AUTOSAR XML (schema 4-2-1)
package /MICROSAR/Dcm_swc
  mode declaration group DcmControlDtcSetting: category=EXPLICIT_ORDER, initial-mode=ENABLEDTCSETTING, on-transition-value=2
    mode ENABLEDTCSETTING: value=0
    mode DISABLEDTCSETTING: value=1
  mode declaration group DcmDiagnosticSessionControl: category=EXPLICIT_ORDER, initial-mode=DefaultSession, on-transition-value=255
    4 x mode:
      DefaultSession: value=1
      ProgrammingSession: value=2
      ExtendedSession: value=3
      NexteerSession: value=126
  mode declaration group BswMEcuResetMod: initial-mode=EcuResetDisabled
    mode EcuResetDisabled
    mode EcuResetEnabled
    mode EcuResetStarted
  data type mapping set DcmMappingSet  # Contains mapping for ModeDeclarationGroups which are provided by Dcm.
    mode-request-type-maps:
      implementation-data-type=Dcm_ControlDtcSettingType, mode-group=DcmControlDtcSetting
      implementation-data-type=Dcm_DiagnosticSessionControlType, mode-group=DcmDiagnosticSessionControl
      implementation-data-type=BswM_BswMEcuResetMod, mode-group=BswMEcuResetMod
package /MICROSAR/Dcm_swc/DataTypes
  32 x impl type:
    Dcm_ConfirmationStatusType: compu {0=DCM_RES_POS_OK, 1=DCM_RES_POS_NOT_OK, 2=DCM_RES_NEG_OK, 3=DCM_RES_NEG_NOT_OK}, implementation-data-type=uint8
    Dcm_OpStatusType: compu {0=DCM_INITIAL, 1=DCM_PENDING, 2=DCM_CANCEL, 3=DCM_FORCE_RCRRP_OK, 64=DCM_FORCE_RCRRP_NOT_OK}, implementation-data-type=uint8
    Dcm_NegativeResponseCodeType: compu {0=DCM_E_POSITIVERESPONSE, 16=DCM_E_GENERALREJECT, 17=DCM_E_SERVICENOTSUPPORTED, 18=DCM_E_SUBFUNCTIONNOTSUPPORTED, 19=DCM_E_INCORRECTMESSAGELENGTHORINVALIDFORMAT, 20=DCM_E_RESPONSETOOLONG, 33=DCM_E_BUSYREPEATREQUEST, 34=DCM_E_CONDITIONSNOTCORRECT, 36=DCM_E_REQUESTSEQUENCEERROR, 37=DCM_E_NORESPONSEFROMSUBNETCOMPONENT, 38=DCM_E_FAILUREPREVENTSEXECUTIONOFREQUESTEDACTION, 49=DCM_E_REQUESTOUTOFRANGE, 51=DCM_E_SECURITYACCESSDENIED, 53=DCM_E_INVALIDKEY, 54=DCM_E_EXCEEDNUMBEROFATTEMPTS, 55=DCM_E_REQUIREDTIMEDELAYNOTEXPIRED, 112=DCM_E_UPLOADDOWNLOADNOTACCEPTED, 113=DCM_E_TRANSFERDATASUSPENDED, 114=DCM_E_GENERALPROGRAMMINGFAILURE, 115=DCM_E_WRONGBLOCKSEQUENCECOUNTER, 120=DCM_E_REQUESTCORRECTLYRECEIVEDRESPONSEPENDING, 126=DCM_E_SUBFUNCTIONNOTSUPPORTEDINACTIVESESSION, 127=DCM_E_SERVICENOTSUPPORTEDINACTIVESESSION, 129=DCM_E_RPMTOOHIGH, 130=DCM_E_RPMTOOLOW, 131=DCM_E_ENGINEISRUNNING, 132=DCM_E_ENGINEISNOTRUNNING, 133=DCM_E_ENGINERUNTIMETOOLOW, 134=DCM_E_TEMPERATURETOOHIGH, 135=DCM_E_TEMPERATURETOOLOW, 136=DCM_E_VEHICLESPEEDTOOHIGH, 137=DCM_E_VEHICLESPEEDTOOLOW, 138=DCM_E_THROTTLE_PEDALTOOHIGH, 139=DCM_E_THROTTLE_PEDALTOOLOW, 140=DCM_E_TRANSMISSIONRANGENOTINNEUTRAL, 141=DCM_E_TRANSMISSIONRANGENOTINGEAR, 143=DCM_E_BRAKESWITCH_NOTCLOSED, 144=DCM_E_SHIFTERLEVERNOTINPARK, 145=DCM_E_TORQUECONVERTERCLUTCHLOCKED, 146=DCM_E_VOLTAGETOOHIGH, 147=DCM_E_VOLTAGETOOLOW, 240..249=DCM_E_VMSCNC_0..DCM_E_VMSCNC_9, 250=DCM_E_VMSCNC_A, 251=DCM_E_VMSCNC_B, 252=DCM_E_VMSCNC_C, 253=DCM_E_VMSCNC_D, 254=DCM_E_VMSCNC_E}, implementation-data-type=uint8
    Dcm_ProtocolType: compu {0=DCM_OBD_ON_CAN, 1=DCM_OBD_ON_FLEXRAY, 2=DCM_OBD_ON_IP, 3=DCM_UDS_ON_CAN, 4=DCM_UDS_ON_FLEXRAY, 5=DCM_UDS_ON_IP, 12=DCM_NO_ACTIVE_PROTOCOL, 240..254=DCM_SUPPLIER_1..DCM_SUPPLIER_15}, implementation-data-type=uint8
    Dcm_RequestKindType: compu {0=DCM_REQ_KIND_NONE, 1=DCM_REQ_KIND_EXTERNAL, 2=DCM_REQ_KIND_ROE}, implementation-data-type=uint8
    Dem_DTCKindType: compu {1=DEM_DTC_KIND_ALL_DTCS, 2=DEM_DTC_KIND_EMISSION_REL_DTCS}, implementation-data-type=uint8
    Dem_DTCGroupType: range raw 0..16777215, implementation-data-type=uint32
    Dem_DTCOriginType: compu {1=DEM_DTC_ORIGIN_PRIMARY_MEMORY, 2=DEM_DTC_ORIGIN_MIRROR_MEMORY, 3=DEM_DTC_ORIGIN_PERMANENT_MEMORY, 4=DEM_DTC_ORIGIN_SECONDARY_MEMORY}, implementation-data-type=uint8
    Dcm_ControlDtcSettingType: compu {0=DCM_ENUM_ENABLEDTCSETTING, 1=DCM_ENUM_DISABLEDTCSETTING}, implementation-data-type=uint8
    Dcm_CommunicationModeType: compu {0=DCM_ENABLE_RX_TX_NORM, 1=DCM_ENABLE_RX_DISABLE_TX_NORM, 2=DCM_DISABLE_RX_ENABLE_TX_NORM, 3=DCM_DISABLE_RX_TX_NORMAL, 4=DCM_ENABLE_RX_TX_NM, 5=DCM_ENABLE_RX_DISABLE_TX_NM, 6=DCM_DISABLE_RX_ENABLE_TX_NM, 7=DCM_DISABLE_RX_TX_NM, 8=DCM_ENABLE_RX_TX_NORM_NM, 9=DCM_ENABLE_RX_DISABLE_TX_NORM_NM, 10=DCM_DISABLE_RX_ENABLE_TX_NORM_NM, 11=DCM_DISABLE_RX_TX_NORM_NM}, implementation-data-type=uint8
    Dcm_Data24ByteType: category=ARRAY, sw-calibration-access=READ-ONLY
      element Dcm_Data24ByteTypeElement: array-size=24, array-size-semantics=FIXED-SIZE, implementation-data-type=uint8
    Dcm_Data4ByteType: category=ARRAY, sw-calibration-access=READ-ONLY
      element Dcm_Data4ByteTypeElement: array-size=4, array-size-semantics=FIXED-SIZE, implementation-data-type=uint8
    Dcm_Data1ByteType: category=ARRAY, sw-calibration-access=READ-ONLY
      element Dcm_Data1ByteTypeElement: array-size=1, array-size-semantics=FIXED-SIZE, implementation-data-type=uint8
    Dcm_Data16ByteType: category=ARRAY, sw-calibration-access=READ-ONLY
      element Dcm_Data16ByteTypeElement: array-size=16, array-size-semantics=FIXED-SIZE, implementation-data-type=uint8
    Dcm_Data1024ByteType: category=ARRAY, sw-calibration-access=READ-ONLY
      element Dcm_Data1024ByteTypeElement: array-size=1024, array-size-semantics=FIXED-SIZE, implementation-data-type=uint8
    Dcm_Data1028ByteType: category=ARRAY, sw-calibration-access=READ-ONLY
      element Dcm_Data1028ByteTypeElement: array-size=1028, array-size-semantics=FIXED-SIZE, implementation-data-type=uint8
    Dcm_Data12ByteType: category=ARRAY, sw-calibration-access=READ-ONLY
      element Dcm_Data12ByteTypeElement: array-size=12, array-size-semantics=FIXED-SIZE, implementation-data-type=uint8
    Dcm_Data18ByteType: category=ARRAY, sw-calibration-access=READ-ONLY
      element Dcm_Data18ByteTypeElement: array-size=18, array-size-semantics=FIXED-SIZE, implementation-data-type=uint8
    Dcm_Data64ByteType: category=ARRAY, sw-calibration-access=READ-ONLY
      element Dcm_Data64ByteTypeElement: array-size=64, array-size-semantics=FIXED-SIZE, implementation-data-type=uint8
    Dcm_Data2ByteType: category=ARRAY, sw-calibration-access=READ-ONLY
      element Dcm_Data2ByteTypeElement: array-size=2, array-size-semantics=FIXED-SIZE, implementation-data-type=uint8
    Dcm_SesCtrlType: compu {1=DCM_DEFAULT_SESSION, 2=DCM_PROGRAMMING_SESSION, 3=DCM_EXTENDED_DIAGNOSTIC_SESSION, 126=DCM_NexteerSession}, implementation-data-type=uint8
    Dcm_DiagnosticSessionControlType: compu {1=DCM_ENUM_DefaultSession, 2=DCM_ENUM_ProgrammingSession, 3=DCM_ENUM_ExtendedSession, 126=DCM_ENUM_NexteerSession}, implementation-data-type=uint8
    Dcm_Data3ByteType: category=ARRAY, sw-calibration-access=READ-ONLY
      element Dcm_Data3ByteTypeElement: array-size=3, array-size-semantics=FIXED-SIZE, implementation-data-type=uint8
    Dcm_Data7ByteType: category=ARRAY, sw-calibration-access=READ-ONLY
      element Dcm_Data7ByteTypeElement: array-size=7, array-size-semantics=FIXED-SIZE, implementation-data-type=uint8
    Dcm_Data25ByteType: category=ARRAY, sw-calibration-access=READ-ONLY
      element Dcm_Data25ByteTypeElement: array-size=25, array-size-semantics=FIXED-SIZE, implementation-data-type=uint8
    Dcm_Data40ByteType: category=ARRAY, sw-calibration-access=READ-ONLY
      element Dcm_Data40ByteTypeElement: array-size=40, array-size-semantics=FIXED-SIZE, implementation-data-type=uint8
    Dcm_Data20ByteType: category=ARRAY, sw-calibration-access=READ-ONLY
      element Dcm_Data20ByteTypeElement: array-size=20, array-size-semantics=FIXED-SIZE, implementation-data-type=uint8
    Dcm_Data10ByteType: category=ARRAY, sw-calibration-access=READ-ONLY
      element Dcm_Data10ByteTypeElement: array-size=10, array-size-semantics=FIXED-SIZE, implementation-data-type=uint8
    Dcm_Data11ByteType: category=ARRAY, sw-calibration-access=READ-ONLY
      element Dcm_Data11ByteTypeElement: array-size=11, array-size-semantics=FIXED-SIZE, implementation-data-type=uint8
    Dcm_Data8ByteType: category=ARRAY, sw-calibration-access=READ-ONLY
      element Dcm_Data8ByteTypeElement: array-size=8, array-size-semantics=FIXED-SIZE, implementation-data-type=uint8
    Dcm_SecLevelType: compu {0=DCM_SEC_LEV_LOCKED, 1=DCM_SEC_LEV_L1, 2=DCM_SEC_LEV_L2}, implementation-data-type=uint8
    Dcm_Data159ByteType: category=ARRAY, sw-calibration-access=READ-ONLY
      element Dcm_Data159ByteTypeElement: array-size=159, array-size-semantics=FIXED-SIZE, implementation-data-type=uint8
package /MICROSAR/Dcm_swc/Interfaces
  mode switch interface DcmControlDtcSetting: is-service=true, service-kind=DIAGNOSTIC-COMMUNICATION-MANAGER
    mode group DcmControlDtcSetting: type=DcmControlDtcSetting
  mode switch interface DcmDiagnosticSessionControl: is-service=true, service-kind=DIAGNOSTIC-COMMUNICATION-MANAGER
    mode group DcmDiagnosticSessionControl: type=DcmDiagnosticSessionControl
  100 x client server interface, all with is-service=true, service-kind=DIAGNOSTIC-COMMUNICATION-MANAGER:
    DCMServices
      7 x operation:
        GetActiveProtocol: possible-error=E_OK
          arg ActiveProtocol: type=Dcm_ProtocolType, direction=OUT
        GetSesCtrlType: possible-error=E_OK
          arg SesCtrlType: type=Dcm_SesCtrlType, direction=OUT
        ResetToDefaultSession: possible-error=E_OK
        SetActiveDiagnostic: possible-error=E_OK
          arg active: type=boolean, direction=IN
        GetRequestKind: possible-error=DCMServices/E_NOT_OK
          arg TesterSourceAddress: type=uint16, direction=IN
          arg RequestKind: type=Dcm_RequestKindType, direction=OUT
        GetSecurityLevel: possible-error=E_OK
          arg SecLevel: type=Dcm_SecLevelType, direction=OUT
        GetSecurityLevelFixedBytes: possible-error=[DCMServices/E_NOT_OK, DCM_E_BUFFERTOOLOW]
          arg SecLevel: type=Dcm_SecLevelType, direction=IN
          arg FixedBytes: type=Dcm_Data12ByteType, direction=OUT
          arg BufferSize: type=uint8, direction=INOUT
      error E_OK: error-code=0
      error E_NOT_OK: error-code=1
      error DCM_E_BUFFERTOOLOW: error-code=42
    CallbackDCMRequestServices
      operation StartProtocol: possible-error=[CallbackDCMRequestServices/E_NOT_OK, E_PROTOCOL_NOT_ALLOWED]
        arg ProtocolID: type=Dcm_ProtocolType, direction=IN
      error E_NOT_OK: error-code=1
      error E_PROTOCOL_NOT_ALLOWED: error-code=5
    DataServices_Data_Dummy
      5 x operation, all with possible-error=[DataServices_Data_Dummy/E_NOT_OK, DataServices_Data_Dummy/DCM_E_PENDING]:
        ReadData
          arg OpStatus: type=Dcm_OpStatusType, direction=IN
          arg Data: type=Dcm_Data1ByteType, direction=OUT
        ReadDataLength
          arg OpStatus: type=Dcm_OpStatusType, direction=IN
          arg DataLength: type=uint16, direction=OUT
        WriteData
          4 x arg:
            Data: type=Dcm_Data1ByteType, direction=IN
            DataLength: type=uint16, direction=IN
            OpStatus: type=Dcm_OpStatusType, direction=IN
            ErrorCode: type=Dcm_NegativeResponseCodeType, direction=OUT
        ReturnControlToECU
          arg OpStatus: type=Dcm_OpStatusType, direction=IN
          arg ErrorCode: type=Dcm_NegativeResponseCodeType, direction=OUT
        ShortTermAdjustment
          4 x arg:
            Data: type=Dcm_Data1ByteType, direction=IN
            DataLength: type=uint16, direction=IN
            OpStatus: type=Dcm_OpStatusType, direction=IN
            ErrorCode: type=Dcm_NegativeResponseCodeType, direction=OUT
      error E_NOT_OK: error-code=1
      error DCM_E_PENDING: error-code=10
    DataServices_DIDRange_NexteerDidRangeFD00toFD39
      operation ReadDidData: possible-error=[DataServices_DIDRange_NexteerDidRangeFD00toFD39/E_NOT_OK, DataServices_DIDRange_NexteerDidRangeFD00toFD39/DCM_E_PENDING]
        5 x arg:
          DID: type=uint16, direction=IN
          Data: type=Dcm_Data1024ByteType, direction=OUT
          OpStatus: type=Dcm_OpStatusType, direction=IN
          DataLength: type=uint16, direction=OUT
          ErrorCode: type=Dcm_NegativeResponseCodeType, direction=OUT
      operation WriteDidData: possible-error=[DataServices_DIDRange_NexteerDidRangeFD00toFD39/E_NOT_OK, DataServices_DIDRange_NexteerDidRangeFD00toFD39/DCM_E_PENDING]
        5 x arg:
          DID: type=uint16, direction=IN
          Data: type=Dcm_Data1024ByteType, direction=IN
          OpStatus: type=Dcm_OpStatusType, direction=IN
          DataLength: type=uint16, direction=IN
          ErrorCode: type=Dcm_NegativeResponseCodeType, direction=OUT
      error E_NOT_OK: error-code=1
      error DCM_E_PENDING: error-code=10
    DataServices_DIDRange_NexteerDidRangeFD43toFEFF
      operation ReadDidData: possible-error=[DataServices_DIDRange_NexteerDidRangeFD43toFEFF/E_NOT_OK, DataServices_DIDRange_NexteerDidRangeFD43toFEFF/DCM_E_PENDING]
        5 x arg:
          DID: type=uint16, direction=IN
          Data: type=Dcm_Data1024ByteType, direction=OUT
          OpStatus: type=Dcm_OpStatusType, direction=IN
          DataLength: type=uint16, direction=OUT
          ErrorCode: type=Dcm_NegativeResponseCodeType, direction=OUT
      operation WriteDidData: possible-error=[DataServices_DIDRange_NexteerDidRangeFD43toFEFF/E_NOT_OK, DataServices_DIDRange_NexteerDidRangeFD43toFEFF/DCM_E_PENDING]
        5 x arg:
          DID: type=uint16, direction=IN
          Data: type=Dcm_Data1024ByteType, direction=IN
          OpStatus: type=Dcm_OpStatusType, direction=IN
          DataLength: type=uint16, direction=IN
          ErrorCode: type=Dcm_NegativeResponseCodeType, direction=OUT
      error E_NOT_OK: error-code=1
      error DCM_E_PENDING: error-code=10
    DcmIf
      operation DcmEnableDTCSetting: possible-error=[DEM_CONTROL_DTC_SETTING_N_OK, DEM_CONTROL_DTC_WRONG_DTCGROUP]
        arg DTCGroup: type=Dem_DTCGroupType, direction=IN
        arg DTCKind: type=Dem_DTCKindType, direction=IN
      operation DcmGetExtendedDataRecordByDTC: possible-error=[DEM_RECORD_WRONG_DTC, DEM_RECORD_WRONG_DTCORIGIN, DEM_RECORD_WRONG_NUMBER, DEM_RECORD_WRONG_BUFFERSIZE, DEM_RECORD_PENDING]
        5 x arg:
          DTC: type=uint32, direction=IN
          DTCOrigin: type=Dem_DTCOriginType, direction=IN
          ExtendedDataNumber: type=uint8, direction=IN
          DestBuffer: type=uint8, direction=OUT
          BufSize: type=uint16, direction=INOUT
      7 x error:
        DEM_CONTROL_DTC_SETTING_N_OK: error-code=1
        DEM_CONTROL_DTC_WRONG_DTCGROUP: error-code=2
        DEM_RECORD_WRONG_DTC: error-code=1
        DEM_RECORD_WRONG_DTCORIGIN: error-code=2
        DEM_RECORD_WRONG_NUMBER: error-code=3
        DEM_RECORD_WRONG_BUFFERSIZE: error-code=4
        DEM_RECORD_PENDING: error-code=5
    RoutineServices_RTN_Nexteer_FD70_Clear_Nexteer_Trouble_Codes
      operation Start: possible-error=[RoutineServices_RTN_Nexteer_FD70_Clear_Nexteer_Trouble_Codes/E_NOT_OK, RoutineServices_RTN_Nexteer_FD70_Clear_Nexteer_Trouble_Codes/DCM_E_PENDING, RoutineServices_RTN_Nexteer_FD70_Clear_Nexteer_Trouble_Codes/DCM_E_FORCE_RCRRP]
        arg OpStatus: type=Dcm_OpStatusType, direction=IN
        arg ErrorCode: type=Dcm_NegativeResponseCodeType, direction=OUT
      error E_NOT_OK: error-code=1
      error DCM_E_PENDING: error-code=10
      error DCM_E_FORCE_RCRRP: error-code=12
    RoutineServices_RTN_Nexteer_FDF0_Current_Gain_Auto_Trim
      operation Start: possible-error=[RoutineServices_RTN_Nexteer_FDF0_Current_Gain_Auto_Trim/E_NOT_OK, RoutineServices_RTN_Nexteer_FDF0_Current_Gain_Auto_Trim/DCM_E_PENDING, RoutineServices_RTN_Nexteer_FDF0_Current_Gain_Auto_Trim/DCM_E_FORCE_RCRRP]
        arg OpStatus: type=Dcm_OpStatusType, direction=IN
        arg ErrorCode: type=Dcm_NegativeResponseCodeType, direction=OUT
      operation RequestResults: possible-error=[RoutineServices_RTN_Nexteer_FDF0_Current_Gain_Auto_Trim/E_NOT_OK, RoutineServices_RTN_Nexteer_FDF0_Current_Gain_Auto_Trim/DCM_E_PENDING, RoutineServices_RTN_Nexteer_FDF0_Current_Gain_Auto_Trim/DCM_E_FORCE_RCRRP]
        arg OpStatus: type=Dcm_OpStatusType, direction=IN
        arg Data: type=uint8, direction=OUT
        arg ErrorCode: type=Dcm_NegativeResponseCodeType, direction=OUT
      error E_NOT_OK: error-code=1
      error DCM_E_PENDING: error-code=10
      error DCM_E_FORCE_RCRRP: error-code=12
    RoutineServices_RTN_Nexteer_FDF1_Current_Offset_Auto_Trim
      operation Start: possible-error=[RoutineServices_RTN_Nexteer_FDF1_Current_Offset_Auto_Trim/E_NOT_OK, RoutineServices_RTN_Nexteer_FDF1_Current_Offset_Auto_Trim/DCM_E_PENDING, RoutineServices_RTN_Nexteer_FDF1_Current_Offset_Auto_Trim/DCM_E_FORCE_RCRRP]
        arg OpStatus: type=Dcm_OpStatusType, direction=IN
        arg ErrorCode: type=Dcm_NegativeResponseCodeType, direction=OUT
      operation RequestResults: possible-error=[RoutineServices_RTN_Nexteer_FDF1_Current_Offset_Auto_Trim/E_NOT_OK, RoutineServices_RTN_Nexteer_FDF1_Current_Offset_Auto_Trim/DCM_E_PENDING, RoutineServices_RTN_Nexteer_FDF1_Current_Offset_Auto_Trim/DCM_E_FORCE_RCRRP]
        arg OpStatus: type=Dcm_OpStatusType, direction=IN
        arg Data: type=uint8, direction=OUT
        arg ErrorCode: type=Dcm_NegativeResponseCodeType, direction=OUT
      error E_NOT_OK: error-code=1
      error DCM_E_PENDING: error-code=10
      error DCM_E_FORCE_RCRRP: error-code=12
    RoutineServices_RTN_Nexteer_F100_Request_System_State_Enable
      operation Start: possible-error=[RoutineServices_RTN_Nexteer_F100_Request_System_State_Enable/E_NOT_OK, RoutineServices_RTN_Nexteer_F100_Request_System_State_Enable/DCM_E_PENDING, RoutineServices_RTN_Nexteer_F100_Request_System_State_Enable/DCM_E_FORCE_RCRRP]
        arg OpStatus: type=Dcm_OpStatusType, direction=IN
        arg ErrorCode: type=Dcm_NegativeResponseCodeType, direction=OUT
      operation RequestResults: possible-error=[RoutineServices_RTN_Nexteer_F100_Request_System_State_Enable/E_NOT_OK, RoutineServices_RTN_Nexteer_F100_Request_System_State_Enable/DCM_E_PENDING, RoutineServices_RTN_Nexteer_F100_Request_System_State_Enable/DCM_E_FORCE_RCRRP]
        arg OpStatus: type=Dcm_OpStatusType, direction=IN
        arg Data: type=uint8, direction=OUT
        arg ErrorCode: type=Dcm_NegativeResponseCodeType, direction=OUT
      operation Stop: possible-error=[RoutineServices_RTN_Nexteer_F100_Request_System_State_Enable/E_NOT_OK, RoutineServices_RTN_Nexteer_F100_Request_System_State_Enable/DCM_E_PENDING, RoutineServices_RTN_Nexteer_F100_Request_System_State_Enable/DCM_E_FORCE_RCRRP]
        arg OpStatus: type=Dcm_OpStatusType, direction=IN
        arg ErrorCode: type=Dcm_NegativeResponseCodeType, direction=OUT
      error E_NOT_OK: error-code=1
      error DCM_E_PENDING: error-code=10
      error DCM_E_FORCE_RCRRP: error-code=12
    RoutineServices_RTN_Nexteer_F151_Defeat_Loss_of_Assist_Scale
      operation Start: possible-error=[RoutineServices_RTN_Nexteer_F151_Defeat_Loss_of_Assist_Scale/E_NOT_OK, RoutineServices_RTN_Nexteer_F151_Defeat_Loss_of_Assist_Scale/DCM_E_PENDING, RoutineServices_RTN_Nexteer_F151_Defeat_Loss_of_Assist_Scale/DCM_E_FORCE_RCRRP]
        arg OpStatus: type=Dcm_OpStatusType, direction=IN
        arg ErrorCode: type=Dcm_NegativeResponseCodeType, direction=OUT
      operation Stop: possible-error=[RoutineServices_RTN_Nexteer_F151_Defeat_Loss_of_Assist_Scale/E_NOT_OK, RoutineServices_RTN_Nexteer_F151_Defeat_Loss_of_Assist_Scale/DCM_E_PENDING, RoutineServices_RTN_Nexteer_F151_Defeat_Loss_of_Assist_Scale/DCM_E_FORCE_RCRRP]
        arg OpStatus: type=Dcm_OpStatusType, direction=IN
        arg ErrorCode: type=Dcm_NegativeResponseCodeType, direction=OUT
      operation RequestResults: possible-error=[RoutineServices_RTN_Nexteer_F151_Defeat_Loss_of_Assist_Scale/E_NOT_OK, RoutineServices_RTN_Nexteer_F151_Defeat_Loss_of_Assist_Scale/DCM_E_PENDING, RoutineServices_RTN_Nexteer_F151_Defeat_Loss_of_Assist_Scale/DCM_E_FORCE_RCRRP]
        arg OpStatus: type=Dcm_OpStatusType, direction=IN
        arg Data: type=uint8, direction=OUT
        arg ErrorCode: type=Dcm_NegativeResponseCodeType, direction=OUT
      error E_NOT_OK: error-code=1
      error DCM_E_PENDING: error-code=10
      error DCM_E_FORCE_RCRRP: error-code=12
    RoutineServices_RTN_Nexteer_FDC2_Software_Based_Motor_Calibration
      operation Start: possible-error=[RoutineServices_RTN_Nexteer_FDC2_Software_Based_Motor_Calibration/E_NOT_OK, RoutineServices_RTN_Nexteer_FDC2_Software_Based_Motor_Calibration/DCM_E_PENDING, RoutineServices_RTN_Nexteer_FDC2_Software_Based_Motor_Calibration/DCM_E_FORCE_RCRRP]
        arg OpStatus: type=Dcm_OpStatusType, direction=IN
        arg ErrorCode: type=Dcm_NegativeResponseCodeType, direction=OUT
      operation Stop: possible-error=[RoutineServices_RTN_Nexteer_FDC2_Software_Based_Motor_Calibration/E_NOT_OK, RoutineServices_RTN_Nexteer_FDC2_Software_Based_Motor_Calibration/DCM_E_PENDING, RoutineServices_RTN_Nexteer_FDC2_Software_Based_Motor_Calibration/DCM_E_FORCE_RCRRP]
        arg OpStatus: type=Dcm_OpStatusType, direction=IN
        arg ErrorCode: type=Dcm_NegativeResponseCodeType, direction=OUT
      operation RequestResults: possible-error=[RoutineServices_RTN_Nexteer_FDC2_Software_Based_Motor_Calibration/E_NOT_OK, RoutineServices_RTN_Nexteer_FDC2_Software_Based_Motor_Calibration/DCM_E_PENDING, RoutineServices_RTN_Nexteer_FDC2_Software_Based_Motor_Calibration/DCM_E_FORCE_RCRRP]
        arg OpStatus: type=Dcm_OpStatusType, direction=IN
        arg Data: type=uint8, direction=OUT
        arg ErrorCode: type=Dcm_NegativeResponseCodeType, direction=OUT
      error E_NOT_OK: error-code=1
      error DCM_E_PENDING: error-code=10
      error DCM_E_FORCE_RCRRP: error-code=12
    RoutineServices_RTN_Nexteer_FD81_Handwheel_Angle_1_Auto_Trim
      operation Start: possible-error=[RoutineServices_RTN_Nexteer_FD81_Handwheel_Angle_1_Auto_Trim/E_NOT_OK, RoutineServices_RTN_Nexteer_FD81_Handwheel_Angle_1_Auto_Trim/DCM_E_PENDING, RoutineServices_RTN_Nexteer_FD81_Handwheel_Angle_1_Auto_Trim/DCM_E_FORCE_RCRRP]
        arg OpStatus: type=Dcm_OpStatusType, direction=IN
        arg ErrorCode: type=Dcm_NegativeResponseCodeType, direction=OUT
      error E_NOT_OK: error-code=1
      error DCM_E_PENDING: error-code=10
      error DCM_E_FORCE_RCRRP: error-code=12
    RoutineServices_RTN_Nexteer_FD85_Handwheel_Angle_1_Clear_Trim
      operation Start: possible-error=[RoutineServices_RTN_Nexteer_FD85_Handwheel_Angle_1_Clear_Trim/E_NOT_OK, RoutineServices_RTN_Nexteer_FD85_Handwheel_Angle_1_Clear_Trim/DCM_E_PENDING, RoutineServices_RTN_Nexteer_FD85_Handwheel_Angle_1_Clear_Trim/DCM_E_FORCE_RCRRP]
        arg OpStatus: type=Dcm_OpStatusType, direction=IN
        arg ErrorCode: type=Dcm_NegativeResponseCodeType, direction=OUT
      error E_NOT_OK: error-code=1
      error DCM_E_PENDING: error-code=10
      error DCM_E_FORCE_RCRRP: error-code=12
    RoutineServices_RTN_Nexteer_FDA0_Handwheel_Torque_Sensor_0_Auto_Trim
      operation Start: possible-error=[RoutineServices_RTN_Nexteer_FDA0_Handwheel_Torque_Sensor_0_Auto_Trim/E_NOT_OK, RoutineServices_RTN_Nexteer_FDA0_Handwheel_Torque_Sensor_0_Auto_Trim/DCM_E_PENDING, RoutineServices_RTN_Nexteer_FDA0_Handwheel_Torque_Sensor_0_Auto_Trim/DCM_E_FORCE_RCRRP]
        arg OpStatus: type=Dcm_OpStatusType, direction=IN
        arg ErrorCode: type=Dcm_NegativeResponseCodeType, direction=OUT
      error E_NOT_OK: error-code=1
      error DCM_E_PENDING: error-code=10
      error DCM_E_FORCE_RCRRP: error-code=12
    RoutineServices_RTN_Nexteer_FDA1_Handwheel_Torque_Sensor_1_Auto_Trim
      operation Start: possible-error=[RoutineServices_RTN_Nexteer_FDA1_Handwheel_Torque_Sensor_1_Auto_Trim/E_NOT_OK, RoutineServices_RTN_Nexteer_FDA1_Handwheel_Torque_Sensor_1_Auto_Trim/DCM_E_PENDING, RoutineServices_RTN_Nexteer_FDA1_Handwheel_Torque_Sensor_1_Auto_Trim/DCM_E_FORCE_RCRRP]
        arg OpStatus: type=Dcm_OpStatusType, direction=IN
        arg ErrorCode: type=Dcm_NegativeResponseCodeType, direction=OUT
      error E_NOT_OK: error-code=1
      error DCM_E_PENDING: error-code=10
      error DCM_E_FORCE_RCRRP: error-code=12
    RoutineServices_RTN_Nexteer_FDA8_Handwheel_Torque_Sensor_0_Clear_Trim
      operation Start: possible-error=[RoutineServices_RTN_Nexteer_FDA8_Handwheel_Torque_Sensor_0_Clear_Trim/E_NOT_OK, RoutineServices_RTN_Nexteer_FDA8_Handwheel_Torque_Sensor_0_Clear_Trim/DCM_E_PENDING, RoutineServices_RTN_Nexteer_FDA8_Handwheel_Torque_Sensor_0_Clear_Trim/DCM_E_FORCE_RCRRP]
        arg OpStatus: type=Dcm_OpStatusType, direction=IN
        arg ErrorCode: type=Dcm_NegativeResponseCodeType, direction=OUT
      error E_NOT_OK: error-code=1
      error DCM_E_PENDING: error-code=10
      error DCM_E_FORCE_RCRRP: error-code=12
    RoutineServices_RTN_Nexteer_FDA9_Handwheel_Torque_Sensor_1_Clear_Trim
      operation Start: possible-error=[RoutineServices_RTN_Nexteer_FDA9_Handwheel_Torque_Sensor_1_Clear_Trim/E_NOT_OK, RoutineServices_RTN_Nexteer_FDA9_Handwheel_Torque_Sensor_1_Clear_Trim/DCM_E_PENDING, RoutineServices_RTN_Nexteer_FDA9_Handwheel_Torque_Sensor_1_Clear_Trim/DCM_E_FORCE_RCRRP]
        arg OpStatus: type=Dcm_OpStatusType, direction=IN
        arg ErrorCode: type=Dcm_NegativeResponseCodeType, direction=OUT
      error E_NOT_OK: error-code=1
      error DCM_E_PENDING: error-code=10
      error DCM_E_FORCE_RCRRP: error-code=12
    RoutineServices_RTN_Nexteer_FE20_Motor_Velocity_Control
      operation Start: possible-error=[RoutineServices_RTN_Nexteer_FE20_Motor_Velocity_Control/E_NOT_OK, RoutineServices_RTN_Nexteer_FE20_Motor_Velocity_Control/DCM_E_PENDING, RoutineServices_RTN_Nexteer_FE20_Motor_Velocity_Control/DCM_E_FORCE_RCRRP]
        arg Data: type=Dcm_Data8ByteType, direction=IN
        arg OpStatus: type=Dcm_OpStatusType, direction=IN
        arg ErrorCode: type=Dcm_NegativeResponseCodeType, direction=OUT
      operation Stop: possible-error=[RoutineServices_RTN_Nexteer_FE20_Motor_Velocity_Control/E_NOT_OK, RoutineServices_RTN_Nexteer_FE20_Motor_Velocity_Control/DCM_E_PENDING, RoutineServices_RTN_Nexteer_FE20_Motor_Velocity_Control/DCM_E_FORCE_RCRRP]
        arg Data: type=Dcm_Data4ByteType, direction=IN
        arg OpStatus: type=Dcm_OpStatusType, direction=IN
        arg ErrorCode: type=Dcm_NegativeResponseCodeType, direction=OUT
      error E_NOT_OK: error-code=1
      error DCM_E_PENDING: error-code=10
      error DCM_E_FORCE_RCRRP: error-code=12
    DataServices_Data_Nexteer_IoControl_FD40_Manual_Torque_Command
      4 x operation, all with possible-error=[DataServices_Data_Nexteer_IoControl_FD40_Manual_Torque_Command/E_NOT_OK, DataServices_Data_Nexteer_IoControl_FD40_Manual_Torque_Command/DCM_E_PENDING]:
        ReadData
          arg OpStatus: type=Dcm_OpStatusType, direction=IN
          arg Data: type=Dcm_Data4ByteType, direction=OUT
        ReadDataLength
          arg OpStatus: type=Dcm_OpStatusType, direction=IN
          arg DataLength: type=uint16, direction=OUT
        ReturnControlToECU
          arg OpStatus: type=Dcm_OpStatusType, direction=IN
          arg ErrorCode: type=Dcm_NegativeResponseCodeType, direction=OUT
        ShortTermAdjustment
          4 x arg:
            Data: type=Dcm_Data4ByteType, direction=IN
            DataLength: type=uint16, direction=IN
            OpStatus: type=Dcm_OpStatusType, direction=IN
            ErrorCode: type=Dcm_NegativeResponseCodeType, direction=OUT
      error E_NOT_OK: error-code=1
      error DCM_E_PENDING: error-code=10
    DataServices_Data_Nexteer_IoControl_FD41_Assist_Linear_Gain
      4 x operation, all with possible-error=[DataServices_Data_Nexteer_IoControl_FD41_Assist_Linear_Gain/E_NOT_OK, DataServices_Data_Nexteer_IoControl_FD41_Assist_Linear_Gain/DCM_E_PENDING]:
        ReadData
          arg OpStatus: type=Dcm_OpStatusType, direction=IN
          arg Data: type=Dcm_Data4ByteType, direction=OUT
        ReadDataLength
          arg OpStatus: type=Dcm_OpStatusType, direction=IN
          arg DataLength: type=uint16, direction=OUT
        ReturnControlToECU
          arg OpStatus: type=Dcm_OpStatusType, direction=IN
          arg ErrorCode: type=Dcm_NegativeResponseCodeType, direction=OUT
        ShortTermAdjustment
          4 x arg:
            Data: type=Dcm_Data4ByteType, direction=IN
            DataLength: type=uint16, direction=IN
            OpStatus: type=Dcm_OpStatusType, direction=IN
            ErrorCode: type=Dcm_NegativeResponseCodeType, direction=OUT
      error E_NOT_OK: error-code=1
      error DCM_E_PENDING: error-code=10
    RoutineServices_RTN_Nexteer_F119_Defeat_Duty_Cycle_Thermal_Protection
      operation Start: possible-error=[RoutineServices_RTN_Nexteer_F119_Defeat_Duty_Cycle_Thermal_Protection/E_NOT_OK, RoutineServices_RTN_Nexteer_F119_Defeat_Duty_Cycle_Thermal_Protection/DCM_E_PENDING, RoutineServices_RTN_Nexteer_F119_Defeat_Duty_Cycle_Thermal_Protection/DCM_E_FORCE_RCRRP]
        arg OpStatus: type=Dcm_OpStatusType, direction=IN
        arg ErrorCode: type=Dcm_NegativeResponseCodeType, direction=OUT
      operation Stop: possible-error=[RoutineServices_RTN_Nexteer_F119_Defeat_Duty_Cycle_Thermal_Protection/E_NOT_OK, RoutineServices_RTN_Nexteer_F119_Defeat_Duty_Cycle_Thermal_Protection/DCM_E_PENDING, RoutineServices_RTN_Nexteer_F119_Defeat_Duty_Cycle_Thermal_Protection/DCM_E_FORCE_RCRRP]
        arg OpStatus: type=Dcm_OpStatusType, direction=IN
        arg ErrorCode: type=Dcm_NegativeResponseCodeType, direction=OUT
      operation RequestResults: possible-error=[RoutineServices_RTN_Nexteer_F119_Defeat_Duty_Cycle_Thermal_Protection/E_NOT_OK, RoutineServices_RTN_Nexteer_F119_Defeat_Duty_Cycle_Thermal_Protection/DCM_E_PENDING, RoutineServices_RTN_Nexteer_F119_Defeat_Duty_Cycle_Thermal_Protection/DCM_E_FORCE_RCRRP]
        arg OpStatus: type=Dcm_OpStatusType, direction=IN
        arg Data: type=uint8, direction=OUT
        arg ErrorCode: type=Dcm_NegativeResponseCodeType, direction=OUT
      error E_NOT_OK: error-code=1
      error DCM_E_PENDING: error-code=10
      error DCM_E_FORCE_RCRRP: error-code=12
    ServiceRequestNotification
      operation Indication: possible-error=[ServiceRequestNotification/E_NOT_OK, E_REQUEST_NOT_ACCEPTED]
        6 x arg:
          SID: type=uint8, direction=IN
          RequestData: type=Dcm_Data1028ByteType, direction=IN
          DataSize: type=uint16, direction=IN
          ReqType: type=uint8, direction=IN
          SourceAddress: type=uint16, direction=IN
          ErrorCode: type=Dcm_NegativeResponseCodeType, direction=OUT
      operation Confirmation: possible-error=ServiceRequestNotification/E_NOT_OK
        4 x arg, all with direction=IN:
          SID: type=uint8
          ReqType: type=uint8
          SourceAddress: type=uint16
          ConfirmationStatus: type=Dcm_ConfirmationStatusType
      error E_NOT_OK: error-code=1
      error E_REQUEST_NOT_ACCEPTED: error-code=8
    SecurityAccess_Un_locked_L1
      operation GetSeed: possible-error=[SecurityAccess_Un_locked_L1/E_NOT_OK, SecurityAccess_Un_locked_L1/DCM_E_PENDING]
        arg OpStatus: type=Dcm_OpStatusType, direction=IN
        arg Seed: type=Dcm_Data16ByteType, direction=OUT
        arg ErrorCode: type=Dcm_NegativeResponseCodeType, direction=OUT
      operation CompareKey: possible-error=[SecurityAccess_Un_locked_L1/E_NOT_OK, SecurityAccess_Un_locked_L1/DCM_E_PENDING, SecurityAccess_Un_locked_L1/DCM_E_COMPARE_KEY_FAILED]
        arg Key: type=Dcm_Data18ByteType, direction=IN
        arg OpStatus: type=Dcm_OpStatusType, direction=IN
        arg ErrorCode: type=Dcm_NegativeResponseCodeType, direction=OUT
      error E_NOT_OK: error-code=1
      error DCM_E_PENDING: error-code=10
      error DCM_E_COMPARE_KEY_FAILED: error-code=11
    DataServices_DID_F113_ECU_Delivery_Assembly_Number
      operation ReadData: possible-error=[DataServices_DID_F113_ECU_Delivery_Assembly_Number/E_NOT_OK, DataServices_DID_F113_ECU_Delivery_Assembly_Number/DCM_E_PENDING]
        arg OpStatus: type=Dcm_OpStatusType, direction=IN
        arg Data: type=Dcm_Data24ByteType, direction=OUT
      operation ConditionCheckRead: possible-error=[DataServices_DID_F113_ECU_Delivery_Assembly_Number/E_NOT_OK, DataServices_DID_F113_ECU_Delivery_Assembly_Number/DCM_E_PENDING]
        arg OpStatus: type=Dcm_OpStatusType, direction=IN
        arg ErrorCode: type=Dcm_NegativeResponseCodeType, direction=OUT
      operation WriteData: possible-error=[DataServices_DID_F113_ECU_Delivery_Assembly_Number/E_NOT_OK, DataServices_DID_F113_ECU_Delivery_Assembly_Number/DCM_E_PENDING]
        arg Data: type=Dcm_Data24ByteType, direction=IN
        arg OpStatus: type=Dcm_OpStatusType, direction=IN
        arg ErrorCode: type=Dcm_NegativeResponseCodeType, direction=OUT
      error E_NOT_OK: error-code=1
      error DCM_E_PENDING: error-code=10
    DataServices_DID_F111_ECU_Core_Assembly_Number
      operation ReadData: possible-error=[DataServices_DID_F111_ECU_Core_Assembly_Number/E_NOT_OK, DataServices_DID_F111_ECU_Core_Assembly_Number/DCM_E_PENDING]
        arg OpStatus: type=Dcm_OpStatusType, direction=IN
        arg Data: type=Dcm_Data24ByteType, direction=OUT
      operation ConditionCheckRead: possible-error=[DataServices_DID_F111_ECU_Core_Assembly_Number/E_NOT_OK, DataServices_DID_F111_ECU_Core_Assembly_Number/DCM_E_PENDING]
        arg OpStatus: type=Dcm_OpStatusType, direction=IN
        arg ErrorCode: type=Dcm_NegativeResponseCodeType, direction=OUT
      operation WriteData: possible-error=[DataServices_DID_F111_ECU_Core_Assembly_Number/E_NOT_OK, DataServices_DID_F111_ECU_Core_Assembly_Number/DCM_E_PENDING]
        arg Data: type=Dcm_Data24ByteType, direction=IN
        arg OpStatus: type=Dcm_OpStatusType, direction=IN
        arg ErrorCode: type=Dcm_NegativeResponseCodeType, direction=OUT
      error E_NOT_OK: error-code=1
      error DCM_E_PENDING: error-code=10
    DataServices_DID_DE00_VehicleData
      operation ReadData: possible-error=[DataServices_DID_DE00_VehicleData/E_NOT_OK, DataServices_DID_DE00_VehicleData/DCM_E_PENDING]
        arg OpStatus: type=Dcm_OpStatusType, direction=IN
        arg Data: type=Dcm_Data24ByteType, direction=OUT
      operation ConditionCheckRead: possible-error=[DataServices_DID_DE00_VehicleData/E_NOT_OK, DataServices_DID_DE00_VehicleData/DCM_E_PENDING]
        arg OpStatus: type=Dcm_OpStatusType, direction=IN
        arg ErrorCode: type=Dcm_NegativeResponseCodeType, direction=OUT
      operation WriteData: possible-error=[DataServices_DID_DE00_VehicleData/E_NOT_OK, DataServices_DID_DE00_VehicleData/DCM_E_PENDING]
        arg Data: type=Dcm_Data24ByteType, direction=IN
        arg OpStatus: type=Dcm_OpStatusType, direction=IN
        arg ErrorCode: type=Dcm_NegativeResponseCodeType, direction=OUT
      error E_NOT_OK: error-code=1
      error DCM_E_PENDING: error-code=10
    DataServices_DID_F124_ECU_Calibration_Data_1_Number
      operation ReadData: possible-error=[DataServices_DID_F124_ECU_Calibration_Data_1_Number/E_NOT_OK, DataServices_DID_F124_ECU_Calibration_Data_1_Number/DCM_E_PENDING]
        arg OpStatus: type=Dcm_OpStatusType, direction=IN
        arg Data: type=Dcm_Data24ByteType, direction=OUT
      operation ConditionCheckRead: possible-error=[DataServices_DID_F124_ECU_Calibration_Data_1_Number/E_NOT_OK, DataServices_DID_F124_ECU_Calibration_Data_1_Number/DCM_E_PENDING]
        arg OpStatus: type=Dcm_OpStatusType, direction=IN
        arg ErrorCode: type=Dcm_NegativeResponseCodeType, direction=OUT
      error E_NOT_OK: error-code=1
      error DCM_E_PENDING: error-code=10
    DataServices_DID_DE02_FeatureConfig
      operation ReadData: possible-error=[DataServices_DID_DE02_FeatureConfig/E_NOT_OK, DataServices_DID_DE02_FeatureConfig/DCM_E_PENDING]
        arg OpStatus: type=Dcm_OpStatusType, direction=IN
        arg Data: type=Dcm_Data24ByteType, direction=OUT
      operation ConditionCheckRead: possible-error=[DataServices_DID_DE02_FeatureConfig/E_NOT_OK, DataServices_DID_DE02_FeatureConfig/DCM_E_PENDING]
        arg OpStatus: type=Dcm_OpStatusType, direction=IN
        arg ErrorCode: type=Dcm_NegativeResponseCodeType, direction=OUT
      operation WriteData: possible-error=[DataServices_DID_DE02_FeatureConfig/E_NOT_OK, DataServices_DID_DE02_FeatureConfig/DCM_E_PENDING]
        arg Data: type=Dcm_Data24ByteType, direction=IN
        arg OpStatus: type=Dcm_OpStatusType, direction=IN
        arg ErrorCode: type=Dcm_NegativeResponseCodeType, direction=OUT
      error E_NOT_OK: error-code=1
      error DCM_E_PENDING: error-code=10
    DataServices_DID_DE01_FIHSwFeatureConfig
      operation ReadData: possible-error=[DataServices_DID_DE01_FIHSwFeatureConfig/E_NOT_OK, DataServices_DID_DE01_FIHSwFeatureConfig/DCM_E_PENDING]
        arg OpStatus: type=Dcm_OpStatusType, direction=IN
        arg Data: type=Dcm_Data24ByteType, direction=OUT
      operation ConditionCheckRead: possible-error=[DataServices_DID_DE01_FIHSwFeatureConfig/E_NOT_OK, DataServices_DID_DE01_FIHSwFeatureConfig/DCM_E_PENDING]
        arg OpStatus: type=Dcm_OpStatusType, direction=IN
        arg ErrorCode: type=Dcm_NegativeResponseCodeType, direction=OUT
      operation WriteData: possible-error=[DataServices_DID_DE01_FIHSwFeatureConfig/E_NOT_OK, DataServices_DID_DE01_FIHSwFeatureConfig/DCM_E_PENDING]
        arg Data: type=Dcm_Data24ByteType, direction=IN
        arg OpStatus: type=Dcm_OpStatusType, direction=IN
        arg ErrorCode: type=Dcm_NegativeResponseCodeType, direction=OUT
      error E_NOT_OK: error-code=1
      error DCM_E_PENDING: error-code=10
    DataServices_DID_DE03_Enable_DisableDTCs
      operation ReadData: possible-error=[DataServices_DID_DE03_Enable_DisableDTCs/E_NOT_OK, DataServices_DID_DE03_Enable_DisableDTCs/DCM_E_PENDING]
        arg OpStatus: type=Dcm_OpStatusType, direction=IN
        arg Data: type=Dcm_Data64ByteType, direction=OUT
      operation ConditionCheckRead: possible-error=[DataServices_DID_DE03_Enable_DisableDTCs/E_NOT_OK, DataServices_DID_DE03_Enable_DisableDTCs/DCM_E_PENDING]
        arg OpStatus: type=Dcm_OpStatusType, direction=IN
        arg ErrorCode: type=Dcm_NegativeResponseCodeType, direction=OUT
      operation WriteData: possible-error=[DataServices_DID_DE03_Enable_DisableDTCs/E_NOT_OK, DataServices_DID_DE03_Enable_DisableDTCs/DCM_E_PENDING]
        arg Data: type=Dcm_Data64ByteType, direction=IN
        arg OpStatus: type=Dcm_OpStatusType, direction=IN
        arg ErrorCode: type=Dcm_NegativeResponseCodeType, direction=OUT
      error E_NOT_OK: error-code=1
      error DCM_E_PENDING: error-code=10
    DataServices_DID_EE01_XCP_Enable_Disable
      operation ReadData: possible-error=[DataServices_DID_EE01_XCP_Enable_Disable/E_NOT_OK, DataServices_DID_EE01_XCP_Enable_Disable/DCM_E_PENDING]
        arg OpStatus: type=Dcm_OpStatusType, direction=IN
        arg Data: type=Dcm_Data1ByteType, direction=OUT
      operation ConditionCheckRead: possible-error=[DataServices_DID_EE01_XCP_Enable_Disable/E_NOT_OK, DataServices_DID_EE01_XCP_Enable_Disable/DCM_E_PENDING]
        arg OpStatus: type=Dcm_OpStatusType, direction=IN
        arg ErrorCode: type=Dcm_NegativeResponseCodeType, direction=OUT
      operation WriteData: possible-error=[DataServices_DID_EE01_XCP_Enable_Disable/E_NOT_OK, DataServices_DID_EE01_XCP_Enable_Disable/DCM_E_PENDING]
        arg Data: type=Dcm_Data1ByteType, direction=IN
        arg OpStatus: type=Dcm_OpStatusType, direction=IN
        arg ErrorCode: type=Dcm_NegativeResponseCodeType, direction=OUT
      error E_NOT_OK: error-code=1
      error DCM_E_PENDING: error-code=10
    DataServices_DID_F10A_ECU_Cal_Config_Part_Number
      operation ReadData: possible-error=[DataServices_DID_F10A_ECU_Cal_Config_Part_Number/E_NOT_OK, DataServices_DID_F10A_ECU_Cal_Config_Part_Number/DCM_E_PENDING]
        arg OpStatus: type=Dcm_OpStatusType, direction=IN
        arg Data: type=Dcm_Data24ByteType, direction=OUT
      operation ConditionCheckRead: possible-error=[DataServices_DID_F10A_ECU_Cal_Config_Part_Number/E_NOT_OK, DataServices_DID_F10A_ECU_Cal_Config_Part_Number/DCM_E_PENDING]
        arg OpStatus: type=Dcm_OpStatusType, direction=IN
        arg ErrorCode: type=Dcm_NegativeResponseCodeType, direction=OUT
      error E_NOT_OK: error-code=1
      error DCM_E_PENDING: error-code=10
    DataServices_DID_EE02_Assist_On_Off
      operation ReadData: possible-error=[DataServices_DID_EE02_Assist_On_Off/E_NOT_OK, DataServices_DID_EE02_Assist_On_Off/DCM_E_PENDING]
        arg OpStatus: type=Dcm_OpStatusType, direction=IN
        arg Data: type=Dcm_Data1ByteType, direction=OUT
      operation ConditionCheckRead: possible-error=[DataServices_DID_EE02_Assist_On_Off/E_NOT_OK, DataServices_DID_EE02_Assist_On_Off/DCM_E_PENDING]
        arg OpStatus: type=Dcm_OpStatusType, direction=IN
        arg ErrorCode: type=Dcm_NegativeResponseCodeType, direction=OUT
      operation WriteData: possible-error=[DataServices_DID_EE02_Assist_On_Off/E_NOT_OK, DataServices_DID_EE02_Assist_On_Off/DCM_E_PENDING]
        arg Data: type=Dcm_Data1ByteType, direction=IN
        arg OpStatus: type=Dcm_OpStatusType, direction=IN
        arg ErrorCode: type=Dcm_NegativeResponseCodeType, direction=OUT
      error E_NOT_OK: error-code=1
      error DCM_E_PENDING: error-code=10
    DataServices_DID_F188_Vehicle_Manufacturer_ECU_Software_Number
      operation ReadData: possible-error=[DataServices_DID_F188_Vehicle_Manufacturer_ECU_Software_Number/E_NOT_OK, DataServices_DID_F188_Vehicle_Manufacturer_ECU_Software_Number/DCM_E_PENDING]
        arg OpStatus: type=Dcm_OpStatusType, direction=IN
        arg Data: type=Dcm_Data24ByteType, direction=OUT
      operation ConditionCheckRead: possible-error=[DataServices_DID_F188_Vehicle_Manufacturer_ECU_Software_Number/E_NOT_OK, DataServices_DID_F188_Vehicle_Manufacturer_ECU_Software_Number/DCM_E_PENDING]
        arg OpStatus: type=Dcm_OpStatusType, direction=IN
        arg ErrorCode: type=Dcm_NegativeResponseCodeType, direction=OUT
      error E_NOT_OK: error-code=1
      error DCM_E_PENDING: error-code=10
    DataServices_DID_3003_Gear_Hardware_Part_Number
      operation ReadData: possible-error=[DataServices_DID_3003_Gear_Hardware_Part_Number/E_NOT_OK, DataServices_DID_3003_Gear_Hardware_Part_Number/DCM_E_PENDING]
        arg OpStatus: type=Dcm_OpStatusType, direction=IN
        arg Data: type=Dcm_Data24ByteType, direction=OUT
      operation ConditionCheckRead: possible-error=[DataServices_DID_3003_Gear_Hardware_Part_Number/E_NOT_OK, DataServices_DID_3003_Gear_Hardware_Part_Number/DCM_E_PENDING]
        arg OpStatus: type=Dcm_OpStatusType, direction=IN
        arg ErrorCode: type=Dcm_NegativeResponseCodeType, direction=OUT
      operation WriteData: possible-error=[DataServices_DID_3003_Gear_Hardware_Part_Number/E_NOT_OK, DataServices_DID_3003_Gear_Hardware_Part_Number/DCM_E_PENDING]
        arg Data: type=Dcm_Data24ByteType, direction=IN
        arg OpStatus: type=Dcm_OpStatusType, direction=IN
        arg ErrorCode: type=Dcm_NegativeResponseCodeType, direction=OUT
      error E_NOT_OK: error-code=1
      error DCM_E_PENDING: error-code=10
    DataServices_DID_DE04_PDCResetValue
      operation ReadData: possible-error=[DataServices_DID_DE04_PDCResetValue/E_NOT_OK, DataServices_DID_DE04_PDCResetValue/DCM_E_PENDING]
        arg OpStatus: type=Dcm_OpStatusType, direction=IN
        arg Data: type=Dcm_Data2ByteType, direction=OUT
      operation ConditionCheckRead: possible-error=[DataServices_DID_DE04_PDCResetValue/E_NOT_OK, DataServices_DID_DE04_PDCResetValue/DCM_E_PENDING]
        arg OpStatus: type=Dcm_OpStatusType, direction=IN
        arg ErrorCode: type=Dcm_NegativeResponseCodeType, direction=OUT
      operation WriteData: possible-error=[DataServices_DID_DE04_PDCResetValue/E_NOT_OK, DataServices_DID_DE04_PDCResetValue/DCM_E_PENDING]
        arg Data: type=Dcm_Data2ByteType, direction=IN
        arg OpStatus: type=Dcm_OpStatusType, direction=IN
        arg ErrorCode: type=Dcm_NegativeResponseCodeType, direction=OUT
      error E_NOT_OK: error-code=1
      error DCM_E_PENDING: error-code=10
    RoutineServices_RTN_Nexteer_FDA2_Handwheel_Torque_Sensor_2_Auto_Trim
      operation Start: possible-error=[RoutineServices_RTN_Nexteer_FDA2_Handwheel_Torque_Sensor_2_Auto_Trim/E_NOT_OK, RoutineServices_RTN_Nexteer_FDA2_Handwheel_Torque_Sensor_2_Auto_Trim/DCM_E_PENDING, RoutineServices_RTN_Nexteer_FDA2_Handwheel_Torque_Sensor_2_Auto_Trim/DCM_E_FORCE_RCRRP]
        arg OpStatus: type=Dcm_OpStatusType, direction=IN
        arg ErrorCode: type=Dcm_NegativeResponseCodeType, direction=OUT
      error E_NOT_OK: error-code=1
      error DCM_E_PENDING: error-code=10
      error DCM_E_FORCE_RCRRP: error-code=12
    RoutineServices_RTN_Nexteer_FDA3_Handwheel_Torque_Sensor_3_Auto_Trim
      operation Start: possible-error=[RoutineServices_RTN_Nexteer_FDA3_Handwheel_Torque_Sensor_3_Auto_Trim/E_NOT_OK, RoutineServices_RTN_Nexteer_FDA3_Handwheel_Torque_Sensor_3_Auto_Trim/DCM_E_PENDING, RoutineServices_RTN_Nexteer_FDA3_Handwheel_Torque_Sensor_3_Auto_Trim/DCM_E_FORCE_RCRRP]
        arg OpStatus: type=Dcm_OpStatusType, direction=IN
        arg ErrorCode: type=Dcm_NegativeResponseCodeType, direction=OUT
      error E_NOT_OK: error-code=1
      error DCM_E_PENDING: error-code=10
      error DCM_E_FORCE_RCRRP: error-code=12
    RoutineServices_RTN_Nexteer_FDAA_Handwheel_Torque_Sensor_2_Clear_Trim
      operation Start: possible-error=[RoutineServices_RTN_Nexteer_FDAA_Handwheel_Torque_Sensor_2_Clear_Trim/E_NOT_OK, RoutineServices_RTN_Nexteer_FDAA_Handwheel_Torque_Sensor_2_Clear_Trim/DCM_E_PENDING, RoutineServices_RTN_Nexteer_FDAA_Handwheel_Torque_Sensor_2_Clear_Trim/DCM_E_FORCE_RCRRP]
        arg OpStatus: type=Dcm_OpStatusType, direction=IN
        arg ErrorCode: type=Dcm_NegativeResponseCodeType, direction=OUT
      error E_NOT_OK: error-code=1
      error DCM_E_PENDING: error-code=10
      error DCM_E_FORCE_RCRRP: error-code=12
    RoutineServices_RTN_Nexteer_FDAB_Handwheel_Torque_Sensor_3_Clear_Trim
      operation Start: possible-error=[RoutineServices_RTN_Nexteer_FDAB_Handwheel_Torque_Sensor_3_Clear_Trim/E_NOT_OK, RoutineServices_RTN_Nexteer_FDAB_Handwheel_Torque_Sensor_3_Clear_Trim/DCM_E_PENDING, RoutineServices_RTN_Nexteer_FDAB_Handwheel_Torque_Sensor_3_Clear_Trim/DCM_E_FORCE_RCRRP]
        arg OpStatus: type=Dcm_OpStatusType, direction=IN
        arg ErrorCode: type=Dcm_NegativeResponseCodeType, direction=OUT
      error E_NOT_OK: error-code=1
      error DCM_E_PENDING: error-code=10
      error DCM_E_FORCE_RCRRP: error-code=12
    DataServices_DID_D100_Active_Diagnostic_Session
      operation ReadData: possible-error=[DataServices_DID_D100_Active_Diagnostic_Session/E_NOT_OK, DataServices_DID_D100_Active_Diagnostic_Session/DCM_E_PENDING]
        arg OpStatus: type=Dcm_OpStatusType, direction=IN
        arg Data: type=Dcm_Data1ByteType, direction=OUT
      operation ConditionCheckRead: possible-error=[DataServices_DID_D100_Active_Diagnostic_Session/E_NOT_OK, DataServices_DID_D100_Active_Diagnostic_Session/DCM_E_PENDING]
        arg OpStatus: type=Dcm_OpStatusType, direction=IN
        arg ErrorCode: type=Dcm_NegativeResponseCodeType, direction=OUT
      error E_NOT_OK: error-code=1
      error DCM_E_PENDING: error-code=10
    DataServices_DID_EE40_ResearchMessConfig
      operation ReadData: possible-error=[DataServices_DID_EE40_ResearchMessConfig/E_NOT_OK, DataServices_DID_EE40_ResearchMessConfig/DCM_E_PENDING]
        arg OpStatus: type=Dcm_OpStatusType, direction=IN
        arg Data: type=Dcm_Data3ByteType, direction=OUT
      operation ConditionCheckRead: possible-error=[DataServices_DID_EE40_ResearchMessConfig/E_NOT_OK, DataServices_DID_EE40_ResearchMessConfig/DCM_E_PENDING]
        arg OpStatus: type=Dcm_OpStatusType, direction=IN
        arg ErrorCode: type=Dcm_NegativeResponseCodeType, direction=OUT
      operation WriteData: possible-error=[DataServices_DID_EE40_ResearchMessConfig/E_NOT_OK, DataServices_DID_EE40_ResearchMessConfig/DCM_E_PENDING]
        arg Data: type=Dcm_Data3ByteType, direction=IN
        arg OpStatus: type=Dcm_OpStatusType, direction=IN
        arg ErrorCode: type=Dcm_NegativeResponseCodeType, direction=OUT
      error E_NOT_OK: error-code=1
      error DCM_E_PENDING: error-code=10
    DataServices_DID_F163_Diagnostic_Specification_Version
      operation ReadData: possible-error=[DataServices_DID_F163_Diagnostic_Specification_Version/E_NOT_OK, DataServices_DID_F163_Diagnostic_Specification_Version/DCM_E_PENDING]
        arg OpStatus: type=Dcm_OpStatusType, direction=IN
        arg Data: type=Dcm_Data1ByteType, direction=OUT
      operation ConditionCheckRead: possible-error=[DataServices_DID_F163_Diagnostic_Specification_Version/E_NOT_OK, DataServices_DID_F163_Diagnostic_Specification_Version/DCM_E_PENDING]
        arg OpStatus: type=Dcm_OpStatusType, direction=IN
        arg ErrorCode: type=Dcm_NegativeResponseCodeType, direction=OUT
      operation WriteData: possible-error=[DataServices_DID_F163_Diagnostic_Specification_Version/E_NOT_OK, DataServices_DID_F163_Diagnostic_Specification_Version/DCM_E_PENDING]
        arg Data: type=Dcm_Data1ByteType, direction=IN
        arg OpStatus: type=Dcm_OpStatusType, direction=IN
        arg ErrorCode: type=Dcm_NegativeResponseCodeType, direction=OUT
      error E_NOT_OK: error-code=1
      error DCM_E_PENDING: error-code=10
    DataServices_DID_EED1_SupplierInternalFaultCode
      operation ReadData: possible-error=[DataServices_DID_EED1_SupplierInternalFaultCode/E_NOT_OK, DataServices_DID_EED1_SupplierInternalFaultCode/DCM_E_PENDING]
        arg OpStatus: type=Dcm_OpStatusType, direction=IN
        arg Data: type=Dcm_Data7ByteType, direction=OUT
      operation ConditionCheckRead: possible-error=[DataServices_DID_EED1_SupplierInternalFaultCode/E_NOT_OK, DataServices_DID_EED1_SupplierInternalFaultCode/DCM_E_PENDING]
        arg OpStatus: type=Dcm_OpStatusType, direction=IN
        arg ErrorCode: type=Dcm_NegativeResponseCodeType, direction=OUT
      error E_NOT_OK: error-code=1
      error DCM_E_PENDING: error-code=10
    DataServices_DID_EE86_FIHSwReserved5
      operation ReadData: possible-error=[DataServices_DID_EE86_FIHSwReserved5/E_NOT_OK, DataServices_DID_EE86_FIHSwReserved5/DCM_E_PENDING]
        arg OpStatus: type=Dcm_OpStatusType, direction=IN
        arg Data: type=Dcm_Data4ByteType, direction=OUT
      operation ConditionCheckRead: possible-error=[DataServices_DID_EE86_FIHSwReserved5/E_NOT_OK, DataServices_DID_EE86_FIHSwReserved5/DCM_E_PENDING]
        arg OpStatus: type=Dcm_OpStatusType, direction=IN
        arg ErrorCode: type=Dcm_NegativeResponseCodeType, direction=OUT
      operation WriteData: possible-error=[DataServices_DID_EE86_FIHSwReserved5/E_NOT_OK, DataServices_DID_EE86_FIHSwReserved5/DCM_E_PENDING]
        arg Data: type=Dcm_Data4ByteType, direction=IN
        arg OpStatus: type=Dcm_OpStatusType, direction=IN
        arg ErrorCode: type=Dcm_NegativeResponseCodeType, direction=OUT
      error E_NOT_OK: error-code=1
      error DCM_E_PENDING: error-code=10
    DataServices_DID_F166_NOS_Message_Database_1_Version_Number
      operation ReadData: possible-error=[DataServices_DID_F166_NOS_Message_Database_1_Version_Number/E_NOT_OK, DataServices_DID_F166_NOS_Message_Database_1_Version_Number/DCM_E_PENDING]
        arg OpStatus: type=Dcm_OpStatusType, direction=IN
        arg Data: type=Dcm_Data4ByteType, direction=OUT
      operation ConditionCheckRead: possible-error=[DataServices_DID_F166_NOS_Message_Database_1_Version_Number/E_NOT_OK, DataServices_DID_F166_NOS_Message_Database_1_Version_Number/DCM_E_PENDING]
        arg OpStatus: type=Dcm_OpStatusType, direction=IN
        arg ErrorCode: type=Dcm_NegativeResponseCodeType, direction=OUT
      operation WriteData: possible-error=[DataServices_DID_F166_NOS_Message_Database_1_Version_Number/E_NOT_OK, DataServices_DID_F166_NOS_Message_Database_1_Version_Number/DCM_E_PENDING]
        arg Data: type=Dcm_Data4ByteType, direction=IN
        arg OpStatus: type=Dcm_OpStatusType, direction=IN
        arg ErrorCode: type=Dcm_NegativeResponseCodeType, direction=OUT
      error E_NOT_OK: error-code=1
      error DCM_E_PENDING: error-code=10
    DataServices_DID_3B4B_Steering_wheel_angle_alignment_offset
      operation ReadData: possible-error=[DataServices_DID_3B4B_Steering_wheel_angle_alignment_offset/E_NOT_OK, DataServices_DID_3B4B_Steering_wheel_angle_alignment_offset/DCM_E_PENDING]
        arg OpStatus: type=Dcm_OpStatusType, direction=IN
        arg Data: type=Dcm_Data2ByteType, direction=OUT
      operation ConditionCheckRead: possible-error=[DataServices_DID_3B4B_Steering_wheel_angle_alignment_offset/E_NOT_OK, DataServices_DID_3B4B_Steering_wheel_angle_alignment_offset/DCM_E_PENDING]
        arg OpStatus: type=Dcm_OpStatusType, direction=IN
        arg ErrorCode: type=Dcm_NegativeResponseCodeType, direction=OUT
      error E_NOT_OK: error-code=1
      error DCM_E_PENDING: error-code=10
    DataServices_DID_EE05_FinalMotTq
      operation ReadData: possible-error=[DataServices_DID_EE05_FinalMotTq/E_NOT_OK, DataServices_DID_EE05_FinalMotTq/DCM_E_PENDING]
        arg OpStatus: type=Dcm_OpStatusType, direction=IN
        arg Data: type=Dcm_Data2ByteType, direction=OUT
      operation ConditionCheckRead: possible-error=[DataServices_DID_EE05_FinalMotTq/E_NOT_OK, DataServices_DID_EE05_FinalMotTq/DCM_E_PENDING]
        arg OpStatus: type=Dcm_OpStatusType, direction=IN
        arg ErrorCode: type=Dcm_NegativeResponseCodeType, direction=OUT
      error E_NOT_OK: error-code=1
      error DCM_E_PENDING: error-code=10
    DataServices_DID_D111_ECU_Power_Supply_Voltage
      operation ReadData: possible-error=[DataServices_DID_D111_ECU_Power_Supply_Voltage/E_NOT_OK, DataServices_DID_D111_ECU_Power_Supply_Voltage/DCM_E_PENDING]
        arg OpStatus: type=Dcm_OpStatusType, direction=IN
        arg Data: type=Dcm_Data1ByteType, direction=OUT
      operation ConditionCheckRead: possible-error=[DataServices_DID_D111_ECU_Power_Supply_Voltage/E_NOT_OK, DataServices_DID_D111_ECU_Power_Supply_Voltage/DCM_E_PENDING]
        arg OpStatus: type=Dcm_OpStatusType, direction=IN
        arg ErrorCode: type=Dcm_NegativeResponseCodeType, direction=OUT
      error E_NOT_OK: error-code=1
      error DCM_E_PENDING: error-code=10
    DataServices_DID_DD01_Total_Distance
      operation ReadData: possible-error=[DataServices_DID_DD01_Total_Distance/E_NOT_OK, DataServices_DID_DD01_Total_Distance/DCM_E_PENDING]
        arg OpStatus: type=Dcm_OpStatusType, direction=IN
        arg Data: type=Dcm_Data3ByteType, direction=OUT
      operation ConditionCheckRead: possible-error=[DataServices_DID_DD01_Total_Distance/E_NOT_OK, DataServices_DID_DD01_Total_Distance/DCM_E_PENDING]
        arg OpStatus: type=Dcm_OpStatusType, direction=IN
        arg ErrorCode: type=Dcm_NegativeResponseCodeType, direction=OUT
      error E_NOT_OK: error-code=1
      error DCM_E_PENDING: error-code=10
    DataServices_DID_330C_Steering_Shaft_Torque_Sensor_2
      operation ReadData: possible-error=[DataServices_DID_330C_Steering_Shaft_Torque_Sensor_2/E_NOT_OK, DataServices_DID_330C_Steering_Shaft_Torque_Sensor_2/DCM_E_PENDING]
        arg OpStatus: type=Dcm_OpStatusType, direction=IN
        arg Data: type=Dcm_Data1ByteType, direction=OUT
      operation ConditionCheckRead: possible-error=[DataServices_DID_330C_Steering_Shaft_Torque_Sensor_2/E_NOT_OK, DataServices_DID_330C_Steering_Shaft_Torque_Sensor_2/DCM_E_PENDING]
        arg OpStatus: type=Dcm_OpStatusType, direction=IN
        arg ErrorCode: type=Dcm_NegativeResponseCodeType, direction=OUT
      error E_NOT_OK: error-code=1
      error DCM_E_PENDING: error-code=10
    DataServices_DID_205B_Brake_Pull_Reduction_Activation_Counter
      operation ReadData: possible-error=[DataServices_DID_205B_Brake_Pull_Reduction_Activation_Counter/E_NOT_OK, DataServices_DID_205B_Brake_Pull_Reduction_Activation_Counter/DCM_E_PENDING]
        arg OpStatus: type=Dcm_OpStatusType, direction=IN
        arg Data: type=Dcm_Data2ByteType, direction=OUT
      operation ConditionCheckRead: possible-error=[DataServices_DID_205B_Brake_Pull_Reduction_Activation_Counter/E_NOT_OK, DataServices_DID_205B_Brake_Pull_Reduction_Activation_Counter/DCM_E_PENDING]
        arg OpStatus: type=Dcm_OpStatusType, direction=IN
        arg ErrorCode: type=Dcm_NegativeResponseCodeType, direction=OUT
      operation WriteData: possible-error=[DataServices_DID_205B_Brake_Pull_Reduction_Activation_Counter/E_NOT_OK, DataServices_DID_205B_Brake_Pull_Reduction_Activation_Counter/DCM_E_PENDING]
        arg Data: type=Dcm_Data2ByteType, direction=IN
        arg OpStatus: type=Dcm_OpStatusType, direction=IN
        arg ErrorCode: type=Dcm_NegativeResponseCodeType, direction=OUT
      error E_NOT_OK: error-code=1
      error DCM_E_PENDING: error-code=10
    DataServices_DID_EE80_FIHSwVer
      operation ReadData: possible-error=[DataServices_DID_EE80_FIHSwVer/E_NOT_OK, DataServices_DID_EE80_FIHSwVer/DCM_E_PENDING]
        arg OpStatus: type=Dcm_OpStatusType, direction=IN
        arg Data: type=Dcm_Data1ByteType, direction=OUT
      operation ConditionCheckRead: possible-error=[DataServices_DID_EE80_FIHSwVer/E_NOT_OK, DataServices_DID_EE80_FIHSwVer/DCM_E_PENDING]
        arg OpStatus: type=Dcm_OpStatusType, direction=IN
        arg ErrorCode: type=Dcm_NegativeResponseCodeType, direction=OUT
      error E_NOT_OK: error-code=1
      error DCM_E_PENDING: error-code=10
    DataServices_DID_F162_Software_Download_Specification_Version
      operation ReadData: possible-error=[DataServices_DID_F162_Software_Download_Specification_Version/E_NOT_OK, DataServices_DID_F162_Software_Download_Specification_Version/DCM_E_PENDING]
        arg OpStatus: type=Dcm_OpStatusType, direction=IN
        arg Data: type=Dcm_Data1ByteType, direction=OUT
      operation ConditionCheckRead: possible-error=[DataServices_DID_F162_Software_Download_Specification_Version/E_NOT_OK, DataServices_DID_F162_Software_Download_Specification_Version/DCM_E_PENDING]
        arg OpStatus: type=Dcm_OpStatusType, direction=IN
        arg ErrorCode: type=Dcm_NegativeResponseCodeType, direction=OUT
      operation WriteData: possible-error=[DataServices_DID_F162_Software_Download_Specification_Version/E_NOT_OK, DataServices_DID_F162_Software_Download_Specification_Version/DCM_E_PENDING]
        arg Data: type=Dcm_Data1ByteType, direction=IN
        arg OpStatus: type=Dcm_OpStatusType, direction=IN
        arg ErrorCode: type=Dcm_NegativeResponseCodeType, direction=OUT
      error E_NOT_OK: error-code=1
      error DCM_E_PENDING: error-code=10
    DataServices_DID_F180_Boot_Software_Identification
      operation ReadData: possible-error=[DataServices_DID_F180_Boot_Software_Identification/E_NOT_OK, DataServices_DID_F180_Boot_Software_Identification/DCM_E_PENDING]
        arg OpStatus: type=Dcm_OpStatusType, direction=IN
        arg Data: type=Dcm_Data25ByteType, direction=OUT
      operation ConditionCheckRead: possible-error=[DataServices_DID_F180_Boot_Software_Identification/E_NOT_OK, DataServices_DID_F180_Boot_Software_Identification/DCM_E_PENDING]
        arg OpStatus: type=Dcm_OpStatusType, direction=IN
        arg ErrorCode: type=Dcm_NegativeResponseCodeType, direction=OUT
      error E_NOT_OK: error-code=1
      error DCM_E_PENDING: error-code=10
    DataServices_DID_D117_ECU_Internal_Temperature
      operation ReadData: possible-error=[DataServices_DID_D117_ECU_Internal_Temperature/E_NOT_OK, DataServices_DID_D117_ECU_Internal_Temperature/DCM_E_PENDING]
        arg OpStatus: type=Dcm_OpStatusType, direction=IN
        arg Data: type=Dcm_Data1ByteType, direction=OUT
      operation ConditionCheckRead: possible-error=[DataServices_DID_D117_ECU_Internal_Temperature/E_NOT_OK, DataServices_DID_D117_ECU_Internal_Temperature/DCM_E_PENDING]
        arg OpStatus: type=Dcm_OpStatusType, direction=IN
        arg ErrorCode: type=Dcm_NegativeResponseCodeType, direction=OUT
      error E_NOT_OK: error-code=1
      error DCM_E_PENDING: error-code=10
    DataServices_DID_205A_Torque_Steer_Compensation_Activation_Counter
      operation ReadData: possible-error=[DataServices_DID_205A_Torque_Steer_Compensation_Activation_Counter/E_NOT_OK, DataServices_DID_205A_Torque_Steer_Compensation_Activation_Counter/DCM_E_PENDING]
        arg OpStatus: type=Dcm_OpStatusType, direction=IN
        arg Data: type=Dcm_Data2ByteType, direction=OUT
      operation ConditionCheckRead: possible-error=[DataServices_DID_205A_Torque_Steer_Compensation_Activation_Counter/E_NOT_OK, DataServices_DID_205A_Torque_Steer_Compensation_Activation_Counter/DCM_E_PENDING]
        arg OpStatus: type=Dcm_OpStatusType, direction=IN
        arg ErrorCode: type=Dcm_NegativeResponseCodeType, direction=OUT
      operation WriteData: possible-error=[DataServices_DID_205A_Torque_Steer_Compensation_Activation_Counter/E_NOT_OK, DataServices_DID_205A_Torque_Steer_Compensation_Activation_Counter/DCM_E_PENDING]
        arg Data: type=Dcm_Data2ByteType, direction=IN
        arg OpStatus: type=Dcm_OpStatusType, direction=IN
        arg ErrorCode: type=Dcm_NegativeResponseCodeType, direction=OUT
      error E_NOT_OK: error-code=1
      error DCM_E_PENDING: error-code=10
    DataServices_DID_EE87_FIHSwReserved6
      operation ReadData: possible-error=[DataServices_DID_EE87_FIHSwReserved6/E_NOT_OK, DataServices_DID_EE87_FIHSwReserved6/DCM_E_PENDING]
        arg OpStatus: type=Dcm_OpStatusType, direction=IN
        arg Data: type=Dcm_Data4ByteType, direction=OUT
      operation ConditionCheckRead: possible-error=[DataServices_DID_EE87_FIHSwReserved6/E_NOT_OK, DataServices_DID_EE87_FIHSwReserved6/DCM_E_PENDING]
        arg OpStatus: type=Dcm_OpStatusType, direction=IN
        arg ErrorCode: type=Dcm_NegativeResponseCodeType, direction=OUT
      operation WriteData: possible-error=[DataServices_DID_EE87_FIHSwReserved6/E_NOT_OK, DataServices_DID_EE87_FIHSwReserved6/DCM_E_PENDING]
        arg Data: type=Dcm_Data4ByteType, direction=IN
        arg OpStatus: type=Dcm_OpStatusType, direction=IN
        arg ErrorCode: type=Dcm_NegativeResponseCodeType, direction=OUT
      error E_NOT_OK: error-code=1
      error DCM_E_PENDING: error-code=10
    DataServices_DID_630F_Multiple_VIN_Storage_Original_VIN
      operation ReadData: possible-error=[DataServices_DID_630F_Multiple_VIN_Storage_Original_VIN/E_NOT_OK, DataServices_DID_630F_Multiple_VIN_Storage_Original_VIN/DCM_E_PENDING]
        arg OpStatus: type=Dcm_OpStatusType, direction=IN
        arg Data: type=Dcm_Data24ByteType, direction=OUT
      operation ConditionCheckRead: possible-error=[DataServices_DID_630F_Multiple_VIN_Storage_Original_VIN/E_NOT_OK, DataServices_DID_630F_Multiple_VIN_Storage_Original_VIN/DCM_E_PENDING]
        arg OpStatus: type=Dcm_OpStatusType, direction=IN
        arg ErrorCode: type=Dcm_NegativeResponseCodeType, direction=OUT
      error E_NOT_OK: error-code=1
      error DCM_E_PENDING: error-code=10
    DataServices_DID_F110_Subsystem_Specific_Diagnostic_Specification_Part_Number
      operation ReadData: possible-error=[DataServices_DID_F110_Subsystem_Specific_Diagnostic_Specification_Part_Number/E_NOT_OK, DataServices_DID_F110_Subsystem_Specific_Diagnostic_Specification_Part_Number/DCM_E_PENDING]
        arg OpStatus: type=Dcm_OpStatusType, direction=IN
        arg Data: type=Dcm_Data24ByteType, direction=OUT
      operation ConditionCheckRead: possible-error=[DataServices_DID_F110_Subsystem_Specific_Diagnostic_Specification_Part_Number/E_NOT_OK, DataServices_DID_F110_Subsystem_Specific_Diagnostic_Specification_Part_Number/DCM_E_PENDING]
        arg OpStatus: type=Dcm_OpStatusType, direction=IN
        arg ErrorCode: type=Dcm_NegativeResponseCodeType, direction=OUT
      operation WriteData: possible-error=[DataServices_DID_F110_Subsystem_Specific_Diagnostic_Specification_Part_Number/E_NOT_OK, DataServices_DID_F110_Subsystem_Specific_Diagnostic_Specification_Part_Number/DCM_E_PENDING]
        arg Data: type=Dcm_Data24ByteType, direction=IN
        arg OpStatus: type=Dcm_OpStatusType, direction=IN
        arg ErrorCode: type=Dcm_NegativeResponseCodeType, direction=OUT
      error E_NOT_OK: error-code=1
      error DCM_E_PENDING: error-code=10
    DataServices_DID_EE42_ActiveFeatures
      operation ReadData: possible-error=[DataServices_DID_EE42_ActiveFeatures/E_NOT_OK, DataServices_DID_EE42_ActiveFeatures/DCM_E_PENDING]
        arg OpStatus: type=Dcm_OpStatusType, direction=IN
        arg Data: type=Dcm_Data1ByteType, direction=OUT
      operation ConditionCheckRead: possible-error=[DataServices_DID_EE42_ActiveFeatures/E_NOT_OK, DataServices_DID_EE42_ActiveFeatures/DCM_E_PENDING]
        arg OpStatus: type=Dcm_OpStatusType, direction=IN
        arg ErrorCode: type=Dcm_NegativeResponseCodeType, direction=OUT
      error E_NOT_OK: error-code=1
      error DCM_E_PENDING: error-code=10
    DataServices_DID_EE22_VoltageLvlCounters
      operation ReadData: possible-error=[DataServices_DID_EE22_VoltageLvlCounters/E_NOT_OK, DataServices_DID_EE22_VoltageLvlCounters/DCM_E_PENDING]
        arg OpStatus: type=Dcm_OpStatusType, direction=IN
        arg Data: type=Dcm_Data40ByteType, direction=OUT
      operation ConditionCheckRead: possible-error=[DataServices_DID_EE22_VoltageLvlCounters/E_NOT_OK, DataServices_DID_EE22_VoltageLvlCounters/DCM_E_PENDING]
        arg OpStatus: type=Dcm_OpStatusType, direction=IN
        arg ErrorCode: type=Dcm_NegativeResponseCodeType, direction=OUT
      error E_NOT_OK: error-code=1
      error DCM_E_PENDING: error-code=10
    DataServices_DID_EE03_IgnCycleCounter
      operation ReadData: possible-error=[DataServices_DID_EE03_IgnCycleCounter/E_NOT_OK, DataServices_DID_EE03_IgnCycleCounter/DCM_E_PENDING]
        arg OpStatus: type=Dcm_OpStatusType, direction=IN
        arg Data: type=Dcm_Data2ByteType, direction=OUT
      operation ConditionCheckRead: possible-error=[DataServices_DID_EE03_IgnCycleCounter/E_NOT_OK, DataServices_DID_EE03_IgnCycleCounter/DCM_E_PENDING]
        arg OpStatus: type=Dcm_OpStatusType, direction=IN
        arg ErrorCode: type=Dcm_NegativeResponseCodeType, direction=OUT
      error E_NOT_OK: error-code=1
      error DCM_E_PENDING: error-code=10
    DataServices_DID_301A_Pull_Drift_Compensation_Value
      operation ReadData: possible-error=[DataServices_DID_301A_Pull_Drift_Compensation_Value/E_NOT_OK, DataServices_DID_301A_Pull_Drift_Compensation_Value/DCM_E_PENDING]
        arg OpStatus: type=Dcm_OpStatusType, direction=IN
        arg Data: type=Dcm_Data2ByteType, direction=OUT
      operation ConditionCheckRead: possible-error=[DataServices_DID_301A_Pull_Drift_Compensation_Value/E_NOT_OK, DataServices_DID_301A_Pull_Drift_Compensation_Value/DCM_E_PENDING]
        arg OpStatus: type=Dcm_OpStatusType, direction=IN
        arg ErrorCode: type=Dcm_NegativeResponseCodeType, direction=OUT
      operation WriteData: possible-error=[DataServices_DID_301A_Pull_Drift_Compensation_Value/E_NOT_OK, DataServices_DID_301A_Pull_Drift_Compensation_Value/DCM_E_PENDING]
        arg Data: type=Dcm_Data2ByteType, direction=IN
        arg OpStatus: type=Dcm_OpStatusType, direction=IN
        arg ErrorCode: type=Dcm_NegativeResponseCodeType, direction=OUT
      error E_NOT_OK: error-code=1
      error DCM_E_PENDING: error-code=10
    DataServices_DID_EE83_FIHSwReserved2
      operation ReadData: possible-error=[DataServices_DID_EE83_FIHSwReserved2/E_NOT_OK, DataServices_DID_EE83_FIHSwReserved2/DCM_E_PENDING]
        arg OpStatus: type=Dcm_OpStatusType, direction=IN
        arg Data: type=Dcm_Data4ByteType, direction=OUT
      operation ConditionCheckRead: possible-error=[DataServices_DID_EE83_FIHSwReserved2/E_NOT_OK, DataServices_DID_EE83_FIHSwReserved2/DCM_E_PENDING]
        arg OpStatus: type=Dcm_OpStatusType, direction=IN
        arg ErrorCode: type=Dcm_NegativeResponseCodeType, direction=OUT
      operation WriteData: possible-error=[DataServices_DID_EE83_FIHSwReserved2/E_NOT_OK, DataServices_DID_EE83_FIHSwReserved2/DCM_E_PENDING]
        arg Data: type=Dcm_Data4ByteType, direction=IN
        arg OpStatus: type=Dcm_OpStatusType, direction=IN
        arg ErrorCode: type=Dcm_NegativeResponseCodeType, direction=OUT
      error E_NOT_OK: error-code=1
      error DCM_E_PENDING: error-code=10
    DataServices_DID_F190_Vehicle_Identification_Number
      operation ReadData: possible-error=[DataServices_DID_F190_Vehicle_Identification_Number/E_NOT_OK, DataServices_DID_F190_Vehicle_Identification_Number/DCM_E_PENDING]
        arg OpStatus: type=Dcm_OpStatusType, direction=IN
        arg Data: type=Dcm_Data24ByteType, direction=OUT
      operation ConditionCheckRead: possible-error=[DataServices_DID_F190_Vehicle_Identification_Number/E_NOT_OK, DataServices_DID_F190_Vehicle_Identification_Number/DCM_E_PENDING]
        arg OpStatus: type=Dcm_OpStatusType, direction=IN
        arg ErrorCode: type=Dcm_NegativeResponseCodeType, direction=OUT
      error E_NOT_OK: error-code=1
      error DCM_E_PENDING: error-code=10
    DataServices_DID_EE00_DevMessConfig
      operation ReadData: possible-error=[DataServices_DID_EE00_DevMessConfig/E_NOT_OK, DataServices_DID_EE00_DevMessConfig/DCM_E_PENDING]
        arg OpStatus: type=Dcm_OpStatusType, direction=IN
        arg Data: type=Dcm_Data3ByteType, direction=OUT
      operation ConditionCheckRead: possible-error=[DataServices_DID_EE00_DevMessConfig/E_NOT_OK, DataServices_DID_EE00_DevMessConfig/DCM_E_PENDING]
        arg OpStatus: type=Dcm_OpStatusType, direction=IN
        arg ErrorCode: type=Dcm_NegativeResponseCodeType, direction=OUT
      operation WriteData: possible-error=[DataServices_DID_EE00_DevMessConfig/E_NOT_OK, DataServices_DID_EE00_DevMessConfig/DCM_E_PENDING]
        arg Data: type=Dcm_Data3ByteType, direction=IN
        arg OpStatus: type=Dcm_OpStatusType, direction=IN
        arg ErrorCode: type=Dcm_NegativeResponseCodeType, direction=OUT
      error E_NOT_OK: error-code=1
      error DCM_E_PENDING: error-code=10
    DataServices_DID_3020_Steering_Pinion_Angle
      operation ReadData: possible-error=[DataServices_DID_3020_Steering_Pinion_Angle/E_NOT_OK, DataServices_DID_3020_Steering_Pinion_Angle/DCM_E_PENDING]
        arg OpStatus: type=Dcm_OpStatusType, direction=IN
        arg Data: type=Dcm_Data2ByteType, direction=OUT
      operation ConditionCheckRead: possible-error=[DataServices_DID_3020_Steering_Pinion_Angle/E_NOT_OK, DataServices_DID_3020_Steering_Pinion_Angle/DCM_E_PENDING]
        arg OpStatus: type=Dcm_OpStatusType, direction=IN
        arg ErrorCode: type=Dcm_NegativeResponseCodeType, direction=OUT
      error E_NOT_OK: error-code=1
      error DCM_E_PENDING: error-code=10
    DataServices_DID_EE07_EPSSystemState
      operation ReadData: possible-error=[DataServices_DID_EE07_EPSSystemState/E_NOT_OK, DataServices_DID_EE07_EPSSystemState/DCM_E_PENDING]
        arg OpStatus: type=Dcm_OpStatusType, direction=IN
        arg Data: type=Dcm_Data1ByteType, direction=OUT
      operation ConditionCheckRead: possible-error=[DataServices_DID_EE07_EPSSystemState/E_NOT_OK, DataServices_DID_EE07_EPSSystemState/DCM_E_PENDING]
        arg OpStatus: type=Dcm_OpStatusType, direction=IN
        arg ErrorCode: type=Dcm_NegativeResponseCodeType, direction=OUT
      error E_NOT_OK: error-code=1
      error DCM_E_PENDING: error-code=10
    DataServices_DID_EE23_TempLvlCounters
      operation ReadData: possible-error=[DataServices_DID_EE23_TempLvlCounters/E_NOT_OK, DataServices_DID_EE23_TempLvlCounters/DCM_E_PENDING]
        arg OpStatus: type=Dcm_OpStatusType, direction=IN
        arg Data: type=Dcm_Data40ByteType, direction=OUT
      operation ConditionCheckRead: possible-error=[DataServices_DID_EE23_TempLvlCounters/E_NOT_OK, DataServices_DID_EE23_TempLvlCounters/DCM_E_PENDING]
        arg OpStatus: type=Dcm_OpStatusType, direction=IN
        arg ErrorCode: type=Dcm_NegativeResponseCodeType, direction=OUT
      error E_NOT_OK: error-code=1
      error DCM_E_PENDING: error-code=10
    DataServices_DID_DD09_Vehicle_Speed
      operation ReadData: possible-error=[DataServices_DID_DD09_Vehicle_Speed/E_NOT_OK, DataServices_DID_DD09_Vehicle_Speed/DCM_E_PENDING]
        arg OpStatus: type=Dcm_OpStatusType, direction=IN
        arg Data: type=Dcm_Data1ByteType, direction=OUT
      operation ConditionCheckRead: possible-error=[DataServices_DID_DD09_Vehicle_Speed/E_NOT_OK, DataServices_DID_DD09_Vehicle_Speed/DCM_E_PENDING]
        arg OpStatus: type=Dcm_OpStatusType, direction=IN
        arg ErrorCode: type=Dcm_NegativeResponseCodeType, direction=OUT
      error E_NOT_OK: error-code=1
      error DCM_E_PENDING: error-code=10
    DataServices_DID_EE21_CurrentLvlCounter
      operation ReadData: possible-error=[DataServices_DID_EE21_CurrentLvlCounter/E_NOT_OK, DataServices_DID_EE21_CurrentLvlCounter/DCM_E_PENDING]
        arg OpStatus: type=Dcm_OpStatusType, direction=IN
        arg Data: type=Dcm_Data20ByteType, direction=OUT
      operation ConditionCheckRead: possible-error=[DataServices_DID_EE21_CurrentLvlCounter/E_NOT_OK, DataServices_DID_EE21_CurrentLvlCounter/DCM_E_PENDING]
        arg OpStatus: type=Dcm_OpStatusType, direction=IN
        arg ErrorCode: type=Dcm_NegativeResponseCodeType, direction=OUT
      error E_NOT_OK: error-code=1
      error DCM_E_PENDING: error-code=10
    DataServices_DID_301F_Steering_Pinion_Rotation_Speed
      operation ReadData: possible-error=[DataServices_DID_301F_Steering_Pinion_Rotation_Speed/E_NOT_OK, DataServices_DID_301F_Steering_Pinion_Rotation_Speed/DCM_E_PENDING]
        arg OpStatus: type=Dcm_OpStatusType, direction=IN
        arg Data: type=Dcm_Data1ByteType, direction=OUT
      operation ConditionCheckRead: possible-error=[DataServices_DID_301F_Steering_Pinion_Rotation_Speed/E_NOT_OK, DataServices_DID_301F_Steering_Pinion_Rotation_Speed/DCM_E_PENDING]
        arg OpStatus: type=Dcm_OpStatusType, direction=IN
        arg ErrorCode: type=Dcm_NegativeResponseCodeType, direction=OUT
      error E_NOT_OK: error-code=1
      error DCM_E_PENDING: error-code=10
    DataServices_DID_F18A_System_Supplier_Identifier
      operation ReadData: possible-error=[DataServices_DID_F18A_System_Supplier_Identifier/E_NOT_OK, DataServices_DID_F18A_System_Supplier_Identifier/DCM_E_PENDING]
        arg OpStatus: type=Dcm_OpStatusType, direction=IN
        arg Data: type=Dcm_Data24ByteType, direction=OUT
      operation ConditionCheckRead: possible-error=[DataServices_DID_F18A_System_Supplier_Identifier/E_NOT_OK, DataServices_DID_F18A_System_Supplier_Identifier/DCM_E_PENDING]
        arg OpStatus: type=Dcm_OpStatusType, direction=IN
        arg ErrorCode: type=Dcm_NegativeResponseCodeType, direction=OUT
      operation WriteData: possible-error=[DataServices_DID_F18A_System_Supplier_Identifier/E_NOT_OK, DataServices_DID_F18A_System_Supplier_Identifier/DCM_E_PENDING]
        arg Data: type=Dcm_Data24ByteType, direction=IN
        arg OpStatus: type=Dcm_OpStatusType, direction=IN
        arg ErrorCode: type=Dcm_NegativeResponseCodeType, direction=OUT
      error E_NOT_OK: error-code=1
      error DCM_E_PENDING: error-code=10
    DataServices_DID_F18C_ECU_Serial_Number
      operation ReadData: possible-error=[DataServices_DID_F18C_ECU_Serial_Number/E_NOT_OK, DataServices_DID_F18C_ECU_Serial_Number/DCM_E_PENDING]
        arg OpStatus: type=Dcm_OpStatusType, direction=IN
        arg Data: type=Dcm_Data16ByteType, direction=OUT
      operation ConditionCheckRead: possible-error=[DataServices_DID_F18C_ECU_Serial_Number/E_NOT_OK, DataServices_DID_F18C_ECU_Serial_Number/DCM_E_PENDING]
        arg OpStatus: type=Dcm_OpStatusType, direction=IN
        arg ErrorCode: type=Dcm_NegativeResponseCodeType, direction=OUT
      operation WriteData: possible-error=[DataServices_DID_F18C_ECU_Serial_Number/E_NOT_OK, DataServices_DID_F18C_ECU_Serial_Number/DCM_E_PENDING]
        arg Data: type=Dcm_Data16ByteType, direction=IN
        arg OpStatus: type=Dcm_OpStatusType, direction=IN
        arg ErrorCode: type=Dcm_NegativeResponseCodeType, direction=OUT
      error E_NOT_OK: error-code=1
      error DCM_E_PENDING: error-code=10
    DataServices_DID_EE82_FIHSwReserved1
      operation ReadData: possible-error=[DataServices_DID_EE82_FIHSwReserved1/E_NOT_OK, DataServices_DID_EE82_FIHSwReserved1/DCM_E_PENDING]
        arg OpStatus: type=Dcm_OpStatusType, direction=IN
        arg Data: type=Dcm_Data4ByteType, direction=OUT
      operation ConditionCheckRead: possible-error=[DataServices_DID_EE82_FIHSwReserved1/E_NOT_OK, DataServices_DID_EE82_FIHSwReserved1/DCM_E_PENDING]
        arg OpStatus: type=Dcm_OpStatusType, direction=IN
        arg ErrorCode: type=Dcm_NegativeResponseCodeType, direction=OUT
      operation WriteData: possible-error=[DataServices_DID_EE82_FIHSwReserved1/E_NOT_OK, DataServices_DID_EE82_FIHSwReserved1/DCM_E_PENDING]
        arg Data: type=Dcm_Data4ByteType, direction=IN
        arg OpStatus: type=Dcm_OpStatusType, direction=IN
        arg ErrorCode: type=Dcm_NegativeResponseCodeType, direction=OUT
      error E_NOT_OK: error-code=1
      error DCM_E_PENDING: error-code=10
    DataServices_DID_EE84_FIHSwReserved3
      operation ReadData: possible-error=[DataServices_DID_EE84_FIHSwReserved3/E_NOT_OK, DataServices_DID_EE84_FIHSwReserved3/DCM_E_PENDING]
        arg OpStatus: type=Dcm_OpStatusType, direction=IN
        arg Data: type=Dcm_Data4ByteType, direction=OUT
      operation ConditionCheckRead: possible-error=[DataServices_DID_EE84_FIHSwReserved3/E_NOT_OK, DataServices_DID_EE84_FIHSwReserved3/DCM_E_PENDING]
        arg OpStatus: type=Dcm_OpStatusType, direction=IN
        arg ErrorCode: type=Dcm_NegativeResponseCodeType, direction=OUT
      operation WriteData: possible-error=[DataServices_DID_EE84_FIHSwReserved3/E_NOT_OK, DataServices_DID_EE84_FIHSwReserved3/DCM_E_PENDING]
        arg Data: type=Dcm_Data4ByteType, direction=IN
        arg OpStatus: type=Dcm_OpStatusType, direction=IN
        arg ErrorCode: type=Dcm_NegativeResponseCodeType, direction=OUT
      error E_NOT_OK: error-code=1
      error DCM_E_PENDING: error-code=10
    DataServices_DID_EE20_LoAFaultReporting
      operation ReadData: possible-error=[DataServices_DID_EE20_LoAFaultReporting/E_NOT_OK, DataServices_DID_EE20_LoAFaultReporting/DCM_E_PENDING]
        arg OpStatus: type=Dcm_OpStatusType, direction=IN
        arg Data: type=Dcm_Data24ByteType, direction=OUT
      operation ConditionCheckRead: possible-error=[DataServices_DID_EE20_LoAFaultReporting/E_NOT_OK, DataServices_DID_EE20_LoAFaultReporting/DCM_E_PENDING]
        arg OpStatus: type=Dcm_OpStatusType, direction=IN
        arg ErrorCode: type=Dcm_NegativeResponseCodeType, direction=OUT
      error E_NOT_OK: error-code=1
      error DCM_E_PENDING: error-code=10
    DataServices_DID_EE81_FIHSwReserved0
      operation ReadData: possible-error=[DataServices_DID_EE81_FIHSwReserved0/E_NOT_OK, DataServices_DID_EE81_FIHSwReserved0/DCM_E_PENDING]
        arg OpStatus: type=Dcm_OpStatusType, direction=IN
        arg Data: type=Dcm_Data4ByteType, direction=OUT
      operation ConditionCheckRead: possible-error=[DataServices_DID_EE81_FIHSwReserved0/E_NOT_OK, DataServices_DID_EE81_FIHSwReserved0/DCM_E_PENDING]
        arg OpStatus: type=Dcm_OpStatusType, direction=IN
        arg ErrorCode: type=Dcm_NegativeResponseCodeType, direction=OUT
      operation WriteData: possible-error=[DataServices_DID_EE81_FIHSwReserved0/E_NOT_OK, DataServices_DID_EE81_FIHSwReserved0/DCM_E_PENDING]
        arg Data: type=Dcm_Data4ByteType, direction=IN
        arg OpStatus: type=Dcm_OpStatusType, direction=IN
        arg ErrorCode: type=Dcm_NegativeResponseCodeType, direction=OUT
      error E_NOT_OK: error-code=1
      error DCM_E_PENDING: error-code=10
    DataServices_DID_F15F_NOS_Generation_Tool_Version_Number
      operation ReadData: possible-error=[DataServices_DID_F15F_NOS_Generation_Tool_Version_Number/E_NOT_OK, DataServices_DID_F15F_NOS_Generation_Tool_Version_Number/DCM_E_PENDING]
        arg OpStatus: type=Dcm_OpStatusType, direction=IN
        arg Data: type=Dcm_Data10ByteType, direction=OUT
      operation ConditionCheckRead: possible-error=[DataServices_DID_F15F_NOS_Generation_Tool_Version_Number/E_NOT_OK, DataServices_DID_F15F_NOS_Generation_Tool_Version_Number/DCM_E_PENDING]
        arg OpStatus: type=Dcm_OpStatusType, direction=IN
        arg ErrorCode: type=Dcm_NegativeResponseCodeType, direction=OUT
      error E_NOT_OK: error-code=1
      error DCM_E_PENDING: error-code=10
    DataServices_DID_EE06_VINChanged
      operation ReadData: possible-error=[DataServices_DID_EE06_VINChanged/E_NOT_OK, DataServices_DID_EE06_VINChanged/DCM_E_PENDING]
        arg OpStatus: type=Dcm_OpStatusType, direction=IN
        arg Data: type=Dcm_Data1ByteType, direction=OUT
      operation ConditionCheckRead: possible-error=[DataServices_DID_EE06_VINChanged/E_NOT_OK, DataServices_DID_EE06_VINChanged/DCM_E_PENDING]
        arg OpStatus: type=Dcm_OpStatusType, direction=IN
        arg ErrorCode: type=Dcm_NegativeResponseCodeType, direction=OUT
      error E_NOT_OK: error-code=1
      error DCM_E_PENDING: error-code=10
    DataServices_DID_DD00_Global_Real_Time
      operation ReadData: possible-error=[DataServices_DID_DD00_Global_Real_Time/E_NOT_OK, DataServices_DID_DD00_Global_Real_Time/DCM_E_PENDING]
        arg OpStatus: type=Dcm_OpStatusType, direction=IN
        arg Data: type=Dcm_Data4ByteType, direction=OUT
      operation ConditionCheckRead: possible-error=[DataServices_DID_DD00_Global_Real_Time/E_NOT_OK, DataServices_DID_DD00_Global_Real_Time/DCM_E_PENDING]
        arg OpStatus: type=Dcm_OpStatusType, direction=IN
        arg ErrorCode: type=Dcm_NegativeResponseCodeType, direction=OUT
      error E_NOT_OK: error-code=1
      error DCM_E_PENDING: error-code=10
    DataServices_DID_EE04_IgnOnTime
      operation ReadData: possible-error=[DataServices_DID_EE04_IgnOnTime/E_NOT_OK, DataServices_DID_EE04_IgnOnTime/DCM_E_PENDING]
        arg OpStatus: type=Dcm_OpStatusType, direction=IN
        arg Data: type=Dcm_Data2ByteType, direction=OUT
      operation ConditionCheckRead: possible-error=[DataServices_DID_EE04_IgnOnTime/E_NOT_OK, DataServices_DID_EE04_IgnOnTime/DCM_E_PENDING]
        arg OpStatus: type=Dcm_OpStatusType, direction=IN
        arg ErrorCode: type=Dcm_NegativeResponseCodeType, direction=OUT
      error E_NOT_OK: error-code=1
      error DCM_E_PENDING: error-code=10
    DataServices_DID_EE88_FIHSwReserved7
      operation ReadData: possible-error=[DataServices_DID_EE88_FIHSwReserved7/E_NOT_OK, DataServices_DID_EE88_FIHSwReserved7/DCM_E_PENDING]
        arg OpStatus: type=Dcm_OpStatusType, direction=IN
        arg Data: type=Dcm_Data4ByteType, direction=OUT
      operation ConditionCheckRead: possible-error=[DataServices_DID_EE88_FIHSwReserved7/E_NOT_OK, DataServices_DID_EE88_FIHSwReserved7/DCM_E_PENDING]
        arg OpStatus: type=Dcm_OpStatusType, direction=IN
        arg ErrorCode: type=Dcm_NegativeResponseCodeType, direction=OUT
      operation WriteData: possible-error=[DataServices_DID_EE88_FIHSwReserved7/E_NOT_OK, DataServices_DID_EE88_FIHSwReserved7/DCM_E_PENDING]
        arg Data: type=Dcm_Data4ByteType, direction=IN
        arg OpStatus: type=Dcm_OpStatusType, direction=IN
        arg ErrorCode: type=Dcm_NegativeResponseCodeType, direction=OUT
      error E_NOT_OK: error-code=1
      error DCM_E_PENDING: error-code=10
    DataServices_DID_EE41_ResearchFeatureSwitch
      operation ReadData: possible-error=[DataServices_DID_EE41_ResearchFeatureSwitch/E_NOT_OK, DataServices_DID_EE41_ResearchFeatureSwitch/DCM_E_PENDING]
        arg OpStatus: type=Dcm_OpStatusType, direction=IN
        arg Data: type=Dcm_Data1ByteType, direction=OUT
      operation ConditionCheckRead: possible-error=[DataServices_DID_EE41_ResearchFeatureSwitch/E_NOT_OK, DataServices_DID_EE41_ResearchFeatureSwitch/DCM_E_PENDING]
        arg OpStatus: type=Dcm_OpStatusType, direction=IN
        arg ErrorCode: type=Dcm_NegativeResponseCodeType, direction=OUT
      operation WriteData: possible-error=[DataServices_DID_EE41_ResearchFeatureSwitch/E_NOT_OK, DataServices_DID_EE41_ResearchFeatureSwitch/DCM_E_PENDING]
        arg Data: type=Dcm_Data1ByteType, direction=IN
        arg OpStatus: type=Dcm_OpStatusType, direction=IN
        arg ErrorCode: type=Dcm_NegativeResponseCodeType, direction=OUT
      error E_NOT_OK: error-code=1
      error DCM_E_PENDING: error-code=10
    DataServices_DID_EE85_FIHSwReserved4
      operation ReadData: possible-error=[DataServices_DID_EE85_FIHSwReserved4/E_NOT_OK, DataServices_DID_EE85_FIHSwReserved4/DCM_E_PENDING]
        arg OpStatus: type=Dcm_OpStatusType, direction=IN
        arg Data: type=Dcm_Data4ByteType, direction=OUT
      operation ConditionCheckRead: possible-error=[DataServices_DID_EE85_FIHSwReserved4/E_NOT_OK, DataServices_DID_EE85_FIHSwReserved4/DCM_E_PENDING]
        arg OpStatus: type=Dcm_OpStatusType, direction=IN
        arg ErrorCode: type=Dcm_NegativeResponseCodeType, direction=OUT
      operation WriteData: possible-error=[DataServices_DID_EE85_FIHSwReserved4/E_NOT_OK, DataServices_DID_EE85_FIHSwReserved4/DCM_E_PENDING]
        arg Data: type=Dcm_Data4ByteType, direction=IN
        arg OpStatus: type=Dcm_OpStatusType, direction=IN
        arg ErrorCode: type=Dcm_NegativeResponseCodeType, direction=OUT
      error E_NOT_OK: error-code=1
      error DCM_E_PENDING: error-code=10
    DataServices_DID_D118_Motor_Current
      operation ReadData: possible-error=[DataServices_DID_D118_Motor_Current/E_NOT_OK, DataServices_DID_D118_Motor_Current/DCM_E_PENDING]
        arg OpStatus: type=Dcm_OpStatusType, direction=IN
        arg Data: type=Dcm_Data2ByteType, direction=OUT
      operation ConditionCheckRead: possible-error=[DataServices_DID_D118_Motor_Current/E_NOT_OK, DataServices_DID_D118_Motor_Current/DCM_E_PENDING]
        arg OpStatus: type=Dcm_OpStatusType, direction=IN
        arg ErrorCode: type=Dcm_NegativeResponseCodeType, direction=OUT
      error E_NOT_OK: error-code=1
      error DCM_E_PENDING: error-code=10
    DataServices_DID_EED0_SupplierFactoryMode
      operation ReadData: possible-error=[DataServices_DID_EED0_SupplierFactoryMode/E_NOT_OK, DataServices_DID_EED0_SupplierFactoryMode/DCM_E_PENDING]
        arg OpStatus: type=Dcm_OpStatusType, direction=IN
        arg Data: type=Dcm_Data1ByteType, direction=OUT
      operation ConditionCheckRead: possible-error=[DataServices_DID_EED0_SupplierFactoryMode/E_NOT_OK, DataServices_DID_EED0_SupplierFactoryMode/DCM_E_PENDING]
        arg OpStatus: type=Dcm_OpStatusType, direction=IN
        arg ErrorCode: type=Dcm_NegativeResponseCodeType, direction=OUT
      operation WriteData: possible-error=[DataServices_DID_EED0_SupplierFactoryMode/E_NOT_OK, DataServices_DID_EED0_SupplierFactoryMode/DCM_E_PENDING]
        arg Data: type=Dcm_Data1ByteType, direction=IN
        arg OpStatus: type=Dcm_OpStatusType, direction=IN
        arg ErrorCode: type=Dcm_NegativeResponseCodeType, direction=OUT
      error E_NOT_OK: error-code=1
      error DCM_E_PENDING: error-code=10
    DataServices_DID_EE43_SDMSteeringMode
      operation ReadData: possible-error=[DataServices_DID_EE43_SDMSteeringMode/E_NOT_OK, DataServices_DID_EE43_SDMSteeringMode/DCM_E_PENDING]
        arg OpStatus: type=Dcm_OpStatusType, direction=IN
        arg Data: type=Dcm_Data1ByteType, direction=OUT
      operation ConditionCheckRead: possible-error=[DataServices_DID_EE43_SDMSteeringMode/E_NOT_OK, DataServices_DID_EE43_SDMSteeringMode/DCM_E_PENDING]
        arg OpStatus: type=Dcm_OpStatusType, direction=IN
        arg ErrorCode: type=Dcm_NegativeResponseCodeType, direction=OUT
      error E_NOT_OK: error-code=1
      error DCM_E_PENDING: error-code=10
    DataServices_DID_F17C_NOS_Bootloader_Generation_Tool_Version_Number
      operation ReadData: possible-error=[DataServices_DID_F17C_NOS_Bootloader_Generation_Tool_Version_Number/E_NOT_OK, DataServices_DID_F17C_NOS_Bootloader_Generation_Tool_Version_Number/DCM_E_PENDING]
        arg OpStatus: type=Dcm_OpStatusType, direction=IN
        arg Data: type=Dcm_Data11ByteType, direction=OUT
      operation ConditionCheckRead: possible-error=[DataServices_DID_F17C_NOS_Bootloader_Generation_Tool_Version_Number/E_NOT_OK, DataServices_DID_F17C_NOS_Bootloader_Generation_Tool_Version_Number/DCM_E_PENDING]
        arg OpStatus: type=Dcm_OpStatusType, direction=IN
        arg ErrorCode: type=Dcm_NegativeResponseCodeType, direction=OUT
      error E_NOT_OK: error-code=1
      error DCM_E_PENDING: error-code=10
    DataServices_DID_DE05_Unused
      operation ReadData: possible-error=[DataServices_DID_DE05_Unused/E_NOT_OK, DataServices_DID_DE05_Unused/DCM_E_PENDING]
        arg OpStatus: type=Dcm_OpStatusType, direction=IN
        arg Data: type=Dcm_Data24ByteType, direction=OUT
      operation ConditionCheckRead: possible-error=[DataServices_DID_DE05_Unused/E_NOT_OK, DataServices_DID_DE05_Unused/DCM_E_PENDING]
        arg OpStatus: type=Dcm_OpStatusType, direction=IN
        arg ErrorCode: type=Dcm_NegativeResponseCodeType, direction=OUT
      operation WriteData: possible-error=[DataServices_DID_DE05_Unused/E_NOT_OK, DataServices_DID_DE05_Unused/DCM_E_PENDING]
        arg Data: type=Dcm_Data24ByteType, direction=IN
        arg OpStatus: type=Dcm_OpStatusType, direction=IN
        arg ErrorCode: type=Dcm_NegativeResponseCodeType, direction=OUT
      error E_NOT_OK: error-code=1
      error DCM_E_PENDING: error-code=10
    DataServices_DIDRange_NexteerDidRangeF194toF1FF
      operation ReadDidData: possible-error=[DataServices_DIDRange_NexteerDidRangeF194toF1FF/E_NOT_OK, DataServices_DIDRange_NexteerDidRangeF194toF1FF/DCM_E_PENDING]
        5 x arg:
          DID: type=uint16, direction=IN
          Data: type=Dcm_Data1024ByteType, direction=OUT
          OpStatus: type=Dcm_OpStatusType, direction=IN
          DataLength: type=uint16, direction=OUT
          ErrorCode: type=Dcm_NegativeResponseCodeType, direction=OUT
      operation WriteDidData: possible-error=[DataServices_DIDRange_NexteerDidRangeF194toF1FF/E_NOT_OK, DataServices_DIDRange_NexteerDidRangeF194toF1FF/DCM_E_PENDING]
        5 x arg:
          DID: type=uint16, direction=IN
          Data: type=Dcm_Data1024ByteType, direction=IN
          OpStatus: type=Dcm_OpStatusType, direction=IN
          DataLength: type=uint16, direction=IN
          ErrorCode: type=Dcm_NegativeResponseCodeType, direction=OUT
      error E_NOT_OK: error-code=1
      error DCM_E_PENDING: error-code=10
    RoutineServices_RTN_Nexteer_F200_Micro_Diagnostic_Fault_Injection
      operation Start: possible-error=[RoutineServices_RTN_Nexteer_F200_Micro_Diagnostic_Fault_Injection/E_NOT_OK, RoutineServices_RTN_Nexteer_F200_Micro_Diagnostic_Fault_Injection/DCM_E_PENDING, RoutineServices_RTN_Nexteer_F200_Micro_Diagnostic_Fault_Injection/DCM_E_FORCE_RCRRP]
        arg Data: type=Dcm_Data4ByteType, direction=IN
        arg OpStatus: type=Dcm_OpStatusType, direction=IN
        arg ErrorCode: type=Dcm_NegativeResponseCodeType, direction=OUT
      error E_NOT_OK: error-code=1
      error DCM_E_PENDING: error-code=10
      error DCM_E_FORCE_RCRRP: error-code=12
    SecurityAccess_Un_locked_L3
      operation GetSeed: possible-error=[SecurityAccess_Un_locked_L3/E_NOT_OK, SecurityAccess_Un_locked_L3/DCM_E_PENDING]
        arg OpStatus: type=Dcm_OpStatusType, direction=IN
        arg Seed: type=Dcm_Data16ByteType, direction=OUT
        arg ErrorCode: type=Dcm_NegativeResponseCodeType, direction=OUT
      operation CompareKey: possible-error=[SecurityAccess_Un_locked_L3/E_NOT_OK, SecurityAccess_Un_locked_L3/DCM_E_PENDING, SecurityAccess_Un_locked_L3/DCM_E_COMPARE_KEY_FAILED]
        arg Key: type=Dcm_Data16ByteType, direction=IN
        arg OpStatus: type=Dcm_OpStatusType, direction=IN
        arg ErrorCode: type=Dcm_NegativeResponseCodeType, direction=OUT
      error E_NOT_OK: error-code=1
      error DCM_E_PENDING: error-code=10
      error DCM_E_COMPARE_KEY_FAILED: error-code=11
    RoutineServices_RTN_0202_On_Demand_Self_Test
      operation Start: possible-error=[RoutineServices_RTN_0202_On_Demand_Self_Test/E_NOT_OK, RoutineServices_RTN_0202_On_Demand_Self_Test/DCM_E_PENDING, RoutineServices_RTN_0202_On_Demand_Self_Test/DCM_E_FORCE_RCRRP]
        arg OpStatus: type=Dcm_OpStatusType, direction=IN
        arg Out_ResData: type=uint8, direction=OUT
        arg ErrorCode: type=Dcm_NegativeResponseCodeType, direction=OUT
      operation Stop: possible-error=[RoutineServices_RTN_0202_On_Demand_Self_Test/E_NOT_OK, RoutineServices_RTN_0202_On_Demand_Self_Test/DCM_E_PENDING, RoutineServices_RTN_0202_On_Demand_Self_Test/DCM_E_FORCE_RCRRP]
        arg OpStatus: type=Dcm_OpStatusType, direction=IN
        arg Out_ResData: type=uint8, direction=OUT
        arg ErrorCode: type=Dcm_NegativeResponseCodeType, direction=OUT
      operation RequestResults: possible-error=[RoutineServices_RTN_0202_On_Demand_Self_Test/E_NOT_OK, RoutineServices_RTN_0202_On_Demand_Self_Test/DCM_E_PENDING, RoutineServices_RTN_0202_On_Demand_Self_Test/DCM_E_FORCE_RCRRP]
        4 x arg:
          OpStatus: type=Dcm_OpStatusType, direction=IN
          Out_ResData: type=Dcm_Data159ByteType, direction=OUT
          DataLength: type=uint16, direction=OUT
          ErrorCode: type=Dcm_NegativeResponseCodeType, direction=OUT
      error E_NOT_OK: error-code=1
      error DCM_E_PENDING: error-code=10
      error DCM_E_FORCE_RCRRP: error-code=12
    RoutineServices_RTN_200E_Calibrate_Steering_Angle_Centre_Position
      operation Start: possible-error=[RoutineServices_RTN_200E_Calibrate_Steering_Angle_Centre_Position/E_NOT_OK, RoutineServices_RTN_200E_Calibrate_Steering_Angle_Centre_Position/DCM_E_PENDING, RoutineServices_RTN_200E_Calibrate_Steering_Angle_Centre_Position/DCM_E_FORCE_RCRRP]
        arg OpStatus: type=Dcm_OpStatusType, direction=IN
        arg Out_ResData: type=uint8, direction=OUT
        arg ErrorCode: type=Dcm_NegativeResponseCodeType, direction=OUT
      error E_NOT_OK: error-code=1
      error DCM_E_PENDING: error-code=10
      error DCM_E_FORCE_RCRRP: error-code=12
    RoutineServices_RTN_200F_Clear_Steering_Angle_Centre_Position_Calibration
      operation Start: possible-error=[RoutineServices_RTN_200F_Clear_Steering_Angle_Centre_Position_Calibration/E_NOT_OK, RoutineServices_RTN_200F_Clear_Steering_Angle_Centre_Position_Calibration/DCM_E_PENDING, RoutineServices_RTN_200F_Clear_Steering_Angle_Centre_Position_Calibration/DCM_E_FORCE_RCRRP]
        arg OpStatus: type=Dcm_OpStatusType, direction=IN
        arg Out_ResData: type=uint8, direction=OUT
        arg ErrorCode: type=Dcm_NegativeResponseCodeType, direction=OUT
      error E_NOT_OK: error-code=1
      error DCM_E_PENDING: error-code=10
      error DCM_E_FORCE_RCRRP: error-code=12
    RoutineServices_RTN_DC00_Reset_Assist_Fault_Counters
      operation Start: possible-error=[RoutineServices_RTN_DC00_Reset_Assist_Fault_Counters/E_NOT_OK, RoutineServices_RTN_DC00_Reset_Assist_Fault_Counters/DCM_E_PENDING, RoutineServices_RTN_DC00_Reset_Assist_Fault_Counters/DCM_E_FORCE_RCRRP]
        arg OpStatus: type=Dcm_OpStatusType, direction=IN
        arg Out_ResData: type=uint8, direction=OUT
        arg ErrorCode: type=Dcm_NegativeResponseCodeType, direction=OUT
      error E_NOT_OK: error-code=1
      error DCM_E_PENDING: error-code=10
      error DCM_E_FORCE_RCRRP: error-code=12
    DataServices_DID_EED2_SupplierInternalErrorMemory
      operation ReadData: possible-error=[DataServices_DID_EED2_SupplierInternalErrorMemory/E_NOT_OK, DataServices_DID_EED2_SupplierInternalErrorMemory/DCM_E_PENDING]
        arg OpStatus: type=Dcm_OpStatusType, direction=IN
        arg Data: type=Dcm_Data4ByteType, direction=OUT
      operation ConditionCheckRead: possible-error=[DataServices_DID_EED2_SupplierInternalErrorMemory/E_NOT_OK, DataServices_DID_EED2_SupplierInternalErrorMemory/DCM_E_PENDING]
        arg OpStatus: type=Dcm_OpStatusType, direction=IN
        arg ErrorCode: type=Dcm_NegativeResponseCodeType, direction=OUT
      error E_NOT_OK: error-code=1
      error DCM_E_PENDING: error-code=10
  mode switch interface Dcm_Read_BswM_MDGP_BswMEcuResetMod: is-service=true, service-kind=DIAGNOSTIC-COMMUNICATION-MANAGER
    mode group Dcm_Read_BswM_MDGP_BswMEcuResetMod: type=BswMEcuResetMod
  4 x client server interface, all with is-service=true, service-kind=DIAGNOSTIC-COMMUNICATION-MANAGER:
    RoutineServices_RTN_Nexteer_FD54_Clear_Stack_Measurement_Result
      operation Start: possible-error=[RoutineServices_RTN_Nexteer_FD54_Clear_Stack_Measurement_Result/E_NOT_OK, RoutineServices_RTN_Nexteer_FD54_Clear_Stack_Measurement_Result/DCM_E_PENDING, RoutineServices_RTN_Nexteer_FD54_Clear_Stack_Measurement_Result/DCM_E_FORCE_RCRRP]
        arg OpStatus: type=Dcm_OpStatusType, direction=IN
        arg ErrorCode: type=Dcm_NegativeResponseCodeType, direction=OUT
      error E_NOT_OK: error-code=1
      error DCM_E_PENDING: error-code=10
      error DCM_E_FORCE_RCRRP: error-code=12
    RoutineServices_RTN_Nexteer_FD71_Clear_Nexteer_Snapshot_Data_Start
      operation Start: possible-error=[RoutineServices_RTN_Nexteer_FD71_Clear_Nexteer_Snapshot_Data_Start/E_NOT_OK, RoutineServices_RTN_Nexteer_FD71_Clear_Nexteer_Snapshot_Data_Start/DCM_E_PENDING, RoutineServices_RTN_Nexteer_FD71_Clear_Nexteer_Snapshot_Data_Start/DCM_E_FORCE_RCRRP]
        arg OpStatus: type=Dcm_OpStatusType, direction=IN
        arg ErrorCode: type=Dcm_NegativeResponseCodeType, direction=OUT
      error E_NOT_OK: error-code=1
      error DCM_E_PENDING: error-code=10
      error DCM_E_FORCE_RCRRP: error-code=12
    RoutineServices_RTN_Nexteer_FE88_System_Friction_Learning_Clear
      operation Start: possible-error=[RoutineServices_RTN_Nexteer_FE88_System_Friction_Learning_Clear/E_NOT_OK, RoutineServices_RTN_Nexteer_FE88_System_Friction_Learning_Clear/DCM_E_PENDING, RoutineServices_RTN_Nexteer_FE88_System_Friction_Learning_Clear/DCM_E_FORCE_RCRRP]
        arg OpStatus: type=Dcm_OpStatusType, direction=IN
        arg ErrorCode: type=Dcm_NegativeResponseCodeType, direction=OUT
      error E_NOT_OK: error-code=1
      error DCM_E_PENDING: error-code=10
      error DCM_E_FORCE_RCRRP: error-code=12
    RoutineServices_RTN_Nexteer_FE89_System_Friction_Learning_Initialize
      operation Start: possible-error=[RoutineServices_RTN_Nexteer_FE89_System_Friction_Learning_Initialize/E_NOT_OK, RoutineServices_RTN_Nexteer_FE89_System_Friction_Learning_Initialize/DCM_E_PENDING, RoutineServices_RTN_Nexteer_FE89_System_Friction_Learning_Initialize/DCM_E_FORCE_RCRRP]
        arg OpStatus: type=Dcm_OpStatusType, direction=IN
        arg ErrorCode: type=Dcm_NegativeResponseCodeType, direction=OUT
      error E_NOT_OK: error-code=1
      error DCM_E_PENDING: error-code=10
      error DCM_E_FORCE_RCRRP: error-code=12
package /MICROSAR/Dcm_swc/ComponentTypes
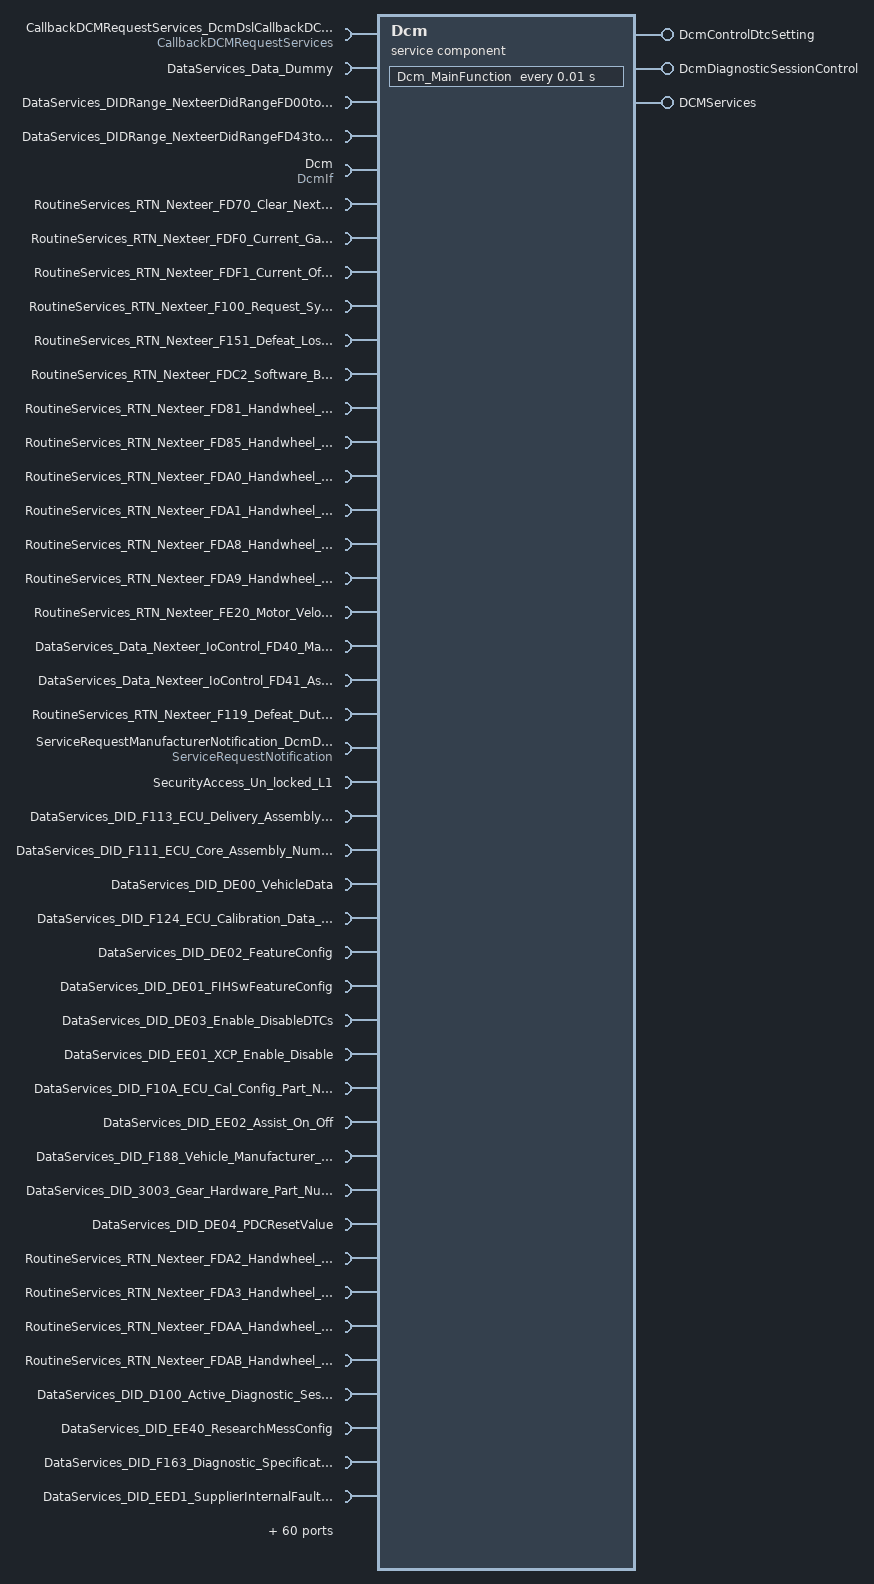
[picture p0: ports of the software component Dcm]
  service sw component type Dcm: category=SERVICE_COMPONENT
    provide port DcmControlDtcSetting: provided-interface=DcmControlDtcSetting
    provide port DcmDiagnosticSessionControl: provided-interface=DcmDiagnosticSessionControl
    provide port DCMServices: provided-interface=DCMServices
    104 x require port:
      CallbackDCMRequestServices_DcmDslCallbackDCMRequestService: required-interface=CallbackDCMRequestServices
      DataServices_Data_Dummy: required-interface=DataServices_Data_Dummy
      DataServices_DIDRange_NexteerDidRangeFD00toFD39: required-interface=DataServices_DIDRange_NexteerDidRangeFD00toFD39
      DataServices_DIDRange_NexteerDidRangeFD43toFEFF: required-interface=DataServices_DIDRange_NexteerDidRangeFD43toFEFF
      Dcm: required-interface=DcmIf
      RoutineServices_RTN_Nexteer_FD70_Clear_Nexteer_Trouble_Codes: required-interface=RoutineServices_RTN_Nexteer_FD70_Clear_Nexteer_Trouble_Codes
      RoutineServices_RTN_Nexteer_FDF0_Current_Gain_Auto_Trim: required-interface=RoutineServices_RTN_Nexteer_FDF0_Current_Gain_Auto_Trim
      RoutineServices_RTN_Nexteer_FDF1_Current_Offset_Auto_Trim: required-interface=RoutineServices_RTN_Nexteer_FDF1_Current_Offset_Auto_Trim
      RoutineServices_RTN_Nexteer_F100_Request_System_State_Enable: required-interface=RoutineServices_RTN_Nexteer_F100_Request_System_State_Enable
      RoutineServices_RTN_Nexteer_F151_Defeat_Loss_of_Assist_Scale: required-interface=RoutineServices_RTN_Nexteer_F151_Defeat_Loss_of_Assist_Scale
      RoutineServices_RTN_Nexteer_FDC2_Software_Based_Motor_Calibration: required-interface=RoutineServices_RTN_Nexteer_FDC2_Software_Based_Motor_Calibration
      RoutineServices_RTN_Nexteer_FD81_Handwheel_Angle_1_Auto_Trim: required-interface=RoutineServices_RTN_Nexteer_FD81_Handwheel_Angle_1_Auto_Trim
      RoutineServices_RTN_Nexteer_FD85_Handwheel_Angle_1_Clear_Trim: required-interface=RoutineServices_RTN_Nexteer_FD85_Handwheel_Angle_1_Clear_Trim
      RoutineServices_RTN_Nexteer_FDA0_Handwheel_Torque_Sensor_0_Auto_Trim: required-interface=RoutineServices_RTN_Nexteer_FDA0_Handwheel_Torque_Sensor_0_Auto_Trim
      RoutineServices_RTN_Nexteer_FDA1_Handwheel_Torque_Sensor_1_Auto_Trim: required-interface=RoutineServices_RTN_Nexteer_FDA1_Handwheel_Torque_Sensor_1_Auto_Trim
      RoutineServices_RTN_Nexteer_FDA8_Handwheel_Torque_Sensor_0_Clear_Trim: required-interface=RoutineServices_RTN_Nexteer_FDA8_Handwheel_Torque_Sensor_0_Clear_Trim
      RoutineServices_RTN_Nexteer_FDA9_Handwheel_Torque_Sensor_1_Clear_Trim: required-interface=RoutineServices_RTN_Nexteer_FDA9_Handwheel_Torque_Sensor_1_Clear_Trim
      RoutineServices_RTN_Nexteer_FE20_Motor_Velocity_Control: required-interface=RoutineServices_RTN_Nexteer_FE20_Motor_Velocity_Control
      DataServices_Data_Nexteer_IoControl_FD40_Manual_Torque_Command: required-interface=DataServices_Data_Nexteer_IoControl_FD40_Manual_Torque_Command
      DataServices_Data_Nexteer_IoControl_FD41_Assist_Linear_Gain: required-interface=DataServices_Data_Nexteer_IoControl_FD41_Assist_Linear_Gain
      RoutineServices_RTN_Nexteer_F119_Defeat_Duty_Cycle_Thermal_Protection: required-interface=RoutineServices_RTN_Nexteer_F119_Defeat_Duty_Cycle_Thermal_Protection
      ServiceRequestManufacturerNotification_DcmDslServiceRequestManufacturerNotification: required-interface=ServiceRequestNotification
      SecurityAccess_Un_locked_L1: required-interface=SecurityAccess_Un_locked_L1
      DataServices_DID_F113_ECU_Delivery_Assembly_Number: required-interface=DataServices_DID_F113_ECU_Delivery_Assembly_Number
      DataServices_DID_F111_ECU_Core_Assembly_Number: required-interface=DataServices_DID_F111_ECU_Core_Assembly_Number
      DataServices_DID_DE00_VehicleData: required-interface=DataServices_DID_DE00_VehicleData
      DataServices_DID_F124_ECU_Calibration_Data_1_Number: required-interface=DataServices_DID_F124_ECU_Calibration_Data_1_Number
      DataServices_DID_DE02_FeatureConfig: required-interface=DataServices_DID_DE02_FeatureConfig
      DataServices_DID_DE01_FIHSwFeatureConfig: required-interface=DataServices_DID_DE01_FIHSwFeatureConfig
      DataServices_DID_DE03_Enable_DisableDTCs: required-interface=DataServices_DID_DE03_Enable_DisableDTCs
      DataServices_DID_EE01_XCP_Enable_Disable: required-interface=DataServices_DID_EE01_XCP_Enable_Disable
      DataServices_DID_F10A_ECU_Cal_Config_Part_Number: required-interface=DataServices_DID_F10A_ECU_Cal_Config_Part_Number
      DataServices_DID_EE02_Assist_On_Off: required-interface=DataServices_DID_EE02_Assist_On_Off
      DataServices_DID_F188_Vehicle_Manufacturer_ECU_Software_Number: required-interface=DataServices_DID_F188_Vehicle_Manufacturer_ECU_Software_Number
      DataServices_DID_3003_Gear_Hardware_Part_Number: required-interface=DataServices_DID_3003_Gear_Hardware_Part_Number
      DataServices_DID_DE04_PDCResetValue: required-interface=DataServices_DID_DE04_PDCResetValue
      RoutineServices_RTN_Nexteer_FDA2_Handwheel_Torque_Sensor_2_Auto_Trim: required-interface=RoutineServices_RTN_Nexteer_FDA2_Handwheel_Torque_Sensor_2_Auto_Trim
      RoutineServices_RTN_Nexteer_FDA3_Handwheel_Torque_Sensor_3_Auto_Trim: required-interface=RoutineServices_RTN_Nexteer_FDA3_Handwheel_Torque_Sensor_3_Auto_Trim
      RoutineServices_RTN_Nexteer_FDAA_Handwheel_Torque_Sensor_2_Clear_Trim: required-interface=RoutineServices_RTN_Nexteer_FDAA_Handwheel_Torque_Sensor_2_Clear_Trim
      RoutineServices_RTN_Nexteer_FDAB_Handwheel_Torque_Sensor_3_Clear_Trim: required-interface=RoutineServices_RTN_Nexteer_FDAB_Handwheel_Torque_Sensor_3_Clear_Trim
      DataServices_DID_D100_Active_Diagnostic_Session: required-interface=DataServices_DID_D100_Active_Diagnostic_Session
      DataServices_DID_EE40_ResearchMessConfig: required-interface=DataServices_DID_EE40_ResearchMessConfig
      DataServices_DID_F163_Diagnostic_Specification_Version: required-interface=DataServices_DID_F163_Diagnostic_Specification_Version
      DataServices_DID_EED1_SupplierInternalFaultCode: required-interface=DataServices_DID_EED1_SupplierInternalFaultCode
      DataServices_DID_EE86_FIHSwReserved5: required-interface=DataServices_DID_EE86_FIHSwReserved5
      DataServices_DID_F166_NOS_Message_Database_1_Version_Number: required-interface=DataServices_DID_F166_NOS_Message_Database_1_Version_Number
      DataServices_DID_3B4B_Steering_wheel_angle_alignment_offset: required-interface=DataServices_DID_3B4B_Steering_wheel_angle_alignment_offset
      DataServices_DID_EE05_FinalMotTq: required-interface=DataServices_DID_EE05_FinalMotTq
      DataServices_DID_D111_ECU_Power_Supply_Voltage: required-interface=DataServices_DID_D111_ECU_Power_Supply_Voltage
      DataServices_DID_DD01_Total_Distance: required-interface=DataServices_DID_DD01_Total_Distance
      DataServices_DID_330C_Steering_Shaft_Torque_Sensor_2: required-interface=DataServices_DID_330C_Steering_Shaft_Torque_Sensor_2
      DataServices_DID_205B_Brake_Pull_Reduction_Activation_Counter: required-interface=DataServices_DID_205B_Brake_Pull_Reduction_Activation_Counter
      DataServices_DID_EE80_FIHSwVer: required-interface=DataServices_DID_EE80_FIHSwVer
      DataServices_DID_F162_Software_Download_Specification_Version: required-interface=DataServices_DID_F162_Software_Download_Specification_Version
      DataServices_DID_F180_Boot_Software_Identification: required-interface=DataServices_DID_F180_Boot_Software_Identification
      DataServices_DID_D117_ECU_Internal_Temperature: required-interface=DataServices_DID_D117_ECU_Internal_Temperature
      DataServices_DID_205A_Torque_Steer_Compensation_Activation_Counter: required-interface=DataServices_DID_205A_Torque_Steer_Compensation_Activation_Counter
      DataServices_DID_EE87_FIHSwReserved6: required-interface=DataServices_DID_EE87_FIHSwReserved6
      DataServices_DID_630F_Multiple_VIN_Storage_Original_VIN: required-interface=DataServices_DID_630F_Multiple_VIN_Storage_Original_VIN
      DataServices_DID_F110_Subsystem_Specific_Diagnostic_Specification_Part_Number: required-interface=DataServices_DID_F110_Subsystem_Specific_Diagnostic_Specification_Part_Number
      DataServices_DID_EE42_ActiveFeatures: required-interface=DataServices_DID_EE42_ActiveFeatures
      DataServices_DID_EE22_VoltageLvlCounters: required-interface=DataServices_DID_EE22_VoltageLvlCounters
      DataServices_DID_EE03_IgnCycleCounter: required-interface=DataServices_DID_EE03_IgnCycleCounter
      DataServices_DID_301A_Pull_Drift_Compensation_Value: required-interface=DataServices_DID_301A_Pull_Drift_Compensation_Value
      DataServices_DID_EE83_FIHSwReserved2: required-interface=DataServices_DID_EE83_FIHSwReserved2
      DataServices_DID_F190_Vehicle_Identification_Number: required-interface=DataServices_DID_F190_Vehicle_Identification_Number
      DataServices_DID_EE00_DevMessConfig: required-interface=DataServices_DID_EE00_DevMessConfig
      DataServices_DID_3020_Steering_Pinion_Angle: required-interface=DataServices_DID_3020_Steering_Pinion_Angle
      DataServices_DID_EE07_EPSSystemState: required-interface=DataServices_DID_EE07_EPSSystemState
      DataServices_DID_EE23_TempLvlCounters: required-interface=DataServices_DID_EE23_TempLvlCounters
      DataServices_DID_DD09_Vehicle_Speed: required-interface=DataServices_DID_DD09_Vehicle_Speed
      DataServices_DID_EE21_CurrentLvlCounter: required-interface=DataServices_DID_EE21_CurrentLvlCounter
      DataServices_DID_301F_Steering_Pinion_Rotation_Speed: required-interface=DataServices_DID_301F_Steering_Pinion_Rotation_Speed
      DataServices_DID_F18A_System_Supplier_Identifier: required-interface=DataServices_DID_F18A_System_Supplier_Identifier
      DataServices_DID_F18C_ECU_Serial_Number: required-interface=DataServices_DID_F18C_ECU_Serial_Number
      DataServices_DID_EE82_FIHSwReserved1: required-interface=DataServices_DID_EE82_FIHSwReserved1
      DataServices_DID_EE84_FIHSwReserved3: required-interface=DataServices_DID_EE84_FIHSwReserved3
      DataServices_DID_EE20_LoAFaultReporting: required-interface=DataServices_DID_EE20_LoAFaultReporting
      DataServices_DID_EE81_FIHSwReserved0: required-interface=DataServices_DID_EE81_FIHSwReserved0
      DataServices_DID_F15F_NOS_Generation_Tool_Version_Number: required-interface=DataServices_DID_F15F_NOS_Generation_Tool_Version_Number
      DataServices_DID_EE06_VINChanged: required-interface=DataServices_DID_EE06_VINChanged
      DataServices_DID_DD00_Global_Real_Time: required-interface=DataServices_DID_DD00_Global_Real_Time
      DataServices_DID_EE04_IgnOnTime: required-interface=DataServices_DID_EE04_IgnOnTime
      DataServices_DID_EE88_FIHSwReserved7: required-interface=DataServices_DID_EE88_FIHSwReserved7
      DataServices_DID_EE41_ResearchFeatureSwitch: required-interface=DataServices_DID_EE41_ResearchFeatureSwitch
      DataServices_DID_EE85_FIHSwReserved4: required-interface=DataServices_DID_EE85_FIHSwReserved4
      DataServices_DID_D118_Motor_Current: required-interface=DataServices_DID_D118_Motor_Current
      DataServices_DID_EED0_SupplierFactoryMode: required-interface=DataServices_DID_EED0_SupplierFactoryMode
      DataServices_DID_EE43_SDMSteeringMode: required-interface=DataServices_DID_EE43_SDMSteeringMode
      DataServices_DID_F17C_NOS_Bootloader_Generation_Tool_Version_Number: required-interface=DataServices_DID_F17C_NOS_Bootloader_Generation_Tool_Version_Number
      DataServices_DID_DE05_Unused: required-interface=DataServices_DID_DE05_Unused
      DataServices_DIDRange_NexteerDidRangeF194toF1FF: required-interface=DataServices_DIDRange_NexteerDidRangeF194toF1FF
      RoutineServices_RTN_Nexteer_F200_Micro_Diagnostic_Fault_Injection: required-interface=RoutineServices_RTN_Nexteer_F200_Micro_Diagnostic_Fault_Injection
      SecurityAccess_Un_locked_L3: required-interface=SecurityAccess_Un_locked_L3
      RoutineServices_RTN_0202_On_Demand_Self_Test: required-interface=RoutineServices_RTN_0202_On_Demand_Self_Test
      RoutineServices_RTN_200E_Calibrate_Steering_Angle_Centre_Position: required-interface=RoutineServices_RTN_200E_Calibrate_Steering_Angle_Centre_Position
      RoutineServices_RTN_200F_Clear_Steering_Angle_Centre_Position_Calibration: required-interface=RoutineServices_RTN_200F_Clear_Steering_Angle_Centre_Position_Calibration
      RoutineServices_RTN_DC00_Reset_Assist_Fault_Counters: required-interface=RoutineServices_RTN_DC00_Reset_Assist_Fault_Counters
      DataServices_DID_EED2_SupplierInternalErrorMemory: required-interface=DataServices_DID_EED2_SupplierInternalErrorMemory
      Dcm_Read_BswM_MDGP_BswMEcuResetMod: mode-switch-receiver-com-spec=enhanced-mode-api=true, required-interface=Dcm_Read_BswM_MDGP_BswMEcuResetMod
      RoutineServices_RTN_Nexteer_FD54_Clear_Stack_Measurement_Result: required-interface=RoutineServices_RTN_Nexteer_FD54_Clear_Stack_Measurement_Result
      RoutineServices_RTN_Nexteer_FD71_Clear_Nexteer_Snapshot_Data_Start: required-interface=RoutineServices_RTN_Nexteer_FD71_Clear_Nexteer_Snapshot_Data_Start
      RoutineServices_RTN_Nexteer_FE88_System_Friction_Learning_Clear: required-interface=RoutineServices_RTN_Nexteer_FE88_System_Friction_Learning_Clear
      RoutineServices_RTN_Nexteer_FE89_System_Friction_Learning_Initialize: required-interface=RoutineServices_RTN_Nexteer_FE89_System_Friction_Learning_Initialize
    behavior DcmInternalBehavior: data-type-mapping=DcmMappingSet, handle-termination-and-restart=NO-SUPPORT, included-data-type-set=data-type=[Dcm_ConfirmationStatusType, Dcm_OpStatusType, Dcm_NegativeResponseCodeType, Dcm_ProtocolType, Dcm_RequestKindType, Dcm_SecLevelType, Dcm_SesCtrlType, Dcm_ControlDtcSettingType, Dcm_DiagnosticSessionControlType, Dcm_CommunicationModeType]
      timing event Timer_Dcm_MainFunction: start-on-event=Dcm_MainFunction, period=0.01
      7 x operation invoked event:
        OpEventGetActiveProtocol_GetActiveProtocol_DCMServices: start-on-event=GetActiveProtocol, operation=DCMServices.GetActiveProtocol
        OpEventGetSesCtrlType_GetSesCtrlType_DCMServices: start-on-event=GetSesCtrlType, operation=DCMServices.GetSesCtrlType
        OpEventResetToDefaultSession_ResetToDefaultSession_DCMServices: start-on-event=ResetToDefaultSession, operation=DCMServices.ResetToDefaultSession
        OpEventSetActiveDiagnostic_SetActiveDiagnostic_DCMServices: start-on-event=SetActiveDiagnostic, operation=DCMServices.SetActiveDiagnostic
        OpEventGetRequestKind_GetRequestKind_DCMServices: start-on-event=GetRequestKind, operation=DCMServices.GetRequestKind
        OpEventGetSecurityLevel_GetSecurityLevel_DCMServices: start-on-event=GetSecurityLevel, operation=DCMServices.GetSecurityLevel
        OpEventGetSecurityLevelFixedBytes_GetSecurityLevelFixedBytes_DCMServices: start-on-event=GetSecurityLevelFixedBytes, operation=DCMServices.GetSecurityLevelFixedBytes
      port-api-options:
        enable-take-address=true, indirect-api=false, port=DcmControlDtcSetting
        enable-take-address=true, indirect-api=false, port=DcmDiagnosticSessionControl
        enable-take-address=true, indirect-api=false, port=DCMServices
        enable-take-address=true, indirect-api=false, port=ServiceRequestManufacturerNotification_DcmDslServiceRequestManufacturerNotification
        enable-take-address=true, indirect-api=false, port=CallbackDCMRequestServices_DcmDslCallbackDCMRequestService
        enable-take-address=true, indirect-api=false, port=SecurityAccess_Un_locked_L1
        enable-take-address=true, indirect-api=false, port=RoutineServices_RTN_Nexteer_F100_Request_System_State_Enable
        enable-take-address=true, indirect-api=false, port=RoutineServices_RTN_Nexteer_F119_Defeat_Duty_Cycle_Thermal_Protection
        enable-take-address=true, indirect-api=false, port=RoutineServices_RTN_Nexteer_F151_Defeat_Loss_of_Assist_Scale
        enable-take-address=true, indirect-api=false, port=RoutineServices_RTN_Nexteer_FD70_Clear_Nexteer_Trouble_Codes
        enable-take-address=true, indirect-api=false, port=RoutineServices_RTN_Nexteer_FD81_Handwheel_Angle_1_Auto_Trim
        enable-take-address=true, indirect-api=false, port=RoutineServices_RTN_Nexteer_FD85_Handwheel_Angle_1_Clear_Trim
        enable-take-address=true, indirect-api=false, port=RoutineServices_RTN_Nexteer_FDA{0..3}_Handwheel_Torque_Sensor_{0..3}_Auto_Trim
        enable-take-address=true, indirect-api=false, port=RoutineServices_RTN_Nexteer_FDA8_Handwheel_Torque_Sensor_0_Clear_Trim
        enable-take-address=true, indirect-api=false, port=RoutineServices_RTN_Nexteer_FDA9_Handwheel_Torque_Sensor_1_Clear_Trim
        enable-take-address=true, indirect-api=false, port=RoutineServices_RTN_Nexteer_FDAA_Handwheel_Torque_Sensor_2_Clear_Trim
        enable-take-address=true, indirect-api=false, port=RoutineServices_RTN_Nexteer_FDAB_Handwheel_Torque_Sensor_3_Clear_Trim
        enable-take-address=true, indirect-api=false, port=RoutineServices_RTN_Nexteer_FDC2_Software_Based_Motor_Calibration
        enable-take-address=true, indirect-api=false, port=RoutineServices_RTN_Nexteer_FDF0_Current_Gain_Auto_Trim
        enable-take-address=true, indirect-api=false, port=RoutineServices_RTN_Nexteer_FDF1_Current_Offset_Auto_Trim
        enable-take-address=true, indirect-api=false, port=RoutineServices_RTN_Nexteer_FE20_Motor_Velocity_Control
        enable-take-address=true, indirect-api=false, port=DataServices_DID_F113_ECU_Delivery_Assembly_Number
        enable-take-address=true, indirect-api=false, port=DataServices_DID_F111_ECU_Core_Assembly_Number
        enable-take-address=true, indirect-api=false, port=DataServices_Data_Dummy
        enable-take-address=true, indirect-api=false, port=DataServices_Data_Nexteer_IoControl_FD40_Manual_Torque_Command
        enable-take-address=true, indirect-api=false, port=DataServices_Data_Nexteer_IoControl_FD41_Assist_Linear_Gain
        enable-take-address=true, indirect-api=false, port=DataServices_DID_DE00_VehicleData
        enable-take-address=true, indirect-api=false, port=DataServices_DID_F124_ECU_Calibration_Data_1_Number
        enable-take-address=true, indirect-api=false, port=DataServices_DID_DE02_FeatureConfig
        enable-take-address=true, indirect-api=false, port=DataServices_DID_DE01_FIHSwFeatureConfig
        enable-take-address=true, indirect-api=false, port=DataServices_DID_DE03_Enable_DisableDTCs
        enable-take-address=true, indirect-api=false, port=DataServices_DID_EE01_XCP_Enable_Disable
        enable-take-address=true, indirect-api=false, port=DataServices_DID_F10A_ECU_Cal_Config_Part_Number
        enable-take-address=true, indirect-api=false, port=DataServices_DID_EE02_Assist_On_Off
        enable-take-address=true, indirect-api=false, port=DataServices_DID_F188_Vehicle_Manufacturer_ECU_Software_Number
        enable-take-address=true, indirect-api=false, port=DataServices_DID_3003_Gear_Hardware_Part_Number
        enable-take-address=true, indirect-api=false, port=DataServices_DID_DE04_PDCResetValue
        enable-take-address=true, indirect-api=false, port=DataServices_DIDRange_NexteerDidRangeFD00toFD39
        enable-take-address=true, indirect-api=false, port=DataServices_DIDRange_NexteerDidRangeFD43toFEFF
        enable-take-address=true, indirect-api=false, port=Dcm
        enable-take-address=true, indirect-api=false, port=DataServices_DID_D100_Active_Diagnostic_Session
        enable-take-address=true, indirect-api=false, port=DataServices_DID_EE40_ResearchMessConfig
        enable-take-address=true, indirect-api=false, port=DataServices_DID_F163_Diagnostic_Specification_Version
        enable-take-address=true, indirect-api=false, port=DataServices_DID_EED1_SupplierInternalFaultCode
        enable-take-address=true, indirect-api=false, port=DataServices_DID_EE86_FIHSwReserved5
        enable-take-address=true, indirect-api=false, port=DataServices_DID_F166_NOS_Message_Database_1_Version_Number
        enable-take-address=true, indirect-api=false, port=DataServices_DID_3B4B_Steering_wheel_angle_alignment_offset
        enable-take-address=true, indirect-api=false, port=DataServices_DID_EE05_FinalMotTq
        enable-take-address=true, indirect-api=false, port=DataServices_DID_D111_ECU_Power_Supply_Voltage
        enable-take-address=true, indirect-api=false, port=DataServices_DID_DD01_Total_Distance
        enable-take-address=true, indirect-api=false, port=DataServices_DID_330C_Steering_Shaft_Torque_Sensor_2
        enable-take-address=true, indirect-api=false, port=DataServices_DID_205B_Brake_Pull_Reduction_Activation_Counter
        enable-take-address=true, indirect-api=false, port=DataServices_DID_EE80_FIHSwVer
        enable-take-address=true, indirect-api=false, port=DataServices_DID_F162_Software_Download_Specification_Version
        enable-take-address=true, indirect-api=false, port=DataServices_DID_F180_Boot_Software_Identification
        enable-take-address=true, indirect-api=false, port=DataServices_DID_D117_ECU_Internal_Temperature
        enable-take-address=true, indirect-api=false, port=DataServices_DID_205A_Torque_Steer_Compensation_Activation_Counter
        enable-take-address=true, indirect-api=false, port=DataServices_DID_EE87_FIHSwReserved6
        enable-take-address=true, indirect-api=false, port=DataServices_DID_630F_Multiple_VIN_Storage_Original_VIN
        enable-take-address=true, indirect-api=false, port=DataServices_DID_F110_Subsystem_Specific_Diagnostic_Specification_Part_Number
        enable-take-address=true, indirect-api=false, port=DataServices_DID_EE42_ActiveFeatures
        enable-take-address=true, indirect-api=false, port=DataServices_DID_EE22_VoltageLvlCounters
        enable-take-address=true, indirect-api=false, port=DataServices_DID_EE03_IgnCycleCounter
        enable-take-address=true, indirect-api=false, port=DataServices_DID_301A_Pull_Drift_Compensation_Value
        enable-take-address=true, indirect-api=false, port=DataServices_DID_EE83_FIHSwReserved2
        enable-take-address=true, indirect-api=false, port=DataServices_DID_F190_Vehicle_Identification_Number
        enable-take-address=true, indirect-api=false, port=DataServices_DID_EE00_DevMessConfig
        enable-take-address=true, indirect-api=false, port=DataServices_DID_3020_Steering_Pinion_Angle
        enable-take-address=true, indirect-api=false, port=DataServices_DID_EE07_EPSSystemState
        enable-take-address=true, indirect-api=false, port=DataServices_DID_EE23_TempLvlCounters
        enable-take-address=true, indirect-api=false, port=DataServices_DID_DD09_Vehicle_Speed
        enable-take-address=true, indirect-api=false, port=DataServices_DID_EE21_CurrentLvlCounter
        enable-take-address=true, indirect-api=false, port=DataServices_DID_301F_Steering_Pinion_Rotation_Speed
        enable-take-address=true, indirect-api=false, port=DataServices_DID_F18A_System_Supplier_Identifier
        enable-take-address=true, indirect-api=false, port=DataServices_DID_F18C_ECU_Serial_Number
        enable-take-address=true, indirect-api=false, port=DataServices_DID_EE82_FIHSwReserved1
        enable-take-address=true, indirect-api=false, port=DataServices_DID_EE84_FIHSwReserved3
        enable-take-address=true, indirect-api=false, port=DataServices_DID_EE20_LoAFaultReporting
        enable-take-address=true, indirect-api=false, port=DataServices_DID_EE81_FIHSwReserved0
        enable-take-address=true, indirect-api=false, port=DataServices_DID_F15F_NOS_Generation_Tool_Version_Number
        enable-take-address=true, indirect-api=false, port=DataServices_DID_EE06_VINChanged
        enable-take-address=true, indirect-api=false, port=DataServices_DID_DD00_Global_Real_Time
        enable-take-address=true, indirect-api=false, port=DataServices_DID_EE04_IgnOnTime
        enable-take-address=true, indirect-api=false, port=DataServices_DID_EE88_FIHSwReserved7
        enable-take-address=true, indirect-api=false, port=DataServices_DID_EE41_ResearchFeatureSwitch
        enable-take-address=true, indirect-api=false, port=DataServices_DID_EE85_FIHSwReserved4
        enable-take-address=true, indirect-api=false, port=DataServices_DID_D118_Motor_Current
        enable-take-address=true, indirect-api=false, port=DataServices_DID_EED0_SupplierFactoryMode
        enable-take-address=true, indirect-api=false, port=DataServices_DID_EE43_SDMSteeringMode
        enable-take-address=true, indirect-api=false, port=DataServices_DID_F17C_NOS_Bootloader_Generation_Tool_Version_Number
        enable-take-address=true, indirect-api=false, port=DataServices_DID_DE05_Unused
        enable-take-address=true, indirect-api=false, port=DataServices_DIDRange_NexteerDidRangeF194toF1FF
        enable-take-address=true, indirect-api=false, port=RoutineServices_RTN_Nexteer_F200_Micro_Diagnostic_Fault_Injection
        enable-take-address=true, indirect-api=false, port=SecurityAccess_Un_locked_L3
        enable-take-address=true, indirect-api=false, port=RoutineServices_RTN_0202_On_Demand_Self_Test
        enable-take-address=true, indirect-api=false, port=RoutineServices_RTN_200E_Calibrate_Steering_Angle_Centre_Position
        enable-take-address=true, indirect-api=false, port=RoutineServices_RTN_200F_Clear_Steering_Angle_Centre_Position_Calibration
        enable-take-address=true, indirect-api=false, port=RoutineServices_RTN_DC00_Reset_Assist_Fault_Counters
        enable-take-address=true, indirect-api=false, port=DataServices_DID_EED2_SupplierInternalErrorMemory
        enable-take-address=true, indirect-api=false, port=Dcm_Read_BswM_MDGP_BswMEcuResetMod
        enable-take-address=true, indirect-api=false, port=RoutineServices_RTN_Nexteer_FD54_Clear_Stack_Measurement_Result
        enable-take-address=true, indirect-api=false, port=RoutineServices_RTN_Nexteer_FD71_Clear_Nexteer_Snapshot_Data_Start
        enable-take-address=true, indirect-api=false, port=RoutineServices_RTN_Nexteer_FE88_System_Friction_Learning_Clear
        enable-take-address=true, indirect-api=false, port=RoutineServices_RTN_Nexteer_FE89_System_Friction_Learning_Initialize
      8 x runnable:
        Dcm_MainFunction: mode-access-point=Dcm_Read_BswM_MDGP_BswMEcuResetMod.Dcm_Read_BswM_MDGP_BswMEcuResetMod
          mode switch point ModeSwitchPointDcm_MainFunction_DcmControlDtcSetting_DcmControlDtcSetting: mode-group=DcmControlDtcSetting.DcmControlDtcSetting
          mode switch point ModeSwitchPointDcm_MainFunction_DcmDiagnosticSessionControl_DcmDiagnosticSessionControl: mode-group=DcmDiagnosticSessionControl.DcmDiagnosticSessionControl
          230 x sync call, all with timeout=0:
            OpServerCallDcm_MainFunction_StartProtocol_CallbackDCMRequestServices_DcmDslCallbackDCMRequestService: operation=CallbackDCMRequestServices_DcmDslCallbackDCMRequestService.StartProtocol
            OpServerCallDcm_MainFunction_ReadData_DataServices_Data_Dummy: operation=DataServices_Data_Dummy.ReadData
            OpServerCallDcm_MainFunction_ReadDataLength_DataServices_Data_Dummy: operation=DataServices_Data_Dummy.ReadDataLength
            OpServerCallDcm_MainFunction_WriteData_DataServices_Data_Dummy: operation=DataServices_Data_Dummy.WriteData
            OpServerCallDcm_MainFunction_ReturnControlToECU_DataServices_Data_Dummy: operation=DataServices_Data_Dummy.ReturnControlToECU
            OpServerCallDcm_MainFunction_ShortTermAdjustment_DataServices_Data_Dummy: operation=DataServices_Data_Dummy.ShortTermAdjustment
            OpServerCallDcm_MainFunction_ReadDidData_DataServices_DIDRange_NexteerDidRangeFD00toFD39: operation=DataServices_DIDRange_NexteerDidRangeFD00toFD39.ReadDidData
            OpServerCallDcm_MainFunction_WriteDidData_DataServices_DIDRange_NexteerDidRangeFD00toFD39: operation=DataServices_DIDRange_NexteerDidRangeFD00toFD39.WriteDidData
            OpServerCallDcm_MainFunction_ReadDidData_DataServices_DIDRange_NexteerDidRangeFD43toFEFF: operation=DataServices_DIDRange_NexteerDidRangeFD43toFEFF.ReadDidData
            OpServerCallDcm_MainFunction_WriteDidData_DataServices_DIDRange_NexteerDidRangeFD43toFEFF: operation=DataServices_DIDRange_NexteerDidRangeFD43toFEFF.WriteDidData
            OpServerCallDcm_MainFunction_DcmEnableDTCSetting_Dcm: operation=Dcm.DcmEnableDTCSetting
            OpServerCallDcm_MainFunction_DcmGetExtendedDataRecordByDTC_Dcm: operation=Dcm.DcmGetExtendedDataRecordByDTC
            OpServerCallDcm_MainFunction_Start_RoutineServices_RTN_Nexteer_FD70_Clear_Nexteer_Trouble_Codes: operation=RoutineServices_RTN_Nexteer_FD70_Clear_Nexteer_Trouble_Codes.Start
            OpServerCallDcm_MainFunction_Start_RoutineServices_RTN_Nexteer_FDF0_Current_Gain_Auto_Trim: operation=RoutineServices_RTN_Nexteer_FDF0_Current_Gain_Auto_Trim.Start
            OpServerCallDcm_MainFunction_RequestResults_RoutineServices_RTN_Nexteer_FDF0_Current_Gain_Auto_Trim: operation=RoutineServices_RTN_Nexteer_FDF0_Current_Gain_Auto_Trim.RequestResults
            OpServerCallDcm_MainFunction_Start_RoutineServices_RTN_Nexteer_FDF1_Current_Offset_Auto_Trim: operation=RoutineServices_RTN_Nexteer_FDF1_Current_Offset_Auto_Trim.Start
            OpServerCallDcm_MainFunction_RequestResults_RoutineServices_RTN_Nexteer_FDF1_Current_Offset_Auto_Trim: operation=RoutineServices_RTN_Nexteer_FDF1_Current_Offset_Auto_Trim.RequestResults
            OpServerCallDcm_MainFunction_Start_RoutineServices_RTN_Nexteer_F100_Request_System_State_Enable: operation=RoutineServices_RTN_Nexteer_F100_Request_System_State_Enable.Start
            OpServerCallDcm_MainFunction_RequestResults_RoutineServices_RTN_Nexteer_F100_Request_System_State_Enable: operation=RoutineServices_RTN_Nexteer_F100_Request_System_State_Enable.RequestResults
            OpServerCallDcm_MainFunction_Stop_RoutineServices_RTN_Nexteer_F100_Request_System_State_Enable: operation=RoutineServices_RTN_Nexteer_F100_Request_System_State_Enable.Stop
            OpServerCallDcm_MainFunction_Start_RoutineServices_RTN_Nexteer_F151_Defeat_Loss_of_Assist_Scale: operation=RoutineServices_RTN_Nexteer_F151_Defeat_Loss_of_Assist_Scale.Start
            OpServerCallDcm_MainFunction_Stop_RoutineServices_RTN_Nexteer_F151_Defeat_Loss_of_Assist_Scale: operation=RoutineServices_RTN_Nexteer_F151_Defeat_Loss_of_Assist_Scale.Stop
            OpServerCallDcm_MainFunction_RequestResults_RoutineServices_RTN_Nexteer_F151_Defeat_Loss_of_Assist_Scale: operation=RoutineServices_RTN_Nexteer_F151_Defeat_Loss_of_Assist_Scale.RequestResults
            OpServerCallDcm_MainFunction_Start_RoutineServices_RTN_Nexteer_FDC2_Software_Based_Motor_Calibration: operation=RoutineServices_RTN_Nexteer_FDC2_Software_Based_Motor_Calibration.Start
            OpServerCallDcm_MainFunction_Stop_RoutineServices_RTN_Nexteer_FDC2_Software_Based_Motor_Calibration: operation=RoutineServices_RTN_Nexteer_FDC2_Software_Based_Motor_Calibration.Stop
            OpServerCallDcm_MainFunction_RequestResults_RoutineServices_RTN_Nexteer_FDC2_Software_Based_Motor_Calibration: operation=RoutineServices_RTN_Nexteer_FDC2_Software_Based_Motor_Calibration.RequestResults
            OpServerCallDcm_MainFunction_Start_RoutineServices_RTN_Nexteer_FD81_Handwheel_Angle_1_Auto_Trim: operation=RoutineServices_RTN_Nexteer_FD81_Handwheel_Angle_1_Auto_Trim.Start
            OpServerCallDcm_MainFunction_Start_RoutineServices_RTN_Nexteer_FD85_Handwheel_Angle_1_Clear_Trim: operation=RoutineServices_RTN_Nexteer_FD85_Handwheel_Angle_1_Clear_Trim.Start
            OpServerCallDcm_MainFunction_Start_RoutineServices_RTN_Nexteer_FDA0_Handwheel_Torque_Sensor_0_Auto_Trim: operation=RoutineServices_RTN_Nexteer_FDA0_Handwheel_Torque_Sensor_0_Auto_Trim.Start
            OpServerCallDcm_MainFunction_Start_RoutineServices_RTN_Nexteer_FDA1_Handwheel_Torque_Sensor_1_Auto_Trim: operation=RoutineServices_RTN_Nexteer_FDA1_Handwheel_Torque_Sensor_1_Auto_Trim.Start
            OpServerCallDcm_MainFunction_Start_RoutineServices_RTN_Nexteer_FDA8_Handwheel_Torque_Sensor_0_Clear_Trim: operation=RoutineServices_RTN_Nexteer_FDA8_Handwheel_Torque_Sensor_0_Clear_Trim.Start
            OpServerCallDcm_MainFunction_Start_RoutineServices_RTN_Nexteer_FDA9_Handwheel_Torque_Sensor_1_Clear_Trim: operation=RoutineServices_RTN_Nexteer_FDA9_Handwheel_Torque_Sensor_1_Clear_Trim.Start
            OpServerCallDcm_MainFunction_Start_RoutineServices_RTN_Nexteer_FE20_Motor_Velocity_Control: operation=RoutineServices_RTN_Nexteer_FE20_Motor_Velocity_Control.Start
            OpServerCallDcm_MainFunction_Stop_RoutineServices_RTN_Nexteer_FE20_Motor_Velocity_Control: operation=RoutineServices_RTN_Nexteer_FE20_Motor_Velocity_Control.Stop
            OpServerCallDcm_MainFunction_ReadData_DataServices_Data_Nexteer_IoControl_FD40_Manual_Torque_Command: operation=DataServices_Data_Nexteer_IoControl_FD40_Manual_Torque_Command.ReadData
            OpServerCallDcm_MainFunction_ReadDataLength_DataServices_Data_Nexteer_IoControl_FD40_Manual_Torque_Command: operation=DataServices_Data_Nexteer_IoControl_FD40_Manual_Torque_Command.ReadDataLength
            OpServerCallDcm_MainFunction_ReturnControlToECU_DataServices_Data_Nexteer_IoControl_FD40_Manual_Torque_Command: operation=DataServices_Data_Nexteer_IoControl_FD40_Manual_Torque_Command.ReturnControlToECU
            OpServerCallDcm_MainFunction_ShortTermAdjustment_DataServices_Data_Nexteer_IoControl_FD40_Manual_Torque_Command: operation=DataServices_Data_Nexteer_IoControl_FD40_Manual_Torque_Command.ShortTermAdjustment
            OpServerCallDcm_MainFunction_ReadData_DataServices_Data_Nexteer_IoControl_FD41_Assist_Linear_Gain: operation=DataServices_Data_Nexteer_IoControl_FD41_Assist_Linear_Gain.ReadData
            OpServerCallDcm_MainFunction_ReadDataLength_DataServices_Data_Nexteer_IoControl_FD41_Assist_Linear_Gain: operation=DataServices_Data_Nexteer_IoControl_FD41_Assist_Linear_Gain.ReadDataLength
            OpServerCallDcm_MainFunction_ReturnControlToECU_DataServices_Data_Nexteer_IoControl_FD41_Assist_Linear_Gain: operation=DataServices_Data_Nexteer_IoControl_FD41_Assist_Linear_Gain.ReturnControlToECU
            OpServerCallDcm_MainFunction_ShortTermAdjustment_DataServices_Data_Nexteer_IoControl_FD41_Assist_Linear_Gain: operation=DataServices_Data_Nexteer_IoControl_FD41_Assist_Linear_Gain.ShortTermAdjustment
            OpServerCallDcm_MainFunction_Start_RoutineServices_RTN_Nexteer_F119_Defeat_Duty_Cycle_Thermal_Protection: operation=RoutineServices_RTN_Nexteer_F119_Defeat_Duty_Cycle_Thermal_Protection.Start
            OpServerCallDcm_MainFunction_Stop_RoutineServices_RTN_Nexteer_F119_Defeat_Duty_Cycle_Thermal_Protection: operation=RoutineServices_RTN_Nexteer_F119_Defeat_Duty_Cycle_Thermal_Protection.Stop
            OpServerCallDcm_MainFunction_RequestResults_RoutineServices_RTN_Nexteer_F119_Defeat_Duty_Cycle_Thermal_Protection: operation=RoutineServices_RTN_Nexteer_F119_Defeat_Duty_Cycle_Thermal_Protection.RequestResults
            OpServerCallDcm_MainFunction_Indication_ServiceRequestManufacturerNotification_DcmDslServiceRequestManufacturerNotification: operation=ServiceRequestManufacturerNotification_DcmDslServiceRequestManufacturerNotification.Indication
            OpServerCallDcm_MainFunction_Confirmation_ServiceRequestManufacturerNotification_DcmDslServiceRequestManufacturerNotification: operation=ServiceRequestManufacturerNotification_DcmDslServiceRequestManufacturerNotification.Confirmation
            OpServerCallDcm_MainFunction_GetSeed_SecurityAccess_Un_locked_L1: operation=SecurityAccess_Un_locked_L1.GetSeed
            OpServerCallDcm_MainFunction_CompareKey_SecurityAccess_Un_locked_L1: operation=SecurityAccess_Un_locked_L1.CompareKey
            OpServerCallDcm_MainFunction_ReadData_DataServices_DID_F113_ECU_Delivery_Assembly_Number: operation=DataServices_DID_F113_ECU_Delivery_Assembly_Number.ReadData
            OpServerCallDcm_MainFunction_ConditionCheckRead_DataServices_DID_F113_ECU_Delivery_Assembly_Number: operation=DataServices_DID_F113_ECU_Delivery_Assembly_Number.ConditionCheckRead
            OpServerCallDcm_MainFunction_WriteData_DataServices_DID_F113_ECU_Delivery_Assembly_Number: operation=DataServices_DID_F113_ECU_Delivery_Assembly_Number.WriteData
            OpServerCallDcm_MainFunction_ReadData_DataServices_DID_F111_ECU_Core_Assembly_Number: operation=DataServices_DID_F111_ECU_Core_Assembly_Number.ReadData
            OpServerCallDcm_MainFunction_ConditionCheckRead_DataServices_DID_F111_ECU_Core_Assembly_Number: operation=DataServices_DID_F111_ECU_Core_Assembly_Number.ConditionCheckRead
            OpServerCallDcm_MainFunction_WriteData_DataServices_DID_F111_ECU_Core_Assembly_Number: operation=DataServices_DID_F111_ECU_Core_Assembly_Number.WriteData
            OpServerCallDcm_MainFunction_ReadData_DataServices_DID_DE00_VehicleData: operation=DataServices_DID_DE00_VehicleData.ReadData
            OpServerCallDcm_MainFunction_ConditionCheckRead_DataServices_DID_DE00_VehicleData: operation=DataServices_DID_DE00_VehicleData.ConditionCheckRead
            OpServerCallDcm_MainFunction_WriteData_DataServices_DID_DE00_VehicleData: operation=DataServices_DID_DE00_VehicleData.WriteData
            OpServerCallDcm_MainFunction_ReadData_DataServices_DID_F124_ECU_Calibration_Data_1_Number: operation=DataServices_DID_F124_ECU_Calibration_Data_1_Number.ReadData
            OpServerCallDcm_MainFunction_ConditionCheckRead_DataServices_DID_F124_ECU_Calibration_Data_1_Number: operation=DataServices_DID_F124_ECU_Calibration_Data_1_Number.ConditionCheckRead
            OpServerCallDcm_MainFunction_ReadData_DataServices_DID_DE02_FeatureConfig: operation=DataServices_DID_DE02_FeatureConfig.ReadData
            OpServerCallDcm_MainFunction_ConditionCheckRead_DataServices_DID_DE02_FeatureConfig: operation=DataServices_DID_DE02_FeatureConfig.ConditionCheckRead
            OpServerCallDcm_MainFunction_WriteData_DataServices_DID_DE02_FeatureConfig: operation=DataServices_DID_DE02_FeatureConfig.WriteData
            OpServerCallDcm_MainFunction_ReadData_DataServices_DID_DE01_FIHSwFeatureConfig: operation=DataServices_DID_DE01_FIHSwFeatureConfig.ReadData
            OpServerCallDcm_MainFunction_ConditionCheckRead_DataServices_DID_DE01_FIHSwFeatureConfig: operation=DataServices_DID_DE01_FIHSwFeatureConfig.ConditionCheckRead
            OpServerCallDcm_MainFunction_WriteData_DataServices_DID_DE01_FIHSwFeatureConfig: operation=DataServices_DID_DE01_FIHSwFeatureConfig.WriteData
            OpServerCallDcm_MainFunction_ReadData_DataServices_DID_DE03_Enable_DisableDTCs: operation=DataServices_DID_DE03_Enable_DisableDTCs.ReadData
            OpServerCallDcm_MainFunction_ConditionCheckRead_DataServices_DID_DE03_Enable_DisableDTCs: operation=DataServices_DID_DE03_Enable_DisableDTCs.ConditionCheckRead
            OpServerCallDcm_MainFunction_WriteData_DataServices_DID_DE03_Enable_DisableDTCs: operation=DataServices_DID_DE03_Enable_DisableDTCs.WriteData
            OpServerCallDcm_MainFunction_ReadData_DataServices_DID_EE01_XCP_Enable_Disable: operation=DataServices_DID_EE01_XCP_Enable_Disable.ReadData
            OpServerCallDcm_MainFunction_ConditionCheckRead_DataServices_DID_EE01_XCP_Enable_Disable: operation=DataServices_DID_EE01_XCP_Enable_Disable.ConditionCheckRead
            OpServerCallDcm_MainFunction_WriteData_DataServices_DID_EE01_XCP_Enable_Disable: operation=DataServices_DID_EE01_XCP_Enable_Disable.WriteData
            OpServerCallDcm_MainFunction_ReadData_DataServices_DID_F10A_ECU_Cal_Config_Part_Number: operation=DataServices_DID_F10A_ECU_Cal_Config_Part_Number.ReadData
            OpServerCallDcm_MainFunction_ConditionCheckRead_DataServices_DID_F10A_ECU_Cal_Config_Part_Number: operation=DataServices_DID_F10A_ECU_Cal_Config_Part_Number.ConditionCheckRead
            OpServerCallDcm_MainFunction_ReadData_DataServices_DID_EE02_Assist_On_Off: operation=DataServices_DID_EE02_Assist_On_Off.ReadData
            OpServerCallDcm_MainFunction_ConditionCheckRead_DataServices_DID_EE02_Assist_On_Off: operation=DataServices_DID_EE02_Assist_On_Off.ConditionCheckRead
            OpServerCallDcm_MainFunction_WriteData_DataServices_DID_EE02_Assist_On_Off: operation=DataServices_DID_EE02_Assist_On_Off.WriteData
            OpServerCallDcm_MainFunction_ReadData_DataServices_DID_F188_Vehicle_Manufacturer_ECU_Software_Number: operation=DataServices_DID_F188_Vehicle_Manufacturer_ECU_Software_Number.ReadData
            OpServerCallDcm_MainFunction_ConditionCheckRead_DataServices_DID_F188_Vehicle_Manufacturer_ECU_Software_Number: operation=DataServices_DID_F188_Vehicle_Manufacturer_ECU_Software_Number.ConditionCheckRead
            OpServerCallDcm_MainFunction_ReadData_DataServices_DID_3003_Gear_Hardware_Part_Number: operation=DataServices_DID_3003_Gear_Hardware_Part_Number.ReadData
            OpServerCallDcm_MainFunction_ConditionCheckRead_DataServices_DID_3003_Gear_Hardware_Part_Number: operation=DataServices_DID_3003_Gear_Hardware_Part_Number.ConditionCheckRead
            OpServerCallDcm_MainFunction_ReadData_DataServices_DID_DE04_PDCResetValue: operation=DataServices_DID_DE04_PDCResetValue.ReadData
            OpServerCallDcm_MainFunction_ConditionCheckRead_DataServices_DID_DE04_PDCResetValue: operation=DataServices_DID_DE04_PDCResetValue.ConditionCheckRead
            OpServerCallDcm_MainFunction_WriteData_DataServices_DID_DE04_PDCResetValue: operation=DataServices_DID_DE04_PDCResetValue.WriteData
            OpServerCallDcm_MainFunction_Start_RoutineServices_RTN_Nexteer_FDA2_Handwheel_Torque_Sensor_2_Auto_Trim: operation=RoutineServices_RTN_Nexteer_FDA2_Handwheel_Torque_Sensor_2_Auto_Trim.Start
            OpServerCallDcm_MainFunction_Start_RoutineServices_RTN_Nexteer_FDA3_Handwheel_Torque_Sensor_3_Auto_Trim: operation=RoutineServices_RTN_Nexteer_FDA3_Handwheel_Torque_Sensor_3_Auto_Trim.Start
            OpServerCallDcm_MainFunction_Start_RoutineServices_RTN_Nexteer_FDAA_Handwheel_Torque_Sensor_2_Clear_Trim: operation=RoutineServices_RTN_Nexteer_FDAA_Handwheel_Torque_Sensor_2_Clear_Trim.Start
            OpServerCallDcm_MainFunction_Start_RoutineServices_RTN_Nexteer_FDAB_Handwheel_Torque_Sensor_3_Clear_Trim: operation=RoutineServices_RTN_Nexteer_FDAB_Handwheel_Torque_Sensor_3_Clear_Trim.Start
            OpServerCallDcm_MainFunction_ReadData_DataServices_DID_D100_Active_Diagnostic_Session: operation=DataServices_DID_D100_Active_Diagnostic_Session.ReadData
            OpServerCallDcm_MainFunction_ConditionCheckRead_DataServices_DID_D100_Active_Diagnostic_Session: operation=DataServices_DID_D100_Active_Diagnostic_Session.ConditionCheckRead
            OpServerCallDcm_MainFunction_WriteData_DataServices_DID_3003_Gear_Hardware_Part_Number: operation=DataServices_DID_3003_Gear_Hardware_Part_Number.WriteData
            OpServerCallDcm_MainFunction_ReadData_DataServices_DID_EE40_ResearchMessConfig: operation=DataServices_DID_EE40_ResearchMessConfig.ReadData
            OpServerCallDcm_MainFunction_ConditionCheckRead_DataServices_DID_EE40_ResearchMessConfig: operation=DataServices_DID_EE40_ResearchMessConfig.ConditionCheckRead
            OpServerCallDcm_MainFunction_WriteData_DataServices_DID_EE40_ResearchMessConfig: operation=DataServices_DID_EE40_ResearchMessConfig.WriteData
            OpServerCallDcm_MainFunction_ReadData_DataServices_DID_F163_Diagnostic_Specification_Version: operation=DataServices_DID_F163_Diagnostic_Specification_Version.ReadData
            OpServerCallDcm_MainFunction_ConditionCheckRead_DataServices_DID_F163_Diagnostic_Specification_Version: operation=DataServices_DID_F163_Diagnostic_Specification_Version.ConditionCheckRead
            OpServerCallDcm_MainFunction_WriteData_DataServices_DID_F163_Diagnostic_Specification_Version: operation=DataServices_DID_F163_Diagnostic_Specification_Version.WriteData
            OpServerCallDcm_MainFunction_ReadData_DataServices_DID_EED1_SupplierInternalFaultCode: operation=DataServices_DID_EED1_SupplierInternalFaultCode.ReadData
            OpServerCallDcm_MainFunction_ConditionCheckRead_DataServices_DID_EED1_SupplierInternalFaultCode: operation=DataServices_DID_EED1_SupplierInternalFaultCode.ConditionCheckRead
            OpServerCallDcm_MainFunction_ReadData_DataServices_DID_EE86_FIHSwReserved5: operation=DataServices_DID_EE86_FIHSwReserved5.ReadData
            OpServerCallDcm_MainFunction_ConditionCheckRead_DataServices_DID_EE86_FIHSwReserved5: operation=DataServices_DID_EE86_FIHSwReserved5.ConditionCheckRead
            OpServerCallDcm_MainFunction_WriteData_DataServices_DID_EE86_FIHSwReserved5: operation=DataServices_DID_EE86_FIHSwReserved5.WriteData
            OpServerCallDcm_MainFunction_ReadData_DataServices_DID_F166_NOS_Message_Database_1_Version_Number: operation=DataServices_DID_F166_NOS_Message_Database_1_Version_Number.ReadData
            OpServerCallDcm_MainFunction_ConditionCheckRead_DataServices_DID_F166_NOS_Message_Database_1_Version_Number: operation=DataServices_DID_F166_NOS_Message_Database_1_Version_Number.ConditionCheckRead
            OpServerCallDcm_MainFunction_WriteData_DataServices_DID_F166_NOS_Message_Database_1_Version_Number: operation=DataServices_DID_F166_NOS_Message_Database_1_Version_Number.WriteData
            OpServerCallDcm_MainFunction_ReadData_DataServices_DID_3B4B_Steering_wheel_angle_alignment_offset: operation=DataServices_DID_3B4B_Steering_wheel_angle_alignment_offset.ReadData
            OpServerCallDcm_MainFunction_ConditionCheckRead_DataServices_DID_3B4B_Steering_wheel_angle_alignment_offset: operation=DataServices_DID_3B4B_Steering_wheel_angle_alignment_offset.ConditionCheckRead
            OpServerCallDcm_MainFunction_ReadData_DataServices_DID_EE05_FinalMotTq: operation=DataServices_DID_EE05_FinalMotTq.ReadData
            OpServerCallDcm_MainFunction_ConditionCheckRead_DataServices_DID_EE05_FinalMotTq: operation=DataServices_DID_EE05_FinalMotTq.ConditionCheckRead
            OpServerCallDcm_MainFunction_ReadData_DataServices_DID_D111_ECU_Power_Supply_Voltage: operation=DataServices_DID_D111_ECU_Power_Supply_Voltage.ReadData
            OpServerCallDcm_MainFunction_ConditionCheckRead_DataServices_DID_D111_ECU_Power_Supply_Voltage: operation=DataServices_DID_D111_ECU_Power_Supply_Voltage.ConditionCheckRead
            OpServerCallDcm_MainFunction_ReadData_DataServices_DID_DD01_Total_Distance: operation=DataServices_DID_DD01_Total_Distance.ReadData
            OpServerCallDcm_MainFunction_ConditionCheckRead_DataServices_DID_DD01_Total_Distance: operation=DataServices_DID_DD01_Total_Distance.ConditionCheckRead
            OpServerCallDcm_MainFunction_ReadData_DataServices_DID_330C_Steering_Shaft_Torque_Sensor_2: operation=DataServices_DID_330C_Steering_Shaft_Torque_Sensor_2.ReadData
            OpServerCallDcm_MainFunction_ConditionCheckRead_DataServices_DID_330C_Steering_Shaft_Torque_Sensor_2: operation=DataServices_DID_330C_Steering_Shaft_Torque_Sensor_2.ConditionCheckRead
            OpServerCallDcm_MainFunction_ReadData_DataServices_DID_205B_Brake_Pull_Reduction_Activation_Counter: operation=DataServices_DID_205B_Brake_Pull_Reduction_Activation_Counter.ReadData
            OpServerCallDcm_MainFunction_ConditionCheckRead_DataServices_DID_205B_Brake_Pull_Reduction_Activation_Counter: operation=DataServices_DID_205B_Brake_Pull_Reduction_Activation_Counter.ConditionCheckRead
            OpServerCallDcm_MainFunction_WriteData_DataServices_DID_205B_Brake_Pull_Reduction_Activation_Counter: operation=DataServices_DID_205B_Brake_Pull_Reduction_Activation_Counter.WriteData
            OpServerCallDcm_MainFunction_ReadData_DataServices_DID_EE80_FIHSwVer: operation=DataServices_DID_EE80_FIHSwVer.ReadData
            OpServerCallDcm_MainFunction_ConditionCheckRead_DataServices_DID_EE80_FIHSwVer: operation=DataServices_DID_EE80_FIHSwVer.ConditionCheckRead
            OpServerCallDcm_MainFunction_ReadData_DataServices_DID_F162_Software_Download_Specification_Version: operation=DataServices_DID_F162_Software_Download_Specification_Version.ReadData
            OpServerCallDcm_MainFunction_ConditionCheckRead_DataServices_DID_F162_Software_Download_Specification_Version: operation=DataServices_DID_F162_Software_Download_Specification_Version.ConditionCheckRead
            OpServerCallDcm_MainFunction_WriteData_DataServices_DID_F162_Software_Download_Specification_Version: operation=DataServices_DID_F162_Software_Download_Specification_Version.WriteData
            OpServerCallDcm_MainFunction_ReadData_DataServices_DID_F180_Boot_Software_Identification: operation=DataServices_DID_F180_Boot_Software_Identification.ReadData
            OpServerCallDcm_MainFunction_ConditionCheckRead_DataServices_DID_F180_Boot_Software_Identification: operation=DataServices_DID_F180_Boot_Software_Identification.ConditionCheckRead
            OpServerCallDcm_MainFunction_ReadData_DataServices_DID_D117_ECU_Internal_Temperature: operation=DataServices_DID_D117_ECU_Internal_Temperature.ReadData
            OpServerCallDcm_MainFunction_ConditionCheckRead_DataServices_DID_D117_ECU_Internal_Temperature: operation=DataServices_DID_D117_ECU_Internal_Temperature.ConditionCheckRead
            OpServerCallDcm_MainFunction_ReadData_DataServices_DID_205A_Torque_Steer_Compensation_Activation_Counter: operation=DataServices_DID_205A_Torque_Steer_Compensation_Activation_Counter.ReadData
            OpServerCallDcm_MainFunction_ConditionCheckRead_DataServices_DID_205A_Torque_Steer_Compensation_Activation_Counter: operation=DataServices_DID_205A_Torque_Steer_Compensation_Activation_Counter.ConditionCheckRead
            OpServerCallDcm_MainFunction_WriteData_DataServices_DID_205A_Torque_Steer_Compensation_Activation_Counter: operation=DataServices_DID_205A_Torque_Steer_Compensation_Activation_Counter.WriteData
            OpServerCallDcm_MainFunction_ReadData_DataServices_DID_EE87_FIHSwReserved6: operation=DataServices_DID_EE87_FIHSwReserved6.ReadData
            OpServerCallDcm_MainFunction_ConditionCheckRead_DataServices_DID_EE87_FIHSwReserved6: operation=DataServices_DID_EE87_FIHSwReserved6.ConditionCheckRead
            OpServerCallDcm_MainFunction_WriteData_DataServices_DID_EE87_FIHSwReserved6: operation=DataServices_DID_EE87_FIHSwReserved6.WriteData
            OpServerCallDcm_MainFunction_ReadData_DataServices_DID_630F_Multiple_VIN_Storage_Original_VIN: operation=DataServices_DID_630F_Multiple_VIN_Storage_Original_VIN.ReadData
            OpServerCallDcm_MainFunction_ConditionCheckRead_DataServices_DID_630F_Multiple_VIN_Storage_Original_VIN: operation=DataServices_DID_630F_Multiple_VIN_Storage_Original_VIN.ConditionCheckRead
            OpServerCallDcm_MainFunction_ReadData_DataServices_DID_F110_Subsystem_Specific_Diagnostic_Specification_Part_Number: operation=DataServices_DID_F110_Subsystem_Specific_Diagnostic_Specification_Part_Number.ReadData
            OpServerCallDcm_MainFunction_ConditionCheckRead_DataServices_DID_F110_Subsystem_Specific_Diagnostic_Specification_Part_Number: operation=DataServices_DID_F110_Subsystem_Specific_Diagnostic_Specification_Part_Number.ConditionCheckRead
            OpServerCallDcm_MainFunction_WriteData_DataServices_DID_F110_Subsystem_Specific_Diagnostic_Specification_Part_Number: operation=DataServices_DID_F110_Subsystem_Specific_Diagnostic_Specification_Part_Number.WriteData
            OpServerCallDcm_MainFunction_ReadData_DataServices_DID_EE42_ActiveFeatures: operation=DataServices_DID_EE42_ActiveFeatures.ReadData
            OpServerCallDcm_MainFunction_ConditionCheckRead_DataServices_DID_EE42_ActiveFeatures: operation=DataServices_DID_EE42_ActiveFeatures.ConditionCheckRead
            OpServerCallDcm_MainFunction_ReadData_DataServices_DID_EE22_VoltageLvlCounters: operation=DataServices_DID_EE22_VoltageLvlCounters.ReadData
            OpServerCallDcm_MainFunction_ConditionCheckRead_DataServices_DID_EE22_VoltageLvlCounters: operation=DataServices_DID_EE22_VoltageLvlCounters.ConditionCheckRead
            OpServerCallDcm_MainFunction_ReadData_DataServices_DID_EE03_IgnCycleCounter: operation=DataServices_DID_EE03_IgnCycleCounter.ReadData
            OpServerCallDcm_MainFunction_ConditionCheckRead_DataServices_DID_EE03_IgnCycleCounter: operation=DataServices_DID_EE03_IgnCycleCounter.ConditionCheckRead
            OpServerCallDcm_MainFunction_ReadData_DataServices_DID_301A_Pull_Drift_Compensation_Value: operation=DataServices_DID_301A_Pull_Drift_Compensation_Value.ReadData
            OpServerCallDcm_MainFunction_ConditionCheckRead_DataServices_DID_301A_Pull_Drift_Compensation_Value: operation=DataServices_DID_301A_Pull_Drift_Compensation_Value.ConditionCheckRead
            OpServerCallDcm_MainFunction_WriteData_DataServices_DID_301A_Pull_Drift_Compensation_Value: operation=DataServices_DID_301A_Pull_Drift_Compensation_Value.WriteData
            OpServerCallDcm_MainFunction_ReadData_DataServices_DID_EE83_FIHSwReserved2: operation=DataServices_DID_EE83_FIHSwReserved2.ReadData
            OpServerCallDcm_MainFunction_ConditionCheckRead_DataServices_DID_EE83_FIHSwReserved2: operation=DataServices_DID_EE83_FIHSwReserved2.ConditionCheckRead
            OpServerCallDcm_MainFunction_WriteData_DataServices_DID_EE83_FIHSwReserved2: operation=DataServices_DID_EE83_FIHSwReserved2.WriteData
            OpServerCallDcm_MainFunction_ReadData_DataServices_DID_F190_Vehicle_Identification_Number: operation=DataServices_DID_F190_Vehicle_Identification_Number.ReadData
            OpServerCallDcm_MainFunction_ConditionCheckRead_DataServices_DID_F190_Vehicle_Identification_Number: operation=DataServices_DID_F190_Vehicle_Identification_Number.ConditionCheckRead
            OpServerCallDcm_MainFunction_ReadData_DataServices_DID_EE00_DevMessConfig: operation=DataServices_DID_EE00_DevMessConfig.ReadData
            OpServerCallDcm_MainFunction_ConditionCheckRead_DataServices_DID_EE00_DevMessConfig: operation=DataServices_DID_EE00_DevMessConfig.ConditionCheckRead
            OpServerCallDcm_MainFunction_WriteData_DataServices_DID_EE00_DevMessConfig: operation=DataServices_DID_EE00_DevMessConfig.WriteData
            OpServerCallDcm_MainFunction_ReadData_DataServices_DID_3020_Steering_Pinion_Angle: operation=DataServices_DID_3020_Steering_Pinion_Angle.ReadData
            OpServerCallDcm_MainFunction_ConditionCheckRead_DataServices_DID_3020_Steering_Pinion_Angle: operation=DataServices_DID_3020_Steering_Pinion_Angle.ConditionCheckRead
            OpServerCallDcm_MainFunction_ReadData_DataServices_DID_EE07_EPSSystemState: operation=DataServices_DID_EE07_EPSSystemState.ReadData
            OpServerCallDcm_MainFunction_ConditionCheckRead_DataServices_DID_EE07_EPSSystemState: operation=DataServices_DID_EE07_EPSSystemState.ConditionCheckRead
            OpServerCallDcm_MainFunction_ReadData_DataServices_DID_EE23_TempLvlCounters: operation=DataServices_DID_EE23_TempLvlCounters.ReadData
            OpServerCallDcm_MainFunction_ConditionCheckRead_DataServices_DID_EE23_TempLvlCounters: operation=DataServices_DID_EE23_TempLvlCounters.ConditionCheckRead
            OpServerCallDcm_MainFunction_ReadData_DataServices_DID_DD09_Vehicle_Speed: operation=DataServices_DID_DD09_Vehicle_Speed.ReadData
            OpServerCallDcm_MainFunction_ConditionCheckRead_DataServices_DID_DD09_Vehicle_Speed: operation=DataServices_DID_DD09_Vehicle_Speed.ConditionCheckRead
            OpServerCallDcm_MainFunction_ReadData_DataServices_DID_EE21_CurrentLvlCounter: operation=DataServices_DID_EE21_CurrentLvlCounter.ReadData
            OpServerCallDcm_MainFunction_ConditionCheckRead_DataServices_DID_EE21_CurrentLvlCounter: operation=DataServices_DID_EE21_CurrentLvlCounter.ConditionCheckRead
            OpServerCallDcm_MainFunction_ReadData_DataServices_DID_301F_Steering_Pinion_Rotation_Speed: operation=DataServices_DID_301F_Steering_Pinion_Rotation_Speed.ReadData
            OpServerCallDcm_MainFunction_ConditionCheckRead_DataServices_DID_301F_Steering_Pinion_Rotation_Speed: operation=DataServices_DID_301F_Steering_Pinion_Rotation_Speed.ConditionCheckRead
            OpServerCallDcm_MainFunction_ReadData_DataServices_DID_F18A_System_Supplier_Identifier: operation=DataServices_DID_F18A_System_Supplier_Identifier.ReadData
            OpServerCallDcm_MainFunction_ConditionCheckRead_DataServices_DID_F18A_System_Supplier_Identifier: operation=DataServices_DID_F18A_System_Supplier_Identifier.ConditionCheckRead
            OpServerCallDcm_MainFunction_WriteData_DataServices_DID_F18A_System_Supplier_Identifier: operation=DataServices_DID_F18A_System_Supplier_Identifier.WriteData
            OpServerCallDcm_MainFunction_ReadData_DataServices_DID_F18C_ECU_Serial_Number: operation=DataServices_DID_F18C_ECU_Serial_Number.ReadData
            OpServerCallDcm_MainFunction_ConditionCheckRead_DataServices_DID_F18C_ECU_Serial_Number: operation=DataServices_DID_F18C_ECU_Serial_Number.ConditionCheckRead
            OpServerCallDcm_MainFunction_WriteData_DataServices_DID_F18C_ECU_Serial_Number: operation=DataServices_DID_F18C_ECU_Serial_Number.WriteData
            OpServerCallDcm_MainFunction_ReadData_DataServices_DID_EE82_FIHSwReserved1: operation=DataServices_DID_EE82_FIHSwReserved1.ReadData
            OpServerCallDcm_MainFunction_ConditionCheckRead_DataServices_DID_EE82_FIHSwReserved1: operation=DataServices_DID_EE82_FIHSwReserved1.ConditionCheckRead
            OpServerCallDcm_MainFunction_WriteData_DataServices_DID_EE82_FIHSwReserved1: operation=DataServices_DID_EE82_FIHSwReserved1.WriteData
            OpServerCallDcm_MainFunction_ReadData_DataServices_DID_EE84_FIHSwReserved3: operation=DataServices_DID_EE84_FIHSwReserved3.ReadData
            OpServerCallDcm_MainFunction_ConditionCheckRead_DataServices_DID_EE84_FIHSwReserved3: operation=DataServices_DID_EE84_FIHSwReserved3.ConditionCheckRead
            OpServerCallDcm_MainFunction_WriteData_DataServices_DID_EE84_FIHSwReserved3: operation=DataServices_DID_EE84_FIHSwReserved3.WriteData
            OpServerCallDcm_MainFunction_ReadData_DataServices_DID_EE20_LoAFaultReporting: operation=DataServices_DID_EE20_LoAFaultReporting.ReadData
            OpServerCallDcm_MainFunction_ConditionCheckRead_DataServices_DID_EE20_LoAFaultReporting: operation=DataServices_DID_EE20_LoAFaultReporting.ConditionCheckRead
            OpServerCallDcm_MainFunction_ReadData_DataServices_DID_EE81_FIHSwReserved0: operation=DataServices_DID_EE81_FIHSwReserved0.ReadData
            OpServerCallDcm_MainFunction_ConditionCheckRead_DataServices_DID_EE81_FIHSwReserved0: operation=DataServices_DID_EE81_FIHSwReserved0.ConditionCheckRead
            OpServerCallDcm_MainFunction_WriteData_DataServices_DID_EE81_FIHSwReserved0: operation=DataServices_DID_EE81_FIHSwReserved0.WriteData
            OpServerCallDcm_MainFunction_ReadData_DataServices_DID_F15F_NOS_Generation_Tool_Version_Number: operation=DataServices_DID_F15F_NOS_Generation_Tool_Version_Number.ReadData
            OpServerCallDcm_MainFunction_ConditionCheckRead_DataServices_DID_F15F_NOS_Generation_Tool_Version_Number: operation=DataServices_DID_F15F_NOS_Generation_Tool_Version_Number.ConditionCheckRead
            OpServerCallDcm_MainFunction_ReadData_DataServices_DID_EE06_VINChanged: operation=DataServices_DID_EE06_VINChanged.ReadData
            OpServerCallDcm_MainFunction_ConditionCheckRead_DataServices_DID_EE06_VINChanged: operation=DataServices_DID_EE06_VINChanged.ConditionCheckRead
            OpServerCallDcm_MainFunction_ReadData_DataServices_DID_DD00_Global_Real_Time: operation=DataServices_DID_DD00_Global_Real_Time.ReadData
            OpServerCallDcm_MainFunction_ConditionCheckRead_DataServices_DID_DD00_Global_Real_Time: operation=DataServices_DID_DD00_Global_Real_Time.ConditionCheckRead
            OpServerCallDcm_MainFunction_ReadData_DataServices_DID_EE04_IgnOnTime: operation=DataServices_DID_EE04_IgnOnTime.ReadData
            OpServerCallDcm_MainFunction_ConditionCheckRead_DataServices_DID_EE04_IgnOnTime: operation=DataServices_DID_EE04_IgnOnTime.ConditionCheckRead
            OpServerCallDcm_MainFunction_ReadData_DataServices_DID_EE88_FIHSwReserved7: operation=DataServices_DID_EE88_FIHSwReserved7.ReadData
            OpServerCallDcm_MainFunction_ConditionCheckRead_DataServices_DID_EE88_FIHSwReserved7: operation=DataServices_DID_EE88_FIHSwReserved7.ConditionCheckRead
            OpServerCallDcm_MainFunction_WriteData_DataServices_DID_EE88_FIHSwReserved7: operation=DataServices_DID_EE88_FIHSwReserved7.WriteData
            OpServerCallDcm_MainFunction_ReadData_DataServices_DID_EE41_ResearchFeatureSwitch: operation=DataServices_DID_EE41_ResearchFeatureSwitch.ReadData
            OpServerCallDcm_MainFunction_ConditionCheckRead_DataServices_DID_EE41_ResearchFeatureSwitch: operation=DataServices_DID_EE41_ResearchFeatureSwitch.ConditionCheckRead
            OpServerCallDcm_MainFunction_WriteData_DataServices_DID_EE41_ResearchFeatureSwitch: operation=DataServices_DID_EE41_ResearchFeatureSwitch.WriteData
            OpServerCallDcm_MainFunction_ReadData_DataServices_DID_EE85_FIHSwReserved4: operation=DataServices_DID_EE85_FIHSwReserved4.ReadData
            OpServerCallDcm_MainFunction_ConditionCheckRead_DataServices_DID_EE85_FIHSwReserved4: operation=DataServices_DID_EE85_FIHSwReserved4.ConditionCheckRead
            OpServerCallDcm_MainFunction_WriteData_DataServices_DID_EE85_FIHSwReserved4: operation=DataServices_DID_EE85_FIHSwReserved4.WriteData
            OpServerCallDcm_MainFunction_ReadData_DataServices_DID_D118_Motor_Current: operation=DataServices_DID_D118_Motor_Current.ReadData
            OpServerCallDcm_MainFunction_ConditionCheckRead_DataServices_DID_D118_Motor_Current: operation=DataServices_DID_D118_Motor_Current.ConditionCheckRead
            OpServerCallDcm_MainFunction_ReadData_DataServices_DID_EED0_SupplierFactoryMode: operation=DataServices_DID_EED0_SupplierFactoryMode.ReadData
            OpServerCallDcm_MainFunction_ConditionCheckRead_DataServices_DID_EED0_SupplierFactoryMode: operation=DataServices_DID_EED0_SupplierFactoryMode.ConditionCheckRead
            OpServerCallDcm_MainFunction_WriteData_DataServices_DID_EED0_SupplierFactoryMode: operation=DataServices_DID_EED0_SupplierFactoryMode.WriteData
            OpServerCallDcm_MainFunction_ReadData_DataServices_DID_EE43_SDMSteeringMode: operation=DataServices_DID_EE43_SDMSteeringMode.ReadData
            OpServerCallDcm_MainFunction_ConditionCheckRead_DataServices_DID_EE43_SDMSteeringMode: operation=DataServices_DID_EE43_SDMSteeringMode.ConditionCheckRead
            OpServerCallDcm_MainFunction_ReadData_DataServices_DID_F17C_NOS_Bootloader_Generation_Tool_Version_Number: operation=DataServices_DID_F17C_NOS_Bootloader_Generation_Tool_Version_Number.ReadData
            OpServerCallDcm_MainFunction_ConditionCheckRead_DataServices_DID_F17C_NOS_Bootloader_Generation_Tool_Version_Number: operation=DataServices_DID_F17C_NOS_Bootloader_Generation_Tool_Version_Number.ConditionCheckRead
            OpServerCallDcm_MainFunction_ReadData_DataServices_DID_DE05_Unused: operation=DataServices_DID_DE05_Unused.ReadData
            OpServerCallDcm_MainFunction_ConditionCheckRead_DataServices_DID_DE05_Unused: operation=DataServices_DID_DE05_Unused.ConditionCheckRead
            OpServerCallDcm_MainFunction_WriteData_DataServices_DID_DE05_Unused: operation=DataServices_DID_DE05_Unused.WriteData
            OpServerCallDcm_MainFunction_ReadDidData_DataServices_DIDRange_NexteerDidRangeF194toF1FF: operation=DataServices_DIDRange_NexteerDidRangeF194toF1FF.ReadDidData
            OpServerCallDcm_MainFunction_WriteDidData_DataServices_DIDRange_NexteerDidRangeF194toF1FF: operation=DataServices_DIDRange_NexteerDidRangeF194toF1FF.WriteDidData
            OpServerCallDcm_MainFunction_Start_RoutineServices_RTN_Nexteer_F200_Micro_Diagnostic_Fault_Injection: operation=RoutineServices_RTN_Nexteer_F200_Micro_Diagnostic_Fault_Injection.Start
            OpServerCallDcm_MainFunction_GetSeed_SecurityAccess_Un_locked_L3: operation=SecurityAccess_Un_locked_L3.GetSeed
            OpServerCallDcm_MainFunction_CompareKey_SecurityAccess_Un_locked_L3: operation=SecurityAccess_Un_locked_L3.CompareKey
            OpServerCallDcm_MainFunction_Start_RoutineServices_RTN_0202_On_Demand_Self_Test: operation=RoutineServices_RTN_0202_On_Demand_Self_Test.Start
            OpServerCallDcm_MainFunction_Stop_RoutineServices_RTN_0202_On_Demand_Self_Test: operation=RoutineServices_RTN_0202_On_Demand_Self_Test.Stop
            OpServerCallDcm_MainFunction_RequestResults_RoutineServices_RTN_0202_On_Demand_Self_Test: operation=RoutineServices_RTN_0202_On_Demand_Self_Test.RequestResults
            OpServerCallDcm_MainFunction_Start_RoutineServices_RTN_200E_Calibrate_Steering_Angle_Centre_Position: operation=RoutineServices_RTN_200E_Calibrate_Steering_Angle_Centre_Position.Start
            OpServerCallDcm_MainFunction_Start_RoutineServices_RTN_200F_Clear_Steering_Angle_Centre_Position_Calibration: operation=RoutineServices_RTN_200F_Clear_Steering_Angle_Centre_Position_Calibration.Start
            OpServerCallDcm_MainFunction_Start_RoutineServices_RTN_DC00_Reset_Assist_Fault_Counters: operation=RoutineServices_RTN_DC00_Reset_Assist_Fault_Counters.Start
            OpServerCallDcm_MainFunction_ReadData_DataServices_DID_EED2_SupplierInternalErrorMemory: operation=DataServices_DID_EED2_SupplierInternalErrorMemory.ReadData
            OpServerCallDcm_MainFunction_ConditionCheckRead_DataServices_DID_EED2_SupplierInternalErrorMemory: operation=DataServices_DID_EED2_SupplierInternalErrorMemory.ConditionCheckRead
            OpServerCallDcm_MainFunction_Start_RoutineServices_RTN_Nexteer_FD54_Clear_Stack_Measurement_Result: operation=RoutineServices_RTN_Nexteer_FD54_Clear_Stack_Measurement_Result.Start
            OpServerCallDcm_MainFunction_Start_RoutineServices_RTN_Nexteer_FD71_Clear_Nexteer_Snapshot_Data_Start: operation=RoutineServices_RTN_Nexteer_FD71_Clear_Nexteer_Snapshot_Data_Start.Start
            OpServerCallDcm_MainFunction_Start_RoutineServices_RTN_Nexteer_FE88_System_Friction_Learning_Clear: operation=RoutineServices_RTN_Nexteer_FE88_System_Friction_Learning_Clear.Start
            OpServerCallDcm_MainFunction_Start_RoutineServices_RTN_Nexteer_FE89_System_Friction_Learning_Initialize: operation=RoutineServices_RTN_Nexteer_FE89_System_Friction_Learning_Initialize.Start
        GetActiveProtocol: can-be-invoked-concurrently=true, symbol=Dcm_GetActiveProtocol
        GetSesCtrlType: can-be-invoked-concurrently=true, symbol=Dcm_GetSesCtrlType
        ResetToDefaultSession: can-be-invoked-concurrently=true, symbol=Dcm_ResetToDefaultSession
        SetActiveDiagnostic: can-be-invoked-concurrently=true, symbol=Dcm_SetActiveDiagnostic
        GetRequestKind: can-be-invoked-concurrently=true, symbol=Dcm_GetRequestKind
        GetSecurityLevel: can-be-invoked-concurrently=true, symbol=Dcm_GetSecurityLevel
        GetSecurityLevelFixedBytes: can-be-invoked-concurrently=true, symbol=Dcm_GetSecurityLevelFixedBytes
  swc implementation DcmImplementation: programming-language=C, behavior=DcmInternalBehavior
